VERSION ""

NS_ :

BS_:

BU_: TM

BO_ 370 BRAKE2: 8 Vector__XXX
 SG_ AebIntervention : 48|1@0+ (1,0) [0|1] ""  TM
 SG_ RCrankEnableStatus : 61|2@0+ (1,0) [0|3] ""  TM
 SG_ RCrankEnable : 0|1@0+ (1,0) [0|1] ""  TM
 SG_ BrkLightSig2Status : 59|2@0+ (1,0) [0|3] ""  TM
 SG_ BrkLightSig2 : 57|2@0+ (1,0) [0|3] ""  TM
 SG_ ABsActive : 1|1@0+ (1,0) [0|1] ""  TM
 SG_ TCsStatus : 3|2@0+ (1,0) [0|3] ""  TM
 SG_ TCsActive : 4|1@0+ (1,0) [0|1] ""  TM
 SG_ ESpStatus : 6|2@0+ (1,0) [0|3] ""  TM
 SG_ ESpActive : 7|1@0+ (1,0) [0|1] ""  TM
 SG_ NoGearshiftReqStatus : 9|2@0+ (1,0) [0|3] ""  TM
 SG_ NoGearshiftReq : 10|1@0+ (1,0) [0|1] ""  TM
 SG_ EBdStatus : 12|2@0+ (1,0) [0|3] ""  TM
 SG_ EBdActive : 13|1@0+ (1,0) [0|1] ""  TM
 SG_ ABsStatus : 15|2@0+ (1,0) [0|3] ""  TM
 SG_ CardanTrqLim : 23|14@0+ (0.25,-2048) [-2048|2047.75] "Nm"  TM
 SG_ CardanTrqLimStatus : 25|2@0+ (1,0) [0|3] ""  TM
 SG_ VehSpdSetHDC : 39|8@0+ (1,0) [0|254] "km"  TM
 SG_ HHcStatus : 41|2@0+ (1,0) [0|3] ""  TM
 SG_ BrkLightSigStatus : 43|2@0+ (1,0) [0|3] ""  TM
 SG_ BrkLightSig : 44|1@0+ (1,0) [0|1] ""  TM
 SG_ CruiseCntShutESPStatus : 46|2@0+ (1,0) [0|3] ""  TM
 SG_ CruiseCntShutESP : 47|1@0+ (1,0) [0|1] ""  TM
 SG_ HDcAvailability : 49|1@0+ (1,0) [0|1] ""  TM
 SG_ VehSpdSetHDCStatus : 51|2@0+ (1,0) [0|3] ""  TM
 SG_ HHcActive : 52|1@0+ (1,0) [0|1] ""  TM
 SG_ HDcActive : 53|1@0+ (1,0) [0|1] ""  TM
 SG_ HDcStatus : 55|2@0+ (1,0) [0|3] ""  TM

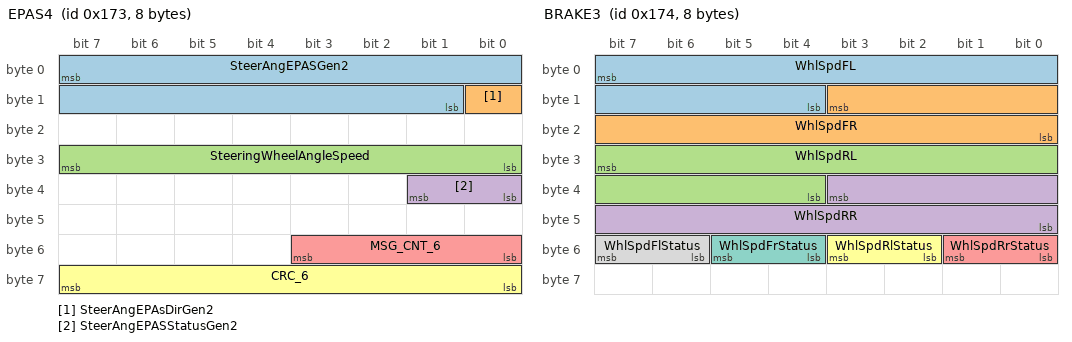
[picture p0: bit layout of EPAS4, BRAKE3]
BO_ 371 EPAS4: 8 Vector__XXX
 SG_ SteerAngEPASGen2 : 7|15@0+ (0.04375,0) [0|1433.55625] " deg"  TM
 SG_ SteerAngEPAsDirGen2 : 8|1@0+ (1,0) [0|1] ""  TM
 SG_ SteeringWheelAngleSpeed : 31|8@0+ (4,0) [0|255] "deg/s"  TM
 SG_ SteerAngEPASStatusGen2 : 33|2@0+ (1,0) [0|3] ""  TM
 SG_ MSG_CNT_6 : 51|4@0+ (1,0) [0|15] ""  TM
 SG_ CRC_6 : 63|8@0+ (1,0) [0|255] ""  TM

BO_ 372 BRAKE3: 8 Vector__XXX
 SG_ WhlSpdFL : 7|12@0+ (1,0) [0|4095] "rpm"  TM
 SG_ WhlSpdFR : 11|12@0+ (1,0) [0|4095] "rpm"  TM
 SG_ WhlSpdRL : 31|12@0+ (1,0) [0|4095] "rpm"  TM
 SG_ WhlSpdRR : 35|12@0+ (1,0) [0|4095] "rpm"  TM
 SG_ WhlSpdRrStatus : 49|2@0+ (1,0) [0|3] ""  TM
 SG_ WhlSpdRlStatus : 51|2@0+ (1,0) [0|3] ""  TM
 SG_ WhlSpdFrStatus : 53|2@0+ (1,0) [0|3] ""  TM
 SG_ WhlSpdFlStatus : 55|2@0+ (1,0) [0|3] ""  TM

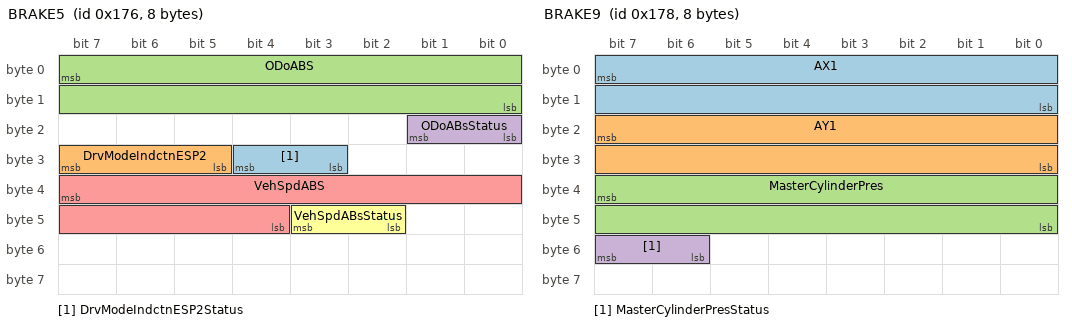
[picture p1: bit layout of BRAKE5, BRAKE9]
BO_ 374 BRAKE5: 8 Vector__XXX
 SG_ DrvModeIndctnESP2Status : 28|2@0+ (1,0) [0|3] ""  TM
 SG_ DrvModeIndctnESP2 : 31|3@0+ (1,0) [0|7] ""  TM
 SG_ ODoABS : 7|16@0+ (1,0) [0|65534] "m"  TM
 SG_ ODoABsStatus : 17|2@0+ (1,0) [0|3] ""  TM
 SG_ VehSpdABS : 39|12@0+ (0.03125,0) [0|127.96875] "m/s"  TM
 SG_ VehSpdABsStatus : 43|2@0+ (1,0) [0|3] ""  TM

BO_ 376 BRAKE9: 8 Vector__XXX
 SG_ AX1 : 7|16@0+ (0.0001,-3.2768) [-3.2768|3.2767] "g"  TM
 SG_ AY1 : 23|16@0+ (0.0001,-3.2768) [-3.2768|3.2767] "g"  TM
 SG_ MasterCylinderPres : 39|16@0+ (0.05,-40) [-40|400] "bar"  TM
 SG_ MasterCylinderPresStatus : 55|2@0+ (1,0) [0|3] ""  TM

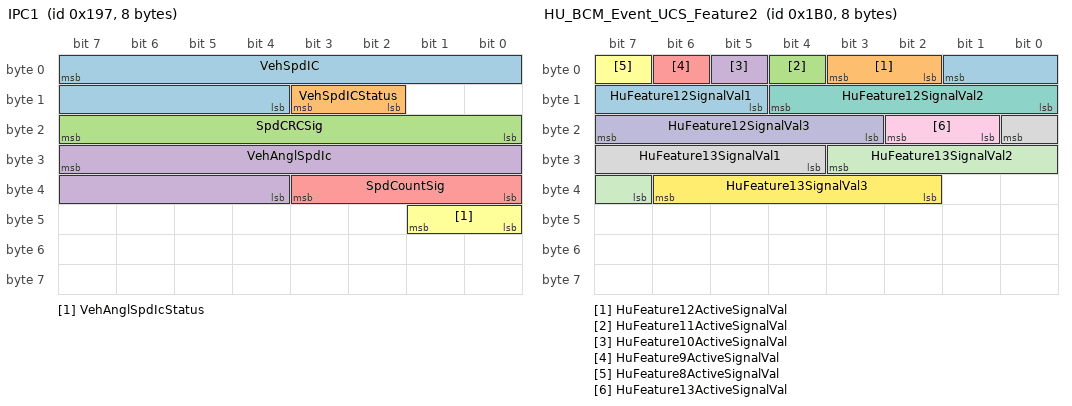
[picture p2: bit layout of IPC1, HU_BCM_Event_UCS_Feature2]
BO_ 407 IPC1: 8 Vector__XXX
 SG_ VehSpdIC : 7|12@0+ (0.03125,0) [0|127.96875] "m/s"  TM
 SG_ VehSpdICStatus : 11|2@0+ (1,0) [0|3] ""  TM
 SG_ SpdCRCSig : 23|8@0+ (1,0) [0|255] ""  TM
 SG_ VehAnglSpdIc : 31|12@0+ (1,0) [0|4095] "rpm"  TM
 SG_ SpdCountSig : 35|4@0+ (1,0) [0|15] ""  TM
 SG_ VehAnglSpdIcStatus : 41|2@0+ (1,0) [0|3] ""  TM

BO_ 432 HU_BCM_Event_UCS_Feature2: 8 Vector__XXX
 SG_ HuFeature12SignalVal1 : 1|5@0+ (10,0) [0|310] ""  TM
 SG_ HuFeature12ActiveSignalVal : 3|2@0+ (1,0) [0|3] ""  TM
 SG_ HuFeature11ActiveSignalVal : 4|1@0+ (1,0) [0|1] ""  TM
 SG_ HuFeature10ActiveSignalVal : 5|1@0+ (1,0) [0|1] ""  TM
 SG_ HuFeature9ActiveSignalVal : 6|1@0+ (1,0) [0|1] ""  TM
 SG_ HuFeature8ActiveSignalVal : 7|1@0+ (1,0) [0|1] ""  TM
 SG_ HuFeature12SignalVal2 : 12|5@0+ (10,0) [0|310] ""  TM
 SG_ HuFeature13SignalVal1 : 16|5@0+ (10,0) [0|310] ""  TM
 SG_ HuFeature13ActiveSignalVal : 18|2@0+ (1,0) [0|3] ""  TM
 SG_ HuFeature12SignalVal3 : 23|5@0+ (10,0) [0|310] ""  TM
 SG_ HuFeature13SignalVal2 : 27|5@0+ (10,0) [0|310] ""  TM
 SG_ HuFeature13SignalVal3 : 38|5@0+ (10,0) [0|310] ""  TM

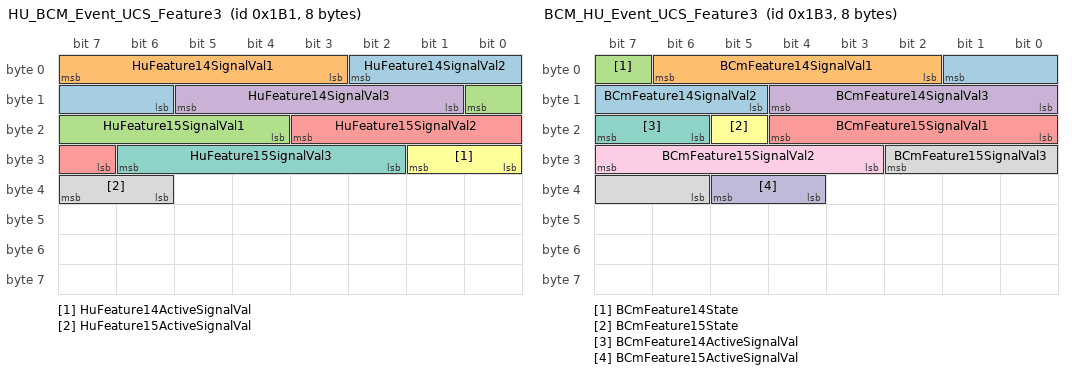
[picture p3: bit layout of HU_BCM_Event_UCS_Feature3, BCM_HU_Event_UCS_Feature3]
BO_ 433 HU_BCM_Event_UCS_Feature3: 8 Vector__XXX
 SG_ HuFeature14SignalVal2 : 2|5@0+ (10,0) [0|310] ""  TM
 SG_ HuFeature14SignalVal1 : 7|5@0+ (10,0) [0|310] ""  TM
 SG_ HuFeature15SignalVal1 : 8|5@0+ (10,0) [0|310] ""  TM
 SG_ HuFeature14SignalVal3 : 13|5@0+ (10,0) [0|310] ""  TM
 SG_ HuFeature15SignalVal2 : 19|5@0+ (10,0) [0|310] ""  TM
 SG_ HuFeature14ActiveSignalVal : 25|2@0+ (1,0) [0|3] ""  TM
 SG_ HuFeature15SignalVal3 : 30|5@0+ (10,0) [0|310] ""  TM
 SG_ HuFeature15ActiveSignalVal : 39|2@0+ (1,0) [0|3] ""  TM

BO_ 434 BCM_HU_Event_UCS_Feature2: 8 Vector__XXX
 SG_ BCmFeature11ActiveSignalVal : 0|1@0+ (1,0) [0|1] ""  TM
 SG_ BCmFeature11State : 1|1@0+ (1,0) [0|1] ""  TM
 SG_ BCmFeature10ActiveSignalVal : 2|1@0+ (1,0) [0|1] ""  TM
 SG_ BCmFeature10State : 3|1@0+ (1,0) [0|1] ""  TM
 SG_ BCmFeature9ActiveSignalVal : 4|1@0+ (1,0) [0|1] ""  TM
 SG_ BCmFeature9State : 5|1@0+ (1,0) [0|1] ""  TM
 SG_ BCmFeature8ActiveSignalVal : 6|1@0+ (1,0) [0|1] ""  TM
 SG_ BCmFeature8State : 7|1@0+ (1,0) [0|1] ""  TM
 SG_ BCmFeature12SignalVal2 : 9|5@0+ (10,0) [0|310] ""  TM
 SG_ BCmFeature12SignalVal1 : 14|5@0+ (10,0) [0|310] ""  TM
 SG_ BCmFeature12State : 15|1@0+ (1,0) [0|1] ""  TM
 SG_ BCmFeature12SignalVal3 : 20|5@0+ (10,0) [0|310] ""  TM
 SG_ BCmFeature13SignalVal1 : 28|5@0+ (10,0) [0|310] ""  TM
 SG_ BCmFeature13State : 29|1@0+ (1,0) [0|1] ""  TM
 SG_ BCmFeature12ActiveSignalVal : 31|2@0+ (1,0) [0|3] ""  TM
 SG_ BCmFeature13SignalVal3 : 34|5@0+ (10,0) [0|310] ""  TM
 SG_ BCmFeature13SignalVal2 : 39|5@0+ (10,0) [0|310] ""  TM
 SG_ BCmFeature13ActiveSignalVal : 45|2@0+ (1,0) [0|3] ""  TM

BO_ 435 BCM_HU_Event_UCS_Feature3: 8 Vector__XXX
 SG_ BCmFeature14SignalVal2 : 1|5@0+ (10,0) [0|310] ""  TM
 SG_ BCmFeature14SignalVal1 : 6|5@0+ (10,0) [0|310] ""  TM
 SG_ BCmFeature14State : 7|1@0+ (1,0) [0|1] ""  TM
 SG_ BCmFeature14SignalVal3 : 12|5@0+ (10,0) [0|310] ""  TM
 SG_ BCmFeature15SignalVal1 : 20|5@0+ (10,0) [0|310] ""  TM
 SG_ BCmFeature15State : 21|1@0+ (1,0) [0|1] ""  TM
 SG_ BCmFeature14ActiveSignalVal : 23|2@0+ (1,0) [0|3] ""  TM
 SG_ BCmFeature15SignalVal3 : 26|5@0+ (10,0) [0|310] ""  TM
 SG_ BCmFeature15SignalVal2 : 31|5@0+ (10,0) [0|310] ""  TM
 SG_ BCmFeature15ActiveSignalVal : 37|2@0+ (1,0) [0|3] ""  TM

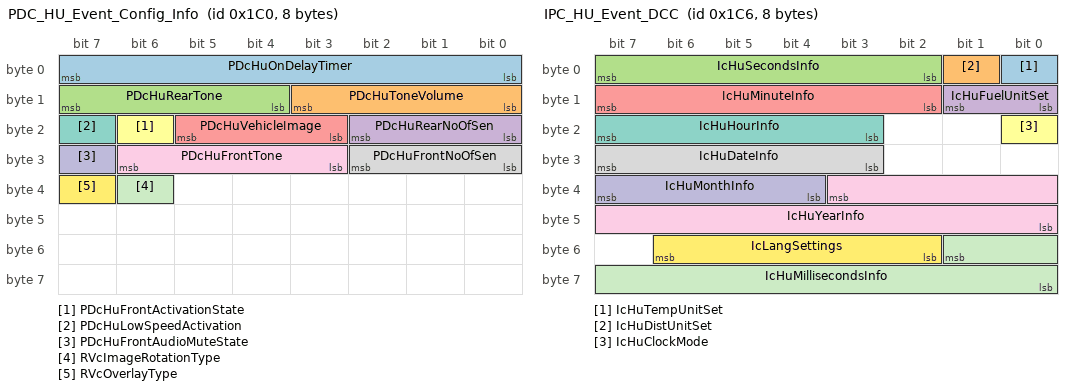
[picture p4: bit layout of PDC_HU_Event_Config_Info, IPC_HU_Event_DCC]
BO_ 448 PDC_HU_Event_Config_Info: 8 Vector__XXX
 SG_ PDcHuOnDelayTimer : 7|8@0+ (1,0) [0|255] "sec"  TM
 SG_ PDcHuToneVolume : 11|4@0+ (1,0) [0|15] ""  TM
 SG_ PDcHuRearTone : 15|4@0+ (1,0) [0|15] ""  TM
 SG_ PDcHuRearNoOfSen : 18|3@0+ (1,0) [0|7] ""  TM
 SG_ PDcHuVehicleImage : 21|3@0+ (1,0) [0|7] ""  TM
 SG_ PDcHuFrontActivationState : 22|1@0+ (1,0) [0|1] ""  TM
 SG_ PDcHuLowSpeedActivation : 23|1@0+ (1,0) [0|1] ""  TM
 SG_ PDcHuFrontNoOfSen : 26|3@0+ (1,0) [0|7] ""  TM
 SG_ PDcHuFrontTone : 30|4@0+ (1,0) [0|15] ""  TM
 SG_ PDcHuFrontAudioMuteState : 31|1@0+ (1,0) [0|1] ""  TM
 SG_ RVcImageRotationType : 38|1@0+ (1,0) [0|1] ""  TM
 SG_ RVcOverlayType : 39|1@0+ (1,0) [0|1] ""  TM

BO_ 451 IPC_VCIM_Event_OdoFullRange_RC: 8 Vector__XXX
 SG_ OdoICFullSig : 7|32@0+ (1,0) [0|999999000] "m"  TM

BO_ 454 IPC_HU_Event_DCC: 8 Vector__XXX
 SG_ IcHuTempUnitSet : 0|1@0+ (1,0) [0|1] ""  TM
 SG_ IcHuDistUnitSet : 1|1@0+ (1,0) [0|1] ""  TM
 SG_ IcHuSecondsInfo : 7|6@0+ (1,0) [0|59] "sec."  TM
 SG_ IcHuFuelUnitSet : 9|2@0+ (1,0) [0|3] ""  TM
 SG_ IcHuMinuteInfo : 15|6@0+ (1,0) [0|59] "min"  TM
 SG_ IcHuClockMode : 16|1@0+ (1,0) [0|1] ""  TM
 SG_ IcHuHourInfo : 23|5@0+ (1,0) [0|23] "hr"  TM
 SG_ IcHuDateInfo : 31|5@0+ (1,0) [0|31] ""  TM
 SG_ IcHuYearInfo : 35|12@0+ (1,0) [0|4095] ""  TM
 SG_ IcHuMonthInfo : 39|4@0+ (1,0) [0|15] ""  TM
 SG_ IcHuMillisecondsInfo : 49|10@0+ (1,0) [0|999] "ms"  TM
 SG_ IcLangSettings : 54|5@0+ (1,0) [0|31] ""  TM

BO_ 457 VICM_IPC_Event_OdoFullRange_RC: 8 Vector__XXX
 SG_ OdoVCIMFullSig : 7|32@0+ (1,0) [0|999999000] "m"  TM
 SG_ OdoICSigAckFrm : 34|1@0+ (1,0) [0|1] ""  TM

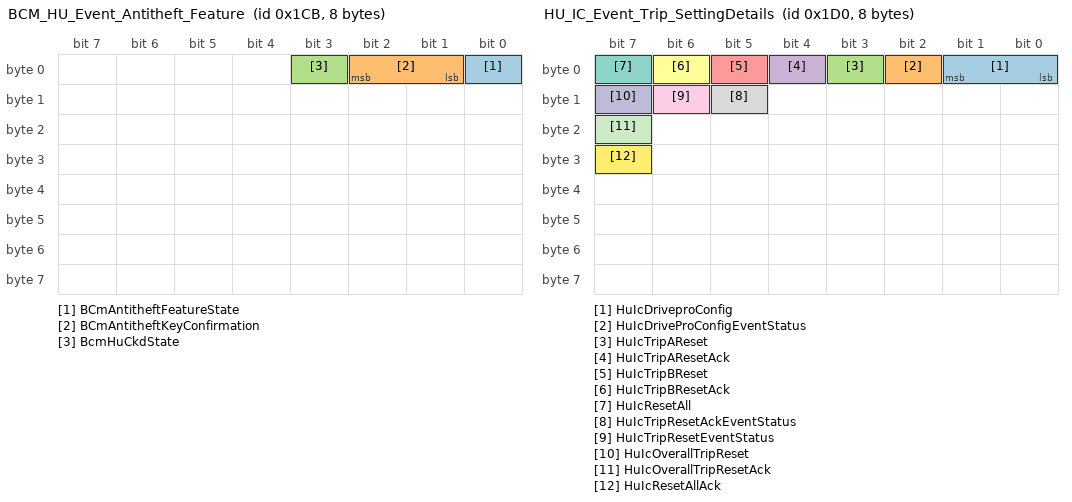
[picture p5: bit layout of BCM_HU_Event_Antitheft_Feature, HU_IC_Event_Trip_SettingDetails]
BO_ 459 BCM_HU_Event_Antitheft_Feature: 8 Vector__XXX
 SG_ BCmAntitheftFeatureState : 0|1@0+ (1,0) [0|1] ""  TM
 SG_ BCmAntitheftKeyConfirmation : 2|2@0+ (1,0) [0|3] ""  TM
 SG_ BcmHuCkdState : 3|1@0+ (1,0) [0|1] ""  TM

BO_ 460 HU_BCM_Event_Antitheft_Feature: 8 Vector__XXX
 SG_ HuAntitheftFeatureState : 0|1@0+ (1,0) [0|1] ""  TM
 SG_ HuBcmQueryInfo : 2|2@0+ (1,0) [0|3] ""  TM

BO_ 462 BCM_HU_Event_Antitheft_Seed: 8 Vector__XXX
 SG_ BCmAntitheftSeed : 7|32@0+ (1,0) [0|4294967295] ""  TM

BO_ 463 HU_BCM_Event_Antitheftkey: 8 Vector__XXX
 SG_ BCmAntitheftKey : 7|32@0+ (1,0) [0|4294967295] ""  TM

BO_ 464 HU_IC_Event_Trip_SettingDetails: 8 Vector__XXX
 SG_ HuIcDriveproConfig : 1|2@0+ (1,0) [0|3] ""  TM
 SG_ HuIcDriveProConfigEventStatus : 2|1@0+ (1,0) [0|1] ""  TM
 SG_ HuIcTripAReset : 3|1@0+ (1,0) [0|1] ""  TM
 SG_ HuIcTripAResetAck : 4|1@0+ (1,0) [0|1] ""  TM
 SG_ HuIcTripBReset : 5|1@0+ (1,0) [0|1] ""  TM
 SG_ HuIcTripBResetAck : 6|1@0+ (1,0) [0|1] ""  TM
 SG_ HuIcResetAll : 7|1@0+ (1,0) [0|1] ""  TM
 SG_ HuIcTripResetAckEventStatus : 13|1@0+ (1,0) [0|1] ""  TM
 SG_ HuIcTripResetEventStatus : 14|1@0+ (1,0) [0|1] ""  TM
 SG_ HuIcOverallTripReset : 15|1@0+ (1,0) [0|1] ""  TM
 SG_ HuIcOverallTripResetAck : 23|1@0+ (1,0) [0|1] ""  TM
 SG_ HuIcResetAllAck : 31|1@0+ (1,0) [0|1] ""  TM

BO_ 466 HU_PDC_Event: 8 Vector__XXX
 SG_ PDcOnDelayTimerReq : 7|8@0+ (1,0) [0|255] "sec"  TM
 SG_ HuPDcVehicleImageAck : 10|3@0+ (1,0) [0|7] ""  TM
 SG_ PDcLowSpeedActivationReq : 11|1@0+ (1,0) [0|1] ""  TM
 SG_ PDcRearToneReq : 15|4@0+ (1,0) [0|15] ""  TM
 SG_ HuPDcFrontAudioMuteStateAck : 16|1@0+ (1,0) [0|1] ""  TM
 SG_ HuPDcRearNoOfSensAck : 19|3@0+ (1,0) [0|7] ""  TM
 SG_ PDcToneVolumeReq : 23|4@0+ (1,0) [1|15] ""  TM
 SG_ HuPDcOnDelayTimerAck : 31|8@0+ (1,0) [0|255] "sec"  TM
 SG_ PDcFrontAudioMuteReq : 32|1@0+ (1,0) [0|1] ""  TM
 SG_ HuPDcReqType : 35|3@0+ (1,0) [0|7] ""  TM
 SG_ HuPDcRearToneAck : 39|4@0+ (1,0) [0|15] ""  TM
 SG_ HuPDcFrontToneAck : 43|4@0+ (1,0) [0|15] ""  TM
 SG_ HuPDcToneVolumeAck : 47|4@0+ (1,0) [0|15] ""  TM
 SG_ HuPDcFrontNoOfSensAck : 50|3@0+ (1,0) [0|7] ""  TM
 SG_ PDcFrontToneReq : 54|4@0+ (1,0) [0|15] ""  TM
 SG_ HuPDCFrontActivationStateAck : 55|1@0+ (1,0) [0|1] ""  TM
 SG_ PDcFrontActivationStateReq : 56|1@0+ (1,0) [0|1] ""  TM
 SG_ HuPDCLowSpeedActivationAck : 57|1@0+ (1,0) [0|1] ""  TM
 SG_ RVcOverlayTypeAck : 58|1@0+ (1,0) [0|1] ""  TM
 SG_ RVcImageRotationTypeAck : 59|1@0+ (1,0) [0|1] ""  TM

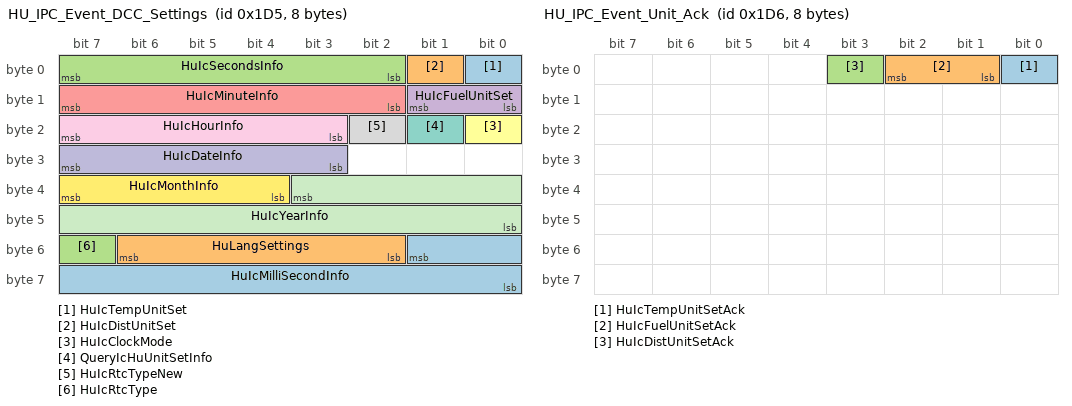
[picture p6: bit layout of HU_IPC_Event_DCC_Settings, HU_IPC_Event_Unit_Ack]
BO_ 469 HU_IPC_Event_DCC_Settings: 8 Vector__XXX
 SG_ HuIcTempUnitSet : 0|1@0+ (1,0) [0|1] ""  TM
 SG_ HuIcDistUnitSet : 1|1@0+ (1,0) [0|1] ""  TM
 SG_ HuIcSecondsInfo : 7|6@0+ (1,0) [0|59] "sec."  TM
 SG_ HuIcFuelUnitSet : 9|2@0+ (1,0) [0|3] ""  TM
 SG_ HuIcMinuteInfo : 15|6@0+ (1,0) [0|59] "min"  TM
 SG_ HuIcClockMode : 16|1@0+ (1,0) [0|1] ""  TM
 SG_ QueryIcHuUnitSetInfo : 17|1@0+ (1,0) [0|1] ""  TM
 SG_ HuIcRtcTypeNew : 18|1@0+ (1,0) [0|1] ""  TM
 SG_ HuIcHourInfo : 23|5@0+ (1,0) [0|23] "hr"  TM
 SG_ HuIcDateInfo : 31|5@0+ (1,0) [0|31] ""  TM
 SG_ HuIcYearInfo : 35|12@0+ (1,0) [0|4095] ""  TM
 SG_ HuIcMonthInfo : 39|4@0+ (1,0) [0|15] ""  TM
 SG_ HuIcMilliSecondInfo : 49|10@0+ (1,0) [0|999] "ms"  TM
 SG_ HuLangSettings : 54|5@0+ (1,0) [0|31] ""  TM
 SG_ HuIcRtcType : 55|1@0+ (1,0) [0|1] ""  TM

BO_ 470 HU_IPC_Event_Unit_Ack: 8 Vector__XXX
 SG_ HuIcTempUnitSetAck : 0|1@0+ (1,0) [0|1] ""  TM
 SG_ HuIcFuelUnitSetAck : 2|2@0+ (1,0) [0|3] ""  TM
 SG_ HuIcDistUnitSetAck : 3|1@0+ (1,0) [0|1] ""  TM

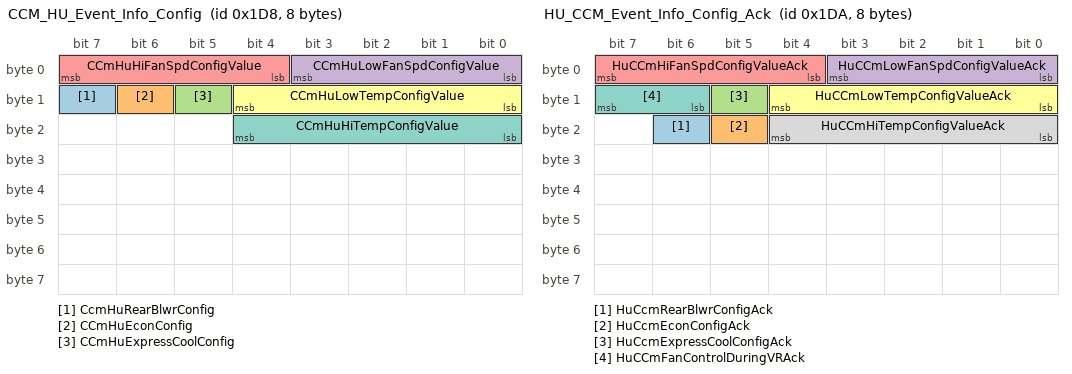
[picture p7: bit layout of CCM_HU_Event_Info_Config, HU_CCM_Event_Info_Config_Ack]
BO_ 472 CCM_HU_Event_Info_Config: 8 Vector__XXX
 SG_ CcmHuRearBlwrConfig : 15|1@0+ (1,0) [0|1] ""  TM
 SG_ CCmHuEconConfig : 14|1@0+ (1,0) [0|1] ""  TM
 SG_ CCmHuExpressCoolConfig : 13|1@0+ (1,0) [0|1] ""  TM
 SG_ CCmHuLowFanSpdConfigValue : 3|4@0+ (1,0) [0|15] ""  TM
 SG_ CCmHuHiFanSpdConfigValue : 7|4@0+ (1,0) [0|15] ""  TM
 SG_ CCmHuLowTempConfigValue : 12|5@0+ (0.5,0) [0|31] "Deg "  TM
 SG_ CCmHuHiTempConfigValue : 20|5@0+ (0.5,0) [0|31] "Deg "  TM

BO_ 474 HU_CCM_Event_Info_Config_Ack: 8 Vector__XXX
 SG_ HuCcmRearBlwrConfigAck : 22|1@0+ (1,0) [0|1] ""  TM
 SG_ HuCcmEconConfigAck : 21|1@0+ (1,0) [0|1] ""  TM
 SG_ HuCcmExpressCoolConfigAck : 13|1@0+ (1,0) [0|1] ""  TM
 SG_ HuCCmLowFanSpdConfigValueAck : 3|4@0+ (1,0) [0|15] ""  TM
 SG_ HuCCmHiFanSpdConfigValueAck : 7|4@0+ (1,0) [0|15] ""  TM
 SG_ HuCCmLowTempConfigValueAck : 12|5@0+ (0.5,0) [0|31] "Deg "  TM
 SG_ HuCCmFanControlDuringVRAck : 15|2@0+ (1,0) [0|3] ""  TM
 SG_ HuCCmHiTempConfigValueAck : 20|5@0+ (0.5,0) [0|31] "Deg "  TM

CM_ SG_ 370 AebIntervention "It indicates the AEB intervention by the ADAS system";
CM_ SG_ 370 RCrankEnableStatus "Status information of Remote Crank Signal";
CM_ SG_ 370 RCrankEnable "Remote crank  signal to  EMS.";
CM_ SG_ 370 BrkLightSig2Status "status information of BrkLightSig";
CM_ SG_ 370 BrkLightSig2 "Brake Light status signal is given by ABS / Esp to BCM for redundaent purpose";
CM_ SG_ 370 ABsActive "Indication that ABS / ESP system currently performs ABS intervention";
CM_ SG_ 370 TCsStatus "status information of TCs";
CM_ SG_ 370 TCsActive "Indication that ESP system currently performs TCS intervention";
CM_ SG_ 370 ESpStatus "status information of Esp
";
CM_ SG_ 370 ESpActive "Indication that ESP system currently performs an ESP intervention
";
CM_ SG_ 370 NoGearshiftReqStatus "status information of NoGearshiftReq
";
CM_ SG_ 370 NoGearshiftReq "Indication that ESP system inhibits automatic gear shift
";
CM_ SG_ 370 EBdStatus "status information of EBD
";
CM_ SG_ 370 EBdActive "Indication that ABS / ESP system currently performs EBD intervention
";
CM_ SG_ 370 ABsStatus "status information of ABs";
CM_ SG_ 370 CardanTrqLim "'Target cardan torque limit";
CM_ SG_ 370 CardanTrqLimStatus "Target cardan torque limit, status information";
CM_ SG_ 370 VehSpdSetHDC "HDC target speed set by the driver This signal is transmitted by ESP.  It is 'Package Protected' signal.

";
CM_ SG_ 370 HHcStatus "status information of HHc. It is 'Package Protected' signal.
";
CM_ SG_ 370 BrkLightSigStatus "status information of BrkLightSig";
CM_ SG_ 370 BrkLightSig "Brake Light status signal is given by ABS / Esp to BCM for redundaent purpose";
CM_ SG_ 370 CruiseCntShutESPStatus "ESP requested to EMS ECU for shut sown the cruise control function
";
CM_ SG_ 370 CruiseCntShutESP "ESP requested to EMS ECU for shut sown the cruise control function
";
CM_ SG_ 370 HDcAvailability "Indication that HDC system is available or not";
CM_ SG_ 370 VehSpdSetHDCStatus "status of HDC set speed. It is 'Package Protected' signal.";
CM_ SG_ 370 HHcActive "Indication that ESP system currently performs HHC intervention. It is 'Package Protected' signal.
";
CM_ SG_ 370 HDcActive "Indication that ESP system currently performs HDC intervention. It is 'Package Protected' signal.
";
CM_ SG_ 370 HDcStatus "status information of HDc. It is 'Package Protected' signal.
";
CM_ BO_ 371 "Frame to be enabled through DID for ADAS. ";
CM_ SG_ 371 SteerAngEPASGen2 "Steering Angle information can be used only for comfort function. It has ASIL B.";
CM_ SG_ 371 SteerAngEPAsDirGen2 "Steering wheel angle direction";
CM_ SG_ 371 SteeringWheelAngleSpeed "Steering Wheel Rotation Speed.";
CM_ SG_ 371 SteerAngEPASStatusGen2 "SAS angle status which is showing the plausibility of this signal";
CM_ SG_ 371 MSG_CNT_6 "MRC for entire message which consists of SteerAngEPAS, SteerAngEPAsDir, SteerAngEPASStatus";
CM_ SG_ 371 CRC_6 "CRC for entire message which consists of SteerAngEPAS, SteerAngEPAsDir, SteerAngEPASStatus";
CM_ SG_ 372 WhlSpdFL "Angular wheel speed signal transmitted by ABS and ESP ECU and will be given to EPAS & other
";
CM_ SG_ 372 WhlSpdFR "Angular wheel speed signal transmitted by ABS and ESP ECU and will be given to EPAS & other
";
CM_ SG_ 372 WhlSpdRL "Angular wheel speed signal transmitted by ABS and ESP ECU and will be given to EPAS & other
";
CM_ SG_ 372 WhlSpdRR "Angular wheel speed signal transmitted by ABS and ESP ECU and will be given to EPAS & other
";
CM_ SG_ 372 WhlSpdRrStatus "status information of WhlSpdRR
";
CM_ SG_ 372 WhlSpdRlStatus "status information of WhlSpdRL
";
CM_ SG_ 372 WhlSpdFrStatus "status information of WhlSpdFR 
";
CM_ SG_ 372 WhlSpdFlStatus "status information of WhlSpdFL";
CM_ SG_ 374 DrvModeIndctnESP2Status "Status of the Drive mode indication ESP signal. It is 'Package Protected' signal.";
CM_ SG_ 374 DrvModeIndctnESP2 "Information is sent from ESP to EMS,BCM,IPC and HU indicating that it has switched to the corresponding mode.";
CM_ SG_ 374 ODoABS "Mileage counter for odometer evaluated by ABS and ESP ECU and will be given to IC
";
CM_ SG_ 374 ODoABsStatus "status information of ODoABs";
CM_ SG_ 374 VehSpdABS "vehicle speed signal calculated by ABS and ESP ECU and will be given to IC

";
CM_ SG_ 374 VehSpdABsStatus "status information of VehSpdABs";
CM_ SG_ 376 AX1 "Longitudinal accelaration information";
CM_ SG_ 376 AY1 "Lateral accelaration information";
CM_ SG_ 376 MasterCylinderPres "Master cylinder pressure";
CM_ SG_ 376 MasterCylinderPresStatus "Master cylinder pressure signal status";
CM_ SG_ 407 VehSpdIC "Signal represents Vehicle Speed evaluated by Instrument Cluster";
CM_ SG_ 407 VehSpdICStatus "Signal represents Status of Vehicle Speed Signal";
CM_ SG_ 407 SpdCRCSig "Signal represents CRC of the message.";
CM_ SG_ 407 VehAnglSpdIc "vehilce speed evaluated by EMS and transmitted in angular format
TCU uses this signal to check shift point & plausibility against other siganls";
CM_ SG_ 407 SpdCountSig "Signal represents Message counter to indicate message has not freezed.";
CM_ SG_ 407 VehAnglSpdIcStatus "Signal represents Status of Vehicle angular Speed Signal";
CM_ SG_ 448 PDcHuOnDelayTimer "On evey ignition ON, delay timer info is send as an input to HU .
";
CM_ SG_ 448 PDcHuToneVolume "On evey ignition ON, tone volume info for rear PDC  is send as an input to HU";
CM_ SG_ 448 PDcHuRearTone "This signal is used as an input to the HU for any change in the rear tone setting done by the user.";
CM_ SG_ 448 PDcHuRearNoOfSen "On every IGN ON, PDC shall publish its rear number of sensor status to HU.";
CM_ SG_ 448 PDcHuVehicleImage "On every IGN ON, PDC shall publish vehicle images to HU.";
CM_ SG_ 448 PDcHuFrontActivationState "This signal is used an input from BCM to HU to know Front PDC function is Active/Deactive state .";
CM_ SG_ 448 PDcHuLowSpeedActivation "This signal is used as an input from BCM to HU to know front PDC function for Low speed activation is active/deactive";
CM_ SG_ 448 PDcHuFrontNoOfSen "On every IGN ON, BCM shall publish its Front number of sensor status to HU.";
CM_ SG_ 448 PDcHuFrontTone "This signal is used as an input to the HU for any change in the Front tone setting done by the user.";
CM_ SG_ 448 PDcHuFrontAudioMuteState "On every IGN ON, BCM shall publish its rear number of sensor status to HU.";
CM_ SG_ 448 RVcImageRotationType "This signal is used as an input from BCM to HU to know the image rotation type";
CM_ SG_ 448 RVcOverlayType "This signal is used as an input from BCM to HU to know the type of RVC overlay";
CM_ SG_ 451 OdoICFullSig "Signal represents Odometer information in full range.This information is used by VICM for Odometer learning.";
CM_ SG_ 454 IcHuTempUnitSet "Temp unit send by IC to HU.";
CM_ SG_ 454 IcHuDistUnitSet "Distance Unit send by IC to HU.";
CM_ SG_ 454 IcHuSecondsInfo "Status of Seconds Information";
CM_ SG_ 454 IcHuFuelUnitSet "Fuel Unit send by IC to HU.";
CM_ SG_ 454 IcHuMinuteInfo "Minute Information on HU from IC";
CM_ SG_ 454 IcHuClockMode "Clock Mode Information on HU from IC.";
CM_ SG_ 454 IcHuHourInfo "Hour Information on HU from IC";
CM_ SG_ 454 IcHuDateInfo "Date Information on HU from IC.";
CM_ SG_ 454 IcHuYearInfo "Year Information on HU from IC";
CM_ SG_ 454 IcHuMonthInfo "Month Information on HU from IC.";
CM_ SG_ 454 IcHuMillisecondsInfo "MilliSeconds Information on HU from IC.";
CM_ SG_ 454 IcLangSettings "IC shall publish language settings information to HU.(Not to be implemented in D and E Variant ) ";
CM_ SG_ 457 OdoVCIMFullSig "Signal represents Odometer information in full range.This information is used by IC for automatic odometer updation";
CM_ SG_ 457 OdoICSigAckFrm "Signal Represents whether Odometer Storage was successfull or failure";
CM_ SG_ 459 BCmAntitheftFeatureState "This signal is output from BCM  to identify HU Anti-theft feature activation/ deactivation state.";
CM_ SG_ 459 BCmAntitheftKeyConfirmation "BCM send this signal to HU for key confirmation state.";
CM_ SG_ 459 BcmHuCkdState "BCM send the type of vehicle (i.e. CKD or Non-CKD) to HU.";
CM_ SG_ 460 HuAntitheftFeatureState "This signal is input to BCM  to identify HU Anti-theft feature activation / deactivation state.";
CM_ SG_ 460 HuBcmQueryInfo "On IGN ON, if HU doesnot get BcmAntitheftFeatureState from BCM, then HU sends the query to BCM to restart the pairing process.Also during pairing process, if HU doesn¿t receive SEED from BCM, then HU sends the query to BCM to restart the pairing process.";
CM_ BO_ 462 "This signal is output from BCM  to identify HU Anti-theft feature activation/ deactivation state.";
CM_ SG_ 462 BCmAntitheftSeed "BCM send this signal to Infotainment ECU for seed information state.";
CM_ SG_ 463 BCmAntitheftKey "BCM receives this signal from HU to know the key information state.";
CM_ SG_ 464 HuIcDriveproConfig "HU shall send Drive Pro Config to IC";
CM_ SG_ 464 HuIcDriveProConfigEventStatus "HU shall send Trip Config Event Status to IC";
CM_ SG_ 464 HuIcTripAReset "HU shall send Trip A Reset to IC";
CM_ SG_ 464 HuIcTripAResetAck "HU shall send Trip A Reset Ack to IC";
CM_ SG_ 464 HuIcTripBReset "HU shall send Trip B Reset to IC";
CM_ SG_ 464 HuIcTripBResetAck "HU shall send Trip B Reset Ack to IC";
CM_ SG_ 464 HuIcResetAll "HU shall send Reset All to IC";
CM_ SG_ 464 HuIcTripResetAckEventStatus "HU shall send Trip Reset Ack Event Status to IC";
CM_ SG_ 464 HuIcTripResetEventStatus "HU shall send Trip Reset Event Status to IC";
CM_ SG_ 464 HuIcOverallTripReset "HU shall send Overall trip Reset to IC";
CM_ SG_ 464 HuIcOverallTripResetAck "HU shall send overall Trip Reset Ack to IC";
CM_ SG_ 464 HuIcResetAllAck "HU shall send All Trip Reset Ack to IC";
CM_ SG_ 466 PDcOnDelayTimerReq "This input signal to PDC is to update PDC Delay Timer settings.
";
CM_ SG_ 466 HuPDcVehicleImageAck "On every IGN ON, HU shall acknowledge to  PDC's config info.";
CM_ SG_ 466 PDcLowSpeedActivationReq "This input signal to PDC is to update the low speed activation request";
CM_ SG_ 466 PDcRearToneReq "This input signal to PDC is to update PDC Tone selection settings.";
CM_ SG_ 466 HuPDcFrontAudioMuteStateAck "On every IGN ON, HU shall acknowledge to  front PDC's config info.";
CM_ SG_ 466 HuPDcRearNoOfSensAck "On every IGN ON, HU shall acknowledge to  PDC's config info.";
CM_ SG_ 466 PDcToneVolumeReq "This input signal to PDC is to update PDC Tone Volume settings.";
CM_ SG_ 466 HuPDcOnDelayTimerAck "On every IGN ON, HU shall acknowledge to  PDC's config info. .
";
CM_ SG_ 466 PDcFrontAudioMuteReq "This input signal to PDC is to update the front  mute status.";
CM_ SG_ 466 HuPDcReqType "this input signal is to PDC is to know the request type from HU";
CM_ SG_ 466 HuPDcRearToneAck "On every IGN ON, HU shall acknowledge to  PDC's config info.";
CM_ SG_ 466 HuPDcFrontToneAck "On every IGN ON, HU shall acknowledge to  front PDC's config info.";
CM_ SG_ 466 HuPDcToneVolumeAck "On every IGN ON, HU shall acknowledge to  PDC's config info.";
CM_ SG_ 466 HuPDcFrontNoOfSensAck "On every IGN ON, HU shall acknowledge to front PDC's config info.";
CM_ SG_ 466 PDcFrontToneReq "This input signal to BCM PDC fucntion is to update PDC Tone selection status.";
CM_ SG_ 466 HuPDCFrontActivationStateAck "This signal is used an input from HU shall to acknowledge front PDC activation state acknowledgement";
CM_ SG_ 466 PDcFrontActivationStateReq "This signal is used an input from HU shall to acknowledge front PDC activation state acknowledgement";
CM_ SG_ 466 HuPDCLowSpeedActivationAck "This signal is used an input from HU shall to acknowledge low speed activation acknowledgement";
CM_ SG_ 466 RVcOverlayTypeAck "This signal is used as an input from HU to acknowledge the RVC overlay";
CM_ SG_ 466 RVcImageRotationTypeAck "This signal is used as an input from HU to acknowledge image roation type";
CM_ SG_ 469 HuIcTempUnitSet "Temp unit send by HU to IC.";
CM_ SG_ 469 HuIcDistUnitSet "Distance Unit send by HU to IC.";
CM_ SG_ 469 HuIcSecondsInfo "Seconds Information on IC from HU.";
CM_ SG_ 469 HuIcFuelUnitSet "Fuel Unit send by HU to IC.";
CM_ SG_ 469 HuIcMinuteInfo "Minute Information on IC from HU";
CM_ SG_ 469 HuIcClockMode "Clock Mode Information on IC from HU.";
CM_ SG_ 469 QueryIcHuUnitSetInfo "Query by HU to IC.";
CM_ SG_ 469 HuIcRtcTypeNew "Clock Mode Information on IC from HU";
CM_ SG_ 469 HuIcHourInfo "Hour Information on IC from HU.";
CM_ SG_ 469 HuIcDateInfo "Date Information on IC from HU.";
CM_ SG_ 469 HuIcYearInfo "Year Information on IC from HU";
CM_ SG_ 469 HuIcMonthInfo "Month Information on HU from IC.";
CM_ SG_ 469 HuIcMilliSecondInfo "milliseconds Information on IC from HU.";
CM_ SG_ 469 HuLangSettings "HU shall publish language settings information to IPC.";
CM_ SG_ 469 HuIcRtcType "Clock Mode Information on IC from HU";
CM_ SG_ 470 HuIcTempUnitSetAck "Temp unit send by HU to IC.";
CM_ SG_ 470 HuIcFuelUnitSetAck "Fuel acknowledgement send by HU to IC.";
CM_ SG_ 470 HuIcDistUnitSetAck "Distance acknowledgement send by HU to IC";
CM_ SG_ 472 CcmHuRearBlwrConfig "Indicates the availability of Rear Blower feature.";
CM_ SG_ 472 CCmHuEconConfig "Indicates the availability of ECON feature for the ECU under consideration";
CM_ SG_ 472 CCmHuExpressCoolConfig "Indicates the availability of Express cooling feature for the ECU under consideration";
CM_ SG_ 472 CCmHuLowFanSpdConfigValue "Indicates the lower configuration fan speed value for the ECU under consideration";
CM_ SG_ 472 CCmHuHiFanSpdConfigValue "Indicates the higher configuration fan speed value for the ECU under consideration";
CM_ SG_ 472 CCmHuLowTempConfigValue "Indicates the lower configuration temperature value for the ECU under consideration(physical range shall be considered as LO,16 to 30,HI)";
CM_ SG_ 472 CCmHuHiTempConfigValue "Indicates the higher configuration temperature value for the ECU under consideration(physical range shall be considered as LO,16 to 30,HI)";
CM_ SG_ 474 HuCcmRearBlwrConfigAck "HU Acknowledges the Rear Blower feature availability configuartion value for the ECU under consideration.";
CM_ SG_ 474 HuCcmEconConfigAck "HU Acknowledges the ECON feature availability configuartion value for the ECU under consideration";
CM_ SG_ 474 HuCcmExpressCoolConfigAck "HU Acknowledges the express cooling feature availability configuartion value for the ECU under consideration";
CM_ SG_ 474 HuCCmLowFanSpdConfigValueAck "Acknowledge  the lower configuration fan speed value for the ECU under consideration";
CM_ SG_ 474 HuCCmHiFanSpdConfigValueAck "Acknowledge the higher configuration fan speed value for the ECU under consideration";
CM_ SG_ 474 HuCCmLowTempConfigValueAck "Acknowledge  the lower configuration temperature value for the ECU under consideration";
CM_ SG_ 474 HuCCmFanControlDuringVRAck "Acknowledge from HU to CCM for FAN speed control";
CM_ SG_ 474 HuCCmHiTempConfigValueAck "Acknowledge  the higher configuration temperature value for the ECU under consideration";
BA_DEF_ SG_  "Remarks" STRING ;
BA_DEF_ SG_  "NWM_WakeupAllowed" ENUM  "No","Yes";
BA_DEF_ SG_  "GenSigTimeoutTime_HU_Mid_X451" INT 0 65535;
BA_DEF_ SG_  "GenSigTimeoutTime_HU_High_X451" INT 0 65535;
BA_DEF_ SG_  "GenSigTimeoutTime_HU_B" INT 0 65535;
BA_DEF_ SG_  "GenSigTimeoutTime_HU_A" INT 0 65535;
BA_DEF_ SG_  "GenSigTimeoutTime_BCM_Mid" INT 0 65535;
BA_DEF_ SG_  "GenSigTimeoutMsg_HU_Mid_X451" INT 0 65535;
BA_DEF_ SG_  "GenSigTimeoutMsg_HU_High_X451" INT 0 65535;
BA_DEF_ SG_  "GenSigTimeoutMsg_HU_B" INT 0 65535;
BA_DEF_ SG_  "GenSigTimeoutMsg_HU_A" INT 0 65535;
BA_DEF_ SG_  "GenSigStartValue" INT 0 0;
BA_DEF_ SG_  "GenSigSendType" ENUM  "Cyclic","OnWrite","OnWriteWithRepetition","OnChange","OnChangeWithRepetition","IfActive","IfActiveWithRepetition","NoSigSendType","NotUsed","NotUsed","NotUsed","NotUsed","NotUsed";
BA_DEF_ SG_  "GenSigInactiveValue" INT 0 0;
BA_DEF_ SG_  "GenSigEnvVarType" ENUM  "int","float","undef";
BA_DEF_ SG_  "GenSigCycleTimeActive" INT 0 0;
BA_DEF_ SG_  "GenSigCycleTime" INT 0 0;
BA_DEF_ SG_  "GenSigTimeoutMsg_HU_High_X445" INT 0 65535;
BA_DEF_ SG_  "GenSigTimeoutMsg_HU_Mid_X445" INT 0 65535;
BA_DEF_ SG_  "GenSigTimeoutTime_HU_High_X445" INT 0 65535;
BA_DEF_ SG_  "GenSigTimeoutTime_HU_Mid_X445" INT 0 65535;
BA_DEF_ SG_  "GenSigTimeoutMsg_IVI" INT 0 65535;
BA_DEF_ SG_  "GenSigTimeoutTime_IVI" INT 0 65535;
BA_DEF_ BO_  "NmMessage" ENUM  "no","yes";
BA_DEF_ BO_  "NmAsrMessage" ENUM  "<n.a.>","No","Yes";
BA_DEF_ BO_  "MessageTimeout" INT 0 65535;
BA_DEF_ BO_  "Me" INT 0 0;
BA_DEF_ BO_  "GenMsgStartDelayTime" INT 0 0;
BA_DEF_ BO_  "GenMsgSendType" ENUM  "Cyclic","NotUsed","NotUsed","NotUsed","NotUsed","NotUsed","NotUsed","IfActive","NoMsgSendType","NotUsed";
BA_DEF_ BO_  "GenMsgNrOfRepetition" INT 0 0;
BA_DEF_ BO_  "GenMsgILSupport" ENUM  "No","Yes";
BA_DEF_ BO_  "GenMsgDelayTime" INT 0 0;
BA_DEF_ BO_  "GenMsgCycleTimeFast" INT 0 0;
BA_DEF_ BO_  "GenMsgCycleTime" INT 0 0;
BA_DEF_ BO_  "DiagUudtResponse" ENUM  "false","true";
BA_DEF_ BO_  "DiagUsdtResponse" ENUM  "false","true";
BA_DEF_ BO_  "DiagState" ENUM  "No","Yes";
BA_DEF_ BO_  "DiagResponse" ENUM  "No","Yes";
BA_DEF_ BO_  "DiagRequest" ENUM  "No","Yes";
BA_DEF_ BO_  "MsgType" ENUM  "Application","NM","NMH";
BA_DEF_ SG_  "SystemSignalLongSymbol" STRING ;
BA_DEF_DEF_  "Remarks" "null";
BA_DEF_DEF_  "NWM_WakeupAllowed" "No";
BA_DEF_DEF_  "GenSigTimeoutTime_HU_Mid_X451" 500;
BA_DEF_DEF_  "GenSigTimeoutTime_HU_High_X451" 500;
BA_DEF_DEF_  "GenSigTimeoutTime_HU_B" 500;
BA_DEF_DEF_  "GenSigTimeoutTime_HU_A" 500;
BA_DEF_DEF_  "GenSigTimeoutTime_BCM_Mid" 0;
BA_DEF_DEF_  "GenSigTimeoutMsg_HU_Mid_X451" 500;
BA_DEF_DEF_  "GenSigTimeoutMsg_HU_High_X451" 500;
BA_DEF_DEF_  "GenSigTimeoutMsg_HU_B" 500;
BA_DEF_DEF_  "GenSigTimeoutMsg_HU_A" 500;
BA_DEF_DEF_  "GenSigStartValue" 0;
BA_DEF_DEF_  "GenSigSendType" "Cyclic";
BA_DEF_DEF_  "GenSigInactiveValue" 0;
BA_DEF_DEF_  "GenSigEnvVarType" "undef";
BA_DEF_DEF_  "GenSigCycleTimeActive" 0;
BA_DEF_DEF_  "GenSigCycleTime" 0;
BA_DEF_DEF_  "GenSigTimeoutMsg_HU_High_X445" 500;
BA_DEF_DEF_  "GenSigTimeoutMsg_HU_Mid_X445" 500;
BA_DEF_DEF_  "GenSigTimeoutTime_HU_High_X445" 500;
BA_DEF_DEF_  "GenSigTimeoutTime_HU_Mid_X445" 500;
BA_DEF_DEF_  "GenSigTimeoutMsg_IVI" 500;
BA_DEF_DEF_  "GenSigTimeoutTime_IVI" 500;
BA_DEF_DEF_  "NmMessage" "no";
BA_DEF_DEF_  "NmAsrMessage" "<n.a.>";
BA_DEF_DEF_  "MessageTimeout" 500;
BA_DEF_DEF_  "Me" 0;
BA_DEF_DEF_  "GenMsgStartDelayTime" 0;
BA_DEF_DEF_  "GenMsgSendType" "Cyclic";
BA_DEF_DEF_  "GenMsgNrOfRepetition" 0;
BA_DEF_DEF_  "GenMsgILSupport" "Yes";
BA_DEF_DEF_  "GenMsgDelayTime" 0;
BA_DEF_DEF_  "GenMsgCycleTimeFast" 0;
BA_DEF_DEF_  "GenMsgCycleTime" 0;
BA_DEF_DEF_  "DiagUudtResponse" "false";
BA_DEF_DEF_  "DiagUsdtResponse" "false";
BA_DEF_DEF_  "DiagState" "No";
BA_DEF_DEF_  "DiagResponse" "No";
BA_DEF_DEF_  "DiagRequest" "No";
BA_DEF_DEF_  "MsgType" "Application";
BA_DEF_DEF_  "SystemSignalLongSymbol" "";
BA_ "GenMsgCycleTime" BO_ 370 20;
BA_ "GenMsgCycleTime" BO_ 371 20;
BA_ "GenMsgCycleTime" BO_ 372 20;
BA_ "GenMsgCycleTime" BO_ 374 20;
BA_ "GenMsgCycleTime" BO_ 376 20;
BA_ "GenMsgCycleTime" BO_ 407 20;
BA_ "MessageTimeout" BO_ 432 0;
BA_ "GenMsgSendType" BO_ 432 8;
BA_ "MessageTimeout" BO_ 433 0;
BA_ "GenMsgSendType" BO_ 433 8;
BA_ "MessageTimeout" BO_ 434 0;
BA_ "GenMsgSendType" BO_ 434 8;
BA_ "MessageTimeout" BO_ 435 0;
BA_ "GenMsgSendType" BO_ 435 8;
BA_ "MessageTimeout" BO_ 448 0;
BA_ "GenMsgSendType" BO_ 448 8;
BA_ "MessageTimeout" BO_ 451 0;
BA_ "GenMsgSendType" BO_ 451 8;
BA_ "GenMsgNrOfRepetition" BO_ 451 3;
BA_ "GenMsgDelayTime" BO_ 451 60;
BA_ "MessageTimeout" BO_ 454 0;
BA_ "GenMsgSendType" BO_ 454 8;
BA_ "MessageTimeout" BO_ 457 0;
BA_ "GenMsgSendType" BO_ 457 8;
BA_ "GenMsgNrOfRepetition" BO_ 457 1;
BA_ "MessageTimeout" BO_ 459 0;
BA_ "GenMsgSendType" BO_ 459 8;
BA_ "MessageTimeout" BO_ 460 0;
BA_ "GenMsgSendType" BO_ 460 8;
BA_ "MessageTimeout" BO_ 462 0;
BA_ "GenMsgSendType" BO_ 462 8;
BA_ "MessageTimeout" BO_ 463 0;
BA_ "GenMsgSendType" BO_ 463 8;
BA_ "MessageTimeout" BO_ 464 0;
BA_ "GenMsgSendType" BO_ 464 8;
BA_ "MessageTimeout" BO_ 466 0;
BA_ "GenMsgSendType" BO_ 466 8;
BA_ "MessageTimeout" BO_ 469 0;
BA_ "GenMsgSendType" BO_ 469 8;
BA_ "MessageTimeout" BO_ 470 0;
BA_ "GenMsgSendType" BO_ 470 8;
BA_ "MessageTimeout" BO_ 472 0;
BA_ "GenMsgSendType" BO_ 472 8;
BA_ "MessageTimeout" BO_ 474 0;
BA_ "GenMsgSendType" BO_ 474 8;
BA_ "GenSigSendType" SG_ 370 AebIntervention 7;
BA_ "GenSigCycleTimeActive" SG_ 370 AebIntervention 20;
BA_ "GenSigCycleTime" SG_ 370 AebIntervention 20;
BA_ "GenSigTimeoutTime_HU_B" SG_ 370 RCrankEnableStatus 0;
BA_ "GenSigTimeoutTime_HU_A" SG_ 370 RCrankEnableStatus 0;
BA_ "GenSigTimeoutMsg_HU_B" SG_ 370 RCrankEnableStatus 0;
BA_ "GenSigTimeoutMsg_HU_A" SG_ 370 RCrankEnableStatus 0;
BA_ "GenSigSendType" SG_ 370 RCrankEnableStatus 7;
BA_ "GenSigCycleTimeActive" SG_ 370 RCrankEnableStatus 20;
BA_ "GenSigCycleTime" SG_ 370 RCrankEnableStatus 20;
BA_ "GenSigTimeoutTime_HU_B" SG_ 370 RCrankEnable 0;
BA_ "GenSigTimeoutTime_HU_A" SG_ 370 RCrankEnable 0;
BA_ "GenSigTimeoutMsg_HU_B" SG_ 370 RCrankEnable 0;
BA_ "GenSigTimeoutMsg_HU_A" SG_ 370 RCrankEnable 0;
BA_ "GenSigSendType" SG_ 370 RCrankEnable 7;
BA_ "GenSigCycleTimeActive" SG_ 370 RCrankEnable 20;
BA_ "GenSigCycleTime" SG_ 370 RCrankEnable 20;
BA_ "GenSigTimeoutTime_HU_B" SG_ 370 BrkLightSig2Status 0;
BA_ "GenSigTimeoutTime_HU_A" SG_ 370 BrkLightSig2Status 0;
BA_ "GenSigTimeoutMsg_HU_B" SG_ 370 BrkLightSig2Status 0;
BA_ "GenSigTimeoutMsg_HU_A" SG_ 370 BrkLightSig2Status 0;
BA_ "GenSigSendType" SG_ 370 BrkLightSig2Status 7;
BA_ "GenSigCycleTimeActive" SG_ 370 BrkLightSig2Status 20;
BA_ "GenSigCycleTime" SG_ 370 BrkLightSig2Status 20;
BA_ "GenSigTimeoutTime_HU_B" SG_ 370 BrkLightSig2 0;
BA_ "GenSigTimeoutTime_HU_A" SG_ 370 BrkLightSig2 0;
BA_ "GenSigTimeoutMsg_HU_B" SG_ 370 BrkLightSig2 0;
BA_ "GenSigTimeoutMsg_HU_A" SG_ 370 BrkLightSig2 0;
BA_ "GenSigSendType" SG_ 370 BrkLightSig2 7;
BA_ "GenSigCycleTimeActive" SG_ 370 BrkLightSig2 20;
BA_ "GenSigCycleTime" SG_ 370 BrkLightSig2 20;
BA_ "GenSigSendType" SG_ 370 ABsActive 7;
BA_ "GenSigCycleTimeActive" SG_ 370 ABsActive 20;
BA_ "GenSigCycleTime" SG_ 370 ABsActive 20;
BA_ "GenSigSendType" SG_ 370 TCsStatus 7;
BA_ "GenSigCycleTimeActive" SG_ 370 TCsStatus 20;
BA_ "GenSigCycleTime" SG_ 370 TCsStatus 20;
BA_ "GenSigSendType" SG_ 370 TCsActive 7;
BA_ "GenSigCycleTimeActive" SG_ 370 TCsActive 20;
BA_ "GenSigCycleTime" SG_ 370 TCsActive 20;
BA_ "GenSigSendType" SG_ 370 ESpStatus 7;
BA_ "GenSigCycleTimeActive" SG_ 370 ESpStatus 20;
BA_ "GenSigCycleTime" SG_ 370 ESpStatus 20;
BA_ "GenSigSendType" SG_ 370 ESpActive 7;
BA_ "GenSigCycleTimeActive" SG_ 370 ESpActive 20;
BA_ "GenSigCycleTime" SG_ 370 ESpActive 20;
BA_ "GenSigTimeoutTime_HU_B" SG_ 370 NoGearshiftReqStatus 0;
BA_ "GenSigTimeoutTime_HU_A" SG_ 370 NoGearshiftReqStatus 0;
BA_ "GenSigTimeoutMsg_HU_B" SG_ 370 NoGearshiftReqStatus 0;
BA_ "GenSigTimeoutMsg_HU_A" SG_ 370 NoGearshiftReqStatus 0;
BA_ "GenSigSendType" SG_ 370 NoGearshiftReqStatus 7;
BA_ "GenSigCycleTimeActive" SG_ 370 NoGearshiftReqStatus 20;
BA_ "GenSigCycleTime" SG_ 370 NoGearshiftReqStatus 20;
BA_ "GenSigTimeoutTime_HU_B" SG_ 370 NoGearshiftReq 0;
BA_ "GenSigTimeoutTime_HU_A" SG_ 370 NoGearshiftReq 0;
BA_ "GenSigTimeoutMsg_HU_B" SG_ 370 NoGearshiftReq 0;
BA_ "GenSigTimeoutMsg_HU_A" SG_ 370 NoGearshiftReq 0;
BA_ "GenSigSendType" SG_ 370 NoGearshiftReq 7;
BA_ "GenSigCycleTimeActive" SG_ 370 NoGearshiftReq 20;
BA_ "GenSigCycleTime" SG_ 370 NoGearshiftReq 20;
BA_ "GenSigSendType" SG_ 370 EBdStatus 7;
BA_ "GenSigCycleTimeActive" SG_ 370 EBdStatus 20;
BA_ "GenSigCycleTime" SG_ 370 EBdStatus 20;
BA_ "GenSigSendType" SG_ 370 EBdActive 7;
BA_ "GenSigCycleTimeActive" SG_ 370 EBdActive 20;
BA_ "GenSigCycleTime" SG_ 370 EBdActive 20;
BA_ "GenSigSendType" SG_ 370 ABsStatus 7;
BA_ "GenSigCycleTimeActive" SG_ 370 ABsStatus 20;
BA_ "GenSigCycleTime" SG_ 370 ABsStatus 20;
BA_ "GenSigTimeoutTime_HU_B" SG_ 370 CardanTrqLim 0;
BA_ "GenSigTimeoutTime_HU_A" SG_ 370 CardanTrqLim 0;
BA_ "GenSigTimeoutMsg_HU_B" SG_ 370 CardanTrqLim 0;
BA_ "GenSigTimeoutMsg_HU_A" SG_ 370 CardanTrqLim 0;
BA_ "GenSigStartValue" SG_ 370 CardanTrqLim 16383;
BA_ "GenSigSendType" SG_ 370 CardanTrqLim 7;
BA_ "GenSigInactiveValue" SG_ 370 CardanTrqLim 8192;
BA_ "GenSigCycleTimeActive" SG_ 370 CardanTrqLim 20;
BA_ "GenSigCycleTime" SG_ 370 CardanTrqLim 20;
BA_ "GenSigTimeoutTime_HU_B" SG_ 370 CardanTrqLimStatus 0;
BA_ "GenSigTimeoutTime_HU_A" SG_ 370 CardanTrqLimStatus 0;
BA_ "GenSigTimeoutMsg_HU_B" SG_ 370 CardanTrqLimStatus 0;
BA_ "GenSigTimeoutMsg_HU_A" SG_ 370 CardanTrqLimStatus 0;
BA_ "GenSigSendType" SG_ 370 CardanTrqLimStatus 7;
BA_ "GenSigCycleTimeActive" SG_ 370 CardanTrqLimStatus 20;
BA_ "GenSigCycleTime" SG_ 370 CardanTrqLimStatus 20;
BA_ "GenSigSendType" SG_ 370 VehSpdSetHDC 7;
BA_ "GenSigCycleTimeActive" SG_ 370 VehSpdSetHDC 20;
BA_ "GenSigCycleTime" SG_ 370 VehSpdSetHDC 20;
BA_ "GenSigSendType" SG_ 370 HHcStatus 7;
BA_ "GenSigCycleTimeActive" SG_ 370 HHcStatus 20;
BA_ "GenSigCycleTime" SG_ 370 HHcStatus 20;
BA_ "GenSigTimeoutTime_HU_B" SG_ 370 BrkLightSigStatus 0;
BA_ "GenSigTimeoutTime_HU_A" SG_ 370 BrkLightSigStatus 0;
BA_ "GenSigTimeoutMsg_HU_B" SG_ 370 BrkLightSigStatus 0;
BA_ "GenSigTimeoutMsg_HU_A" SG_ 370 BrkLightSigStatus 0;
BA_ "GenSigSendType" SG_ 370 BrkLightSigStatus 7;
BA_ "GenSigCycleTimeActive" SG_ 370 BrkLightSigStatus 20;
BA_ "GenSigCycleTime" SG_ 370 BrkLightSigStatus 20;
BA_ "GenSigTimeoutTime_HU_B" SG_ 370 BrkLightSig 0;
BA_ "GenSigTimeoutTime_HU_A" SG_ 370 BrkLightSig 0;
BA_ "GenSigTimeoutMsg_HU_B" SG_ 370 BrkLightSig 0;
BA_ "GenSigTimeoutMsg_HU_A" SG_ 370 BrkLightSig 0;
BA_ "GenSigSendType" SG_ 370 BrkLightSig 7;
BA_ "GenSigCycleTimeActive" SG_ 370 BrkLightSig 20;
BA_ "GenSigCycleTime" SG_ 370 BrkLightSig 20;
BA_ "GenSigTimeoutTime_HU_B" SG_ 370 CruiseCntShutESPStatus 0;
BA_ "GenSigTimeoutTime_HU_A" SG_ 370 CruiseCntShutESPStatus 0;
BA_ "GenSigTimeoutMsg_HU_B" SG_ 370 CruiseCntShutESPStatus 0;
BA_ "GenSigTimeoutMsg_HU_A" SG_ 370 CruiseCntShutESPStatus 0;
BA_ "GenSigSendType" SG_ 370 CruiseCntShutESPStatus 7;
BA_ "GenSigCycleTimeActive" SG_ 370 CruiseCntShutESPStatus 20;
BA_ "GenSigCycleTime" SG_ 370 CruiseCntShutESPStatus 20;
BA_ "GenSigTimeoutTime_HU_B" SG_ 370 CruiseCntShutESP 0;
BA_ "GenSigTimeoutTime_HU_A" SG_ 370 CruiseCntShutESP 0;
BA_ "GenSigTimeoutMsg_HU_B" SG_ 370 CruiseCntShutESP 0;
BA_ "GenSigTimeoutMsg_HU_A" SG_ 370 CruiseCntShutESP 0;
BA_ "GenSigSendType" SG_ 370 CruiseCntShutESP 7;
BA_ "GenSigCycleTimeActive" SG_ 370 CruiseCntShutESP 20;
BA_ "GenSigCycleTime" SG_ 370 CruiseCntShutESP 20;
BA_ "GenSigSendType" SG_ 370 HDcAvailability 7;
BA_ "GenSigCycleTimeActive" SG_ 370 HDcAvailability 20;
BA_ "GenSigCycleTime" SG_ 370 HDcAvailability 20;
BA_ "GenSigSendType" SG_ 370 VehSpdSetHDCStatus 7;
BA_ "GenSigCycleTimeActive" SG_ 370 VehSpdSetHDCStatus 20;
BA_ "GenSigCycleTime" SG_ 370 VehSpdSetHDCStatus 20;
BA_ "GenSigSendType" SG_ 370 HHcActive 7;
BA_ "GenSigCycleTimeActive" SG_ 370 HHcActive 20;
BA_ "GenSigCycleTime" SG_ 370 HHcActive 20;
BA_ "GenSigSendType" SG_ 370 HDcActive 7;
BA_ "GenSigCycleTimeActive" SG_ 370 HDcActive 20;
BA_ "GenSigCycleTime" SG_ 370 HDcActive 20;
BA_ "GenSigSendType" SG_ 370 HDcStatus 7;
BA_ "GenSigCycleTimeActive" SG_ 370 HDcStatus 20;
BA_ "GenSigCycleTime" SG_ 370 HDcStatus 20;
BA_ "GenSigTimeoutTime_HU_B" SG_ 371 SteerAngEPASGen2 0;
BA_ "GenSigTimeoutTime_HU_A" SG_ 371 SteerAngEPASGen2 0;
BA_ "GenSigTimeoutMsg_HU_B" SG_ 371 SteerAngEPASGen2 0;
BA_ "GenSigTimeoutMsg_HU_A" SG_ 371 SteerAngEPASGen2 0;
BA_ "GenSigSendType" SG_ 371 SteerAngEPASGen2 7;
BA_ "GenSigCycleTimeActive" SG_ 371 SteerAngEPASGen2 20;
BA_ "GenSigCycleTime" SG_ 371 SteerAngEPASGen2 20;
BA_ "GenSigTimeoutTime_HU_B" SG_ 371 SteerAngEPAsDirGen2 0;
BA_ "GenSigTimeoutTime_HU_A" SG_ 371 SteerAngEPAsDirGen2 0;
BA_ "GenSigTimeoutMsg_HU_B" SG_ 371 SteerAngEPAsDirGen2 0;
BA_ "GenSigTimeoutMsg_HU_A" SG_ 371 SteerAngEPAsDirGen2 0;
BA_ "GenSigSendType" SG_ 371 SteerAngEPAsDirGen2 7;
BA_ "GenSigCycleTimeActive" SG_ 371 SteerAngEPAsDirGen2 20;
BA_ "GenSigCycleTime" SG_ 371 SteerAngEPAsDirGen2 20;
BA_ "GenSigTimeoutTime_HU_B" SG_ 371 SteeringWheelAngleSpeed 0;
BA_ "GenSigTimeoutTime_HU_A" SG_ 371 SteeringWheelAngleSpeed 0;
BA_ "GenSigTimeoutMsg_HU_B" SG_ 371 SteeringWheelAngleSpeed 0;
BA_ "GenSigTimeoutMsg_HU_A" SG_ 371 SteeringWheelAngleSpeed 0;
BA_ "GenSigSendType" SG_ 371 SteeringWheelAngleSpeed 7;
BA_ "GenSigCycleTimeActive" SG_ 371 SteeringWheelAngleSpeed 20;
BA_ "GenSigCycleTime" SG_ 371 SteeringWheelAngleSpeed 20;
BA_ "GenSigTimeoutTime_HU_B" SG_ 371 SteerAngEPASStatusGen2 0;
BA_ "GenSigTimeoutTime_HU_A" SG_ 371 SteerAngEPASStatusGen2 0;
BA_ "GenSigTimeoutMsg_HU_B" SG_ 371 SteerAngEPASStatusGen2 0;
BA_ "GenSigTimeoutMsg_HU_A" SG_ 371 SteerAngEPASStatusGen2 0;
BA_ "GenSigStartValue" SG_ 371 SteerAngEPASStatusGen2 2;
BA_ "GenSigSendType" SG_ 371 SteerAngEPASStatusGen2 7;
BA_ "GenSigCycleTimeActive" SG_ 371 SteerAngEPASStatusGen2 20;
BA_ "GenSigCycleTime" SG_ 371 SteerAngEPASStatusGen2 20;
BA_ "GenSigTimeoutTime_HU_B" SG_ 371 MSG_CNT_6 0;
BA_ "GenSigTimeoutTime_HU_A" SG_ 371 MSG_CNT_6 0;
BA_ "GenSigTimeoutMsg_HU_B" SG_ 371 MSG_CNT_6 0;
BA_ "GenSigTimeoutMsg_HU_A" SG_ 371 MSG_CNT_6 0;
BA_ "GenSigSendType" SG_ 371 MSG_CNT_6 7;
BA_ "GenSigCycleTimeActive" SG_ 371 MSG_CNT_6 20;
BA_ "GenSigCycleTime" SG_ 371 MSG_CNT_6 20;
BA_ "GenSigTimeoutTime_HU_B" SG_ 371 CRC_6 0;
BA_ "GenSigTimeoutTime_HU_A" SG_ 371 CRC_6 0;
BA_ "GenSigTimeoutMsg_HU_B" SG_ 371 CRC_6 0;
BA_ "GenSigTimeoutMsg_HU_A" SG_ 371 CRC_6 0;
BA_ "GenSigSendType" SG_ 371 CRC_6 7;
BA_ "GenSigCycleTimeActive" SG_ 371 CRC_6 20;
BA_ "GenSigCycleTime" SG_ 371 CRC_6 20;
BA_ "GenSigTimeoutTime_HU_B" SG_ 372 WhlSpdFL 0;
BA_ "GenSigTimeoutTime_HU_A" SG_ 372 WhlSpdFL 0;
BA_ "GenSigTimeoutMsg_HU_B" SG_ 372 WhlSpdFL 0;
BA_ "GenSigTimeoutMsg_HU_A" SG_ 372 WhlSpdFL 0;
BA_ "GenSigSendType" SG_ 372 WhlSpdFL 7;
BA_ "GenSigCycleTimeActive" SG_ 372 WhlSpdFL 20;
BA_ "GenSigCycleTime" SG_ 372 WhlSpdFL 20;
BA_ "GenSigTimeoutTime_HU_B" SG_ 372 WhlSpdFR 0;
BA_ "GenSigTimeoutTime_HU_A" SG_ 372 WhlSpdFR 0;
BA_ "GenSigTimeoutMsg_HU_B" SG_ 372 WhlSpdFR 0;
BA_ "GenSigTimeoutMsg_HU_A" SG_ 372 WhlSpdFR 0;
BA_ "GenSigSendType" SG_ 372 WhlSpdFR 7;
BA_ "GenSigCycleTimeActive" SG_ 372 WhlSpdFR 20;
BA_ "GenSigCycleTime" SG_ 372 WhlSpdFR 20;
BA_ "GenSigTimeoutTime_HU_B" SG_ 372 WhlSpdRL 0;
BA_ "GenSigTimeoutTime_HU_A" SG_ 372 WhlSpdRL 0;
BA_ "GenSigTimeoutMsg_HU_B" SG_ 372 WhlSpdRL 0;
BA_ "GenSigTimeoutMsg_HU_A" SG_ 372 WhlSpdRL 0;
BA_ "GenSigSendType" SG_ 372 WhlSpdRL 7;
BA_ "GenSigCycleTimeActive" SG_ 372 WhlSpdRL 20;
BA_ "GenSigCycleTime" SG_ 372 WhlSpdRL 20;
BA_ "GenSigTimeoutTime_HU_B" SG_ 372 WhlSpdRR 0;
BA_ "GenSigTimeoutTime_HU_A" SG_ 372 WhlSpdRR 0;
BA_ "GenSigTimeoutMsg_HU_B" SG_ 372 WhlSpdRR 0;
BA_ "GenSigTimeoutMsg_HU_A" SG_ 372 WhlSpdRR 0;
BA_ "GenSigSendType" SG_ 372 WhlSpdRR 7;
BA_ "GenSigCycleTimeActive" SG_ 372 WhlSpdRR 20;
BA_ "GenSigCycleTime" SG_ 372 WhlSpdRR 20;
BA_ "GenSigTimeoutTime_HU_B" SG_ 372 WhlSpdRrStatus 0;
BA_ "GenSigTimeoutTime_HU_A" SG_ 372 WhlSpdRrStatus 0;
BA_ "GenSigTimeoutMsg_HU_B" SG_ 372 WhlSpdRrStatus 0;
BA_ "GenSigTimeoutMsg_HU_A" SG_ 372 WhlSpdRrStatus 0;
BA_ "GenSigSendType" SG_ 372 WhlSpdRrStatus 7;
BA_ "GenSigCycleTimeActive" SG_ 372 WhlSpdRrStatus 20;
BA_ "GenSigCycleTime" SG_ 372 WhlSpdRrStatus 20;
BA_ "GenSigTimeoutTime_HU_B" SG_ 372 WhlSpdRlStatus 0;
BA_ "GenSigTimeoutTime_HU_A" SG_ 372 WhlSpdRlStatus 0;
BA_ "GenSigTimeoutMsg_HU_B" SG_ 372 WhlSpdRlStatus 0;
BA_ "GenSigTimeoutMsg_HU_A" SG_ 372 WhlSpdRlStatus 0;
BA_ "GenSigSendType" SG_ 372 WhlSpdRlStatus 7;
BA_ "GenSigCycleTimeActive" SG_ 372 WhlSpdRlStatus 20;
BA_ "GenSigCycleTime" SG_ 372 WhlSpdRlStatus 20;
BA_ "GenSigTimeoutTime_HU_B" SG_ 372 WhlSpdFrStatus 0;
BA_ "GenSigTimeoutTime_HU_A" SG_ 372 WhlSpdFrStatus 0;
BA_ "GenSigTimeoutMsg_HU_B" SG_ 372 WhlSpdFrStatus 0;
BA_ "GenSigTimeoutMsg_HU_A" SG_ 372 WhlSpdFrStatus 0;
BA_ "GenSigSendType" SG_ 372 WhlSpdFrStatus 7;
BA_ "GenSigCycleTimeActive" SG_ 372 WhlSpdFrStatus 20;
BA_ "GenSigCycleTime" SG_ 372 WhlSpdFrStatus 20;
BA_ "GenSigTimeoutTime_HU_B" SG_ 372 WhlSpdFlStatus 0;
BA_ "GenSigTimeoutTime_HU_A" SG_ 372 WhlSpdFlStatus 0;
BA_ "GenSigTimeoutMsg_HU_B" SG_ 372 WhlSpdFlStatus 0;
BA_ "GenSigTimeoutMsg_HU_A" SG_ 372 WhlSpdFlStatus 0;
BA_ "GenSigSendType" SG_ 372 WhlSpdFlStatus 7;
BA_ "GenSigCycleTimeActive" SG_ 372 WhlSpdFlStatus 20;
BA_ "GenSigCycleTime" SG_ 372 WhlSpdFlStatus 20;
BA_ "GenSigSendType" SG_ 374 DrvModeIndctnESP2Status 7;
BA_ "GenSigCycleTimeActive" SG_ 374 DrvModeIndctnESP2Status 100;
BA_ "GenSigCycleTime" SG_ 374 DrvModeIndctnESP2Status 100;
BA_ "GenSigSendType" SG_ 374 DrvModeIndctnESP2 7;
BA_ "GenSigCycleTimeActive" SG_ 374 DrvModeIndctnESP2 100;
BA_ "GenSigCycleTime" SG_ 374 DrvModeIndctnESP2 100;
BA_ "GenSigSendType" SG_ 374 ODoABS 7;
BA_ "GenSigCycleTimeActive" SG_ 374 ODoABS 20;
BA_ "GenSigCycleTime" SG_ 374 ODoABS 20;
BA_ "GenSigSendType" SG_ 374 ODoABsStatus 7;
BA_ "GenSigCycleTimeActive" SG_ 374 ODoABsStatus 20;
BA_ "GenSigCycleTime" SG_ 374 ODoABsStatus 20;
BA_ "GenSigSendType" SG_ 374 VehSpdABS 7;
BA_ "GenSigCycleTimeActive" SG_ 374 VehSpdABS 20;
BA_ "GenSigCycleTime" SG_ 374 VehSpdABS 20;
BA_ "GenSigSendType" SG_ 374 VehSpdABsStatus 7;
BA_ "GenSigCycleTimeActive" SG_ 374 VehSpdABsStatus 20;
BA_ "GenSigCycleTime" SG_ 374 VehSpdABsStatus 20;
BA_ "GenSigStartValue" SG_ 376 AX1 32768;
BA_ "GenSigSendType" SG_ 376 AX1 7;
BA_ "GenSigCycleTimeActive" SG_ 376 AX1 20;
BA_ "GenSigCycleTime" SG_ 376 AX1 20;
BA_ "GenSigStartValue" SG_ 376 AY1 32768;
BA_ "GenSigSendType" SG_ 376 AY1 7;
BA_ "GenSigCycleTimeActive" SG_ 376 AY1 20;
BA_ "GenSigCycleTime" SG_ 376 AY1 20;
BA_ "GenSigTimeoutTime_HU_Mid_X451" SG_ 376 MasterCylinderPres 0;
BA_ "GenSigTimeoutTime_HU_High_X451" SG_ 376 MasterCylinderPres 0;
BA_ "GenSigTimeoutTime_HU_B" SG_ 376 MasterCylinderPres 0;
BA_ "GenSigTimeoutTime_HU_A" SG_ 376 MasterCylinderPres 0;
BA_ "GenSigTimeoutMsg_HU_Mid_X451" SG_ 376 MasterCylinderPres 0;
BA_ "GenSigTimeoutMsg_HU_High_X451" SG_ 376 MasterCylinderPres 0;
BA_ "GenSigTimeoutMsg_HU_B" SG_ 376 MasterCylinderPres 0;
BA_ "GenSigTimeoutMsg_HU_A" SG_ 376 MasterCylinderPres 0;
BA_ "GenSigStartValue" SG_ 376 MasterCylinderPres 800;
BA_ "GenSigSendType" SG_ 376 MasterCylinderPres 7;
BA_ "GenSigCycleTimeActive" SG_ 376 MasterCylinderPres 20;
BA_ "GenSigCycleTime" SG_ 376 MasterCylinderPres 20;
BA_ "GenSigTimeoutTime_HU_Mid_X451" SG_ 376 MasterCylinderPresStatus 0;
BA_ "GenSigTimeoutTime_HU_High_X451" SG_ 376 MasterCylinderPresStatus 0;
BA_ "GenSigTimeoutTime_HU_B" SG_ 376 MasterCylinderPresStatus 0;
BA_ "GenSigTimeoutTime_HU_A" SG_ 376 MasterCylinderPresStatus 0;
BA_ "GenSigTimeoutMsg_HU_Mid_X451" SG_ 376 MasterCylinderPresStatus 0;
BA_ "GenSigTimeoutMsg_HU_High_X451" SG_ 376 MasterCylinderPresStatus 0;
BA_ "GenSigTimeoutMsg_HU_B" SG_ 376 MasterCylinderPresStatus 0;
BA_ "GenSigTimeoutMsg_HU_A" SG_ 376 MasterCylinderPresStatus 0;
BA_ "GenSigSendType" SG_ 376 MasterCylinderPresStatus 7;
BA_ "GenSigCycleTimeActive" SG_ 376 MasterCylinderPresStatus 20;
BA_ "GenSigCycleTime" SG_ 376 MasterCylinderPresStatus 20;
BA_ "GenSigSendType" SG_ 407 VehSpdIC 7;
BA_ "GenSigCycleTimeActive" SG_ 407 VehSpdIC 20;
BA_ "GenSigCycleTime" SG_ 407 VehSpdIC 20;
BA_ "GenSigSendType" SG_ 407 VehSpdICStatus 7;
BA_ "GenSigCycleTimeActive" SG_ 407 VehSpdICStatus 20;
BA_ "GenSigCycleTime" SG_ 407 VehSpdICStatus 20;
BA_ "GenSigSendType" SG_ 407 SpdCRCSig 7;
BA_ "GenSigCycleTimeActive" SG_ 407 SpdCRCSig 20;
BA_ "GenSigCycleTime" SG_ 407 SpdCRCSig 20;
BA_ "GenSigSendType" SG_ 407 VehAnglSpdIc 7;
BA_ "GenSigCycleTimeActive" SG_ 407 VehAnglSpdIc 20;
BA_ "GenSigCycleTime" SG_ 407 VehAnglSpdIc 20;
BA_ "GenSigSendType" SG_ 407 SpdCountSig 7;
BA_ "GenSigCycleTimeActive" SG_ 407 SpdCountSig 20;
BA_ "GenSigCycleTime" SG_ 407 SpdCountSig 20;
BA_ "GenSigSendType" SG_ 407 VehAnglSpdIcStatus 7;
BA_ "GenSigCycleTimeActive" SG_ 407 VehAnglSpdIcStatus 20;
BA_ "GenSigCycleTime" SG_ 407 VehAnglSpdIcStatus 20;
BA_ "GenSigTimeoutTime_HU_B" SG_ 432 HuFeature12SignalVal1 0;
BA_ "GenSigTimeoutTime_HU_A" SG_ 432 HuFeature12SignalVal1 0;
BA_ "GenSigTimeoutMsg_HU_B" SG_ 432 HuFeature12SignalVal1 0;
BA_ "GenSigTimeoutMsg_HU_A" SG_ 432 HuFeature12SignalVal1 0;
BA_ "GenSigSendType" SG_ 432 HuFeature12SignalVal1 1;
BA_ "GenSigTimeoutTime_HU_B" SG_ 432 HuFeature12ActiveSignalVal 0;
BA_ "GenSigTimeoutTime_HU_A" SG_ 432 HuFeature12ActiveSignalVal 0;
BA_ "GenSigTimeoutMsg_HU_B" SG_ 432 HuFeature12ActiveSignalVal 0;
BA_ "GenSigTimeoutMsg_HU_A" SG_ 432 HuFeature12ActiveSignalVal 0;
BA_ "GenSigSendType" SG_ 432 HuFeature12ActiveSignalVal 1;
BA_ "GenSigTimeoutTime_HU_B" SG_ 432 HuFeature11ActiveSignalVal 0;
BA_ "GenSigTimeoutTime_HU_A" SG_ 432 HuFeature11ActiveSignalVal 0;
BA_ "GenSigTimeoutMsg_HU_B" SG_ 432 HuFeature11ActiveSignalVal 0;
BA_ "GenSigTimeoutMsg_HU_A" SG_ 432 HuFeature11ActiveSignalVal 0;
BA_ "GenSigSendType" SG_ 432 HuFeature11ActiveSignalVal 1;
BA_ "GenSigTimeoutTime_HU_B" SG_ 432 HuFeature10ActiveSignalVal 0;
BA_ "GenSigTimeoutTime_HU_A" SG_ 432 HuFeature10ActiveSignalVal 0;
BA_ "GenSigTimeoutMsg_HU_B" SG_ 432 HuFeature10ActiveSignalVal 0;
BA_ "GenSigTimeoutMsg_HU_A" SG_ 432 HuFeature10ActiveSignalVal 0;
BA_ "GenSigSendType" SG_ 432 HuFeature10ActiveSignalVal 1;
BA_ "GenSigTimeoutTime_HU_B" SG_ 432 HuFeature9ActiveSignalVal 0;
BA_ "GenSigTimeoutTime_HU_A" SG_ 432 HuFeature9ActiveSignalVal 0;
BA_ "GenSigTimeoutMsg_HU_B" SG_ 432 HuFeature9ActiveSignalVal 0;
BA_ "GenSigTimeoutMsg_HU_A" SG_ 432 HuFeature9ActiveSignalVal 0;
BA_ "GenSigSendType" SG_ 432 HuFeature9ActiveSignalVal 1;
BA_ "GenSigTimeoutTime_HU_B" SG_ 432 HuFeature8ActiveSignalVal 0;
BA_ "GenSigTimeoutTime_HU_A" SG_ 432 HuFeature8ActiveSignalVal 0;
BA_ "GenSigTimeoutMsg_HU_B" SG_ 432 HuFeature8ActiveSignalVal 0;
BA_ "GenSigTimeoutMsg_HU_A" SG_ 432 HuFeature8ActiveSignalVal 0;
BA_ "GenSigSendType" SG_ 432 HuFeature8ActiveSignalVal 1;
BA_ "GenSigTimeoutTime_HU_B" SG_ 432 HuFeature12SignalVal2 0;
BA_ "GenSigTimeoutTime_HU_A" SG_ 432 HuFeature12SignalVal2 0;
BA_ "GenSigTimeoutMsg_HU_B" SG_ 432 HuFeature12SignalVal2 0;
BA_ "GenSigTimeoutMsg_HU_A" SG_ 432 HuFeature12SignalVal2 0;
BA_ "GenSigSendType" SG_ 432 HuFeature12SignalVal2 1;
BA_ "GenSigTimeoutTime_HU_B" SG_ 432 HuFeature13SignalVal1 0;
BA_ "GenSigTimeoutTime_HU_A" SG_ 432 HuFeature13SignalVal1 0;
BA_ "GenSigTimeoutMsg_HU_B" SG_ 432 HuFeature13SignalVal1 0;
BA_ "GenSigTimeoutMsg_HU_A" SG_ 432 HuFeature13SignalVal1 0;
BA_ "GenSigSendType" SG_ 432 HuFeature13SignalVal1 1;
BA_ "GenSigTimeoutTime_HU_B" SG_ 432 HuFeature13ActiveSignalVal 0;
BA_ "GenSigTimeoutTime_HU_A" SG_ 432 HuFeature13ActiveSignalVal 0;
BA_ "GenSigTimeoutMsg_HU_B" SG_ 432 HuFeature13ActiveSignalVal 0;
BA_ "GenSigTimeoutMsg_HU_A" SG_ 432 HuFeature13ActiveSignalVal 0;
BA_ "GenSigSendType" SG_ 432 HuFeature13ActiveSignalVal 1;
BA_ "GenSigTimeoutTime_HU_B" SG_ 432 HuFeature12SignalVal3 0;
BA_ "GenSigTimeoutTime_HU_A" SG_ 432 HuFeature12SignalVal3 0;
BA_ "GenSigTimeoutMsg_HU_B" SG_ 432 HuFeature12SignalVal3 0;
BA_ "GenSigTimeoutMsg_HU_A" SG_ 432 HuFeature12SignalVal3 0;
BA_ "GenSigSendType" SG_ 432 HuFeature12SignalVal3 1;
BA_ "GenSigTimeoutTime_HU_B" SG_ 432 HuFeature13SignalVal2 0;
BA_ "GenSigTimeoutTime_HU_A" SG_ 432 HuFeature13SignalVal2 0;
BA_ "GenSigTimeoutMsg_HU_B" SG_ 432 HuFeature13SignalVal2 0;
BA_ "GenSigTimeoutMsg_HU_A" SG_ 432 HuFeature13SignalVal2 0;
BA_ "GenSigSendType" SG_ 432 HuFeature13SignalVal2 1;
BA_ "GenSigTimeoutTime_HU_B" SG_ 432 HuFeature13SignalVal3 0;
BA_ "GenSigTimeoutTime_HU_A" SG_ 432 HuFeature13SignalVal3 0;
BA_ "GenSigTimeoutMsg_HU_B" SG_ 432 HuFeature13SignalVal3 0;
BA_ "GenSigTimeoutMsg_HU_A" SG_ 432 HuFeature13SignalVal3 0;
BA_ "GenSigSendType" SG_ 432 HuFeature13SignalVal3 1;
BA_ "GenSigTimeoutTime_HU_B" SG_ 433 HuFeature14SignalVal2 0;
BA_ "GenSigTimeoutTime_HU_A" SG_ 433 HuFeature14SignalVal2 0;
BA_ "GenSigTimeoutMsg_HU_B" SG_ 433 HuFeature14SignalVal2 0;
BA_ "GenSigTimeoutMsg_HU_A" SG_ 433 HuFeature14SignalVal2 0;
BA_ "GenSigSendType" SG_ 433 HuFeature14SignalVal2 1;
BA_ "GenSigTimeoutTime_HU_B" SG_ 433 HuFeature14SignalVal1 0;
BA_ "GenSigTimeoutTime_HU_A" SG_ 433 HuFeature14SignalVal1 0;
BA_ "GenSigTimeoutMsg_HU_B" SG_ 433 HuFeature14SignalVal1 0;
BA_ "GenSigTimeoutMsg_HU_A" SG_ 433 HuFeature14SignalVal1 0;
BA_ "GenSigSendType" SG_ 433 HuFeature14SignalVal1 1;
BA_ "GenSigTimeoutTime_HU_B" SG_ 433 HuFeature15SignalVal1 0;
BA_ "GenSigTimeoutTime_HU_A" SG_ 433 HuFeature15SignalVal1 0;
BA_ "GenSigTimeoutMsg_HU_B" SG_ 433 HuFeature15SignalVal1 0;
BA_ "GenSigTimeoutMsg_HU_A" SG_ 433 HuFeature15SignalVal1 0;
BA_ "GenSigSendType" SG_ 433 HuFeature15SignalVal1 1;
BA_ "GenSigTimeoutTime_HU_B" SG_ 433 HuFeature14SignalVal3 0;
BA_ "GenSigTimeoutTime_HU_A" SG_ 433 HuFeature14SignalVal3 0;
BA_ "GenSigTimeoutMsg_HU_B" SG_ 433 HuFeature14SignalVal3 0;
BA_ "GenSigTimeoutMsg_HU_A" SG_ 433 HuFeature14SignalVal3 0;
BA_ "GenSigSendType" SG_ 433 HuFeature14SignalVal3 1;
BA_ "GenSigTimeoutTime_HU_B" SG_ 433 HuFeature15SignalVal2 0;
BA_ "GenSigTimeoutTime_HU_A" SG_ 433 HuFeature15SignalVal2 0;
BA_ "GenSigTimeoutMsg_HU_B" SG_ 433 HuFeature15SignalVal2 0;
BA_ "GenSigTimeoutMsg_HU_A" SG_ 433 HuFeature15SignalVal2 0;
BA_ "GenSigSendType" SG_ 433 HuFeature15SignalVal2 1;
BA_ "GenSigTimeoutTime_HU_B" SG_ 433 HuFeature14ActiveSignalVal 0;
BA_ "GenSigTimeoutTime_HU_A" SG_ 433 HuFeature14ActiveSignalVal 0;
BA_ "GenSigTimeoutMsg_HU_B" SG_ 433 HuFeature14ActiveSignalVal 0;
BA_ "GenSigTimeoutMsg_HU_A" SG_ 433 HuFeature14ActiveSignalVal 0;
BA_ "GenSigSendType" SG_ 433 HuFeature14ActiveSignalVal 1;
BA_ "GenSigTimeoutTime_HU_B" SG_ 433 HuFeature15SignalVal3 0;
BA_ "GenSigTimeoutTime_HU_A" SG_ 433 HuFeature15SignalVal3 0;
BA_ "GenSigTimeoutMsg_HU_B" SG_ 433 HuFeature15SignalVal3 0;
BA_ "GenSigTimeoutMsg_HU_A" SG_ 433 HuFeature15SignalVal3 0;
BA_ "GenSigSendType" SG_ 433 HuFeature15SignalVal3 1;
BA_ "GenSigTimeoutTime_HU_B" SG_ 433 HuFeature15ActiveSignalVal 0;
BA_ "GenSigTimeoutTime_HU_A" SG_ 433 HuFeature15ActiveSignalVal 0;
BA_ "GenSigTimeoutMsg_HU_B" SG_ 433 HuFeature15ActiveSignalVal 0;
BA_ "GenSigTimeoutMsg_HU_A" SG_ 433 HuFeature15ActiveSignalVal 0;
BA_ "GenSigSendType" SG_ 433 HuFeature15ActiveSignalVal 1;
BA_ "GenSigTimeoutTime_HU_B" SG_ 434 BCmFeature11ActiveSignalVal 0;
BA_ "GenSigTimeoutTime_HU_A" SG_ 434 BCmFeature11ActiveSignalVal 0;
BA_ "GenSigTimeoutMsg_HU_B" SG_ 434 BCmFeature11ActiveSignalVal 0;
BA_ "GenSigTimeoutMsg_HU_A" SG_ 434 BCmFeature11ActiveSignalVal 0;
BA_ "GenSigSendType" SG_ 434 BCmFeature11ActiveSignalVal 1;
BA_ "GenSigTimeoutTime_HU_B" SG_ 434 BCmFeature11State 0;
BA_ "GenSigTimeoutTime_HU_A" SG_ 434 BCmFeature11State 0;
BA_ "GenSigTimeoutMsg_HU_B" SG_ 434 BCmFeature11State 0;
BA_ "GenSigTimeoutMsg_HU_A" SG_ 434 BCmFeature11State 0;
BA_ "GenSigSendType" SG_ 434 BCmFeature11State 1;
BA_ "GenSigTimeoutTime_HU_B" SG_ 434 BCmFeature10ActiveSignalVal 0;
BA_ "GenSigTimeoutTime_HU_A" SG_ 434 BCmFeature10ActiveSignalVal 0;
BA_ "GenSigTimeoutMsg_HU_B" SG_ 434 BCmFeature10ActiveSignalVal 0;
BA_ "GenSigTimeoutMsg_HU_A" SG_ 434 BCmFeature10ActiveSignalVal 0;
BA_ "GenSigSendType" SG_ 434 BCmFeature10ActiveSignalVal 1;
BA_ "GenSigTimeoutTime_HU_B" SG_ 434 BCmFeature10State 0;
BA_ "GenSigTimeoutTime_HU_A" SG_ 434 BCmFeature10State 0;
BA_ "GenSigTimeoutMsg_HU_B" SG_ 434 BCmFeature10State 0;
BA_ "GenSigTimeoutMsg_HU_A" SG_ 434 BCmFeature10State 0;
BA_ "GenSigSendType" SG_ 434 BCmFeature10State 1;
BA_ "GenSigTimeoutTime_HU_B" SG_ 434 BCmFeature9ActiveSignalVal 0;
BA_ "GenSigTimeoutTime_HU_A" SG_ 434 BCmFeature9ActiveSignalVal 0;
BA_ "GenSigTimeoutMsg_HU_B" SG_ 434 BCmFeature9ActiveSignalVal 0;
BA_ "GenSigTimeoutMsg_HU_A" SG_ 434 BCmFeature9ActiveSignalVal 0;
BA_ "GenSigSendType" SG_ 434 BCmFeature9ActiveSignalVal 1;
BA_ "GenSigTimeoutTime_HU_B" SG_ 434 BCmFeature9State 0;
BA_ "GenSigTimeoutTime_HU_A" SG_ 434 BCmFeature9State 0;
BA_ "GenSigTimeoutMsg_HU_B" SG_ 434 BCmFeature9State 0;
BA_ "GenSigTimeoutMsg_HU_A" SG_ 434 BCmFeature9State 0;
BA_ "GenSigSendType" SG_ 434 BCmFeature9State 1;
BA_ "GenSigTimeoutTime_HU_B" SG_ 434 BCmFeature8ActiveSignalVal 0;
BA_ "GenSigTimeoutTime_HU_A" SG_ 434 BCmFeature8ActiveSignalVal 0;
BA_ "GenSigTimeoutMsg_HU_B" SG_ 434 BCmFeature8ActiveSignalVal 0;
BA_ "GenSigTimeoutMsg_HU_A" SG_ 434 BCmFeature8ActiveSignalVal 0;
BA_ "GenSigSendType" SG_ 434 BCmFeature8ActiveSignalVal 1;
BA_ "GenSigTimeoutTime_HU_B" SG_ 434 BCmFeature8State 0;
BA_ "GenSigTimeoutTime_HU_A" SG_ 434 BCmFeature8State 0;
BA_ "GenSigTimeoutMsg_HU_B" SG_ 434 BCmFeature8State 0;
BA_ "GenSigTimeoutMsg_HU_A" SG_ 434 BCmFeature8State 0;
BA_ "GenSigSendType" SG_ 434 BCmFeature8State 1;
BA_ "GenSigTimeoutTime_HU_B" SG_ 434 BCmFeature12SignalVal2 0;
BA_ "GenSigTimeoutTime_HU_A" SG_ 434 BCmFeature12SignalVal2 0;
BA_ "GenSigTimeoutMsg_HU_B" SG_ 434 BCmFeature12SignalVal2 0;
BA_ "GenSigTimeoutMsg_HU_A" SG_ 434 BCmFeature12SignalVal2 0;
BA_ "GenSigSendType" SG_ 434 BCmFeature12SignalVal2 1;
BA_ "GenSigTimeoutTime_HU_B" SG_ 434 BCmFeature12SignalVal1 0;
BA_ "GenSigTimeoutTime_HU_A" SG_ 434 BCmFeature12SignalVal1 0;
BA_ "GenSigTimeoutMsg_HU_B" SG_ 434 BCmFeature12SignalVal1 0;
BA_ "GenSigTimeoutMsg_HU_A" SG_ 434 BCmFeature12SignalVal1 0;
BA_ "GenSigSendType" SG_ 434 BCmFeature12SignalVal1 1;
BA_ "GenSigTimeoutTime_HU_B" SG_ 434 BCmFeature12State 0;
BA_ "GenSigTimeoutTime_HU_A" SG_ 434 BCmFeature12State 0;
BA_ "GenSigTimeoutMsg_HU_B" SG_ 434 BCmFeature12State 0;
BA_ "GenSigTimeoutMsg_HU_A" SG_ 434 BCmFeature12State 0;
BA_ "GenSigSendType" SG_ 434 BCmFeature12State 1;
BA_ "GenSigTimeoutTime_HU_B" SG_ 434 BCmFeature12SignalVal3 0;
BA_ "GenSigTimeoutTime_HU_A" SG_ 434 BCmFeature12SignalVal3 0;
BA_ "GenSigTimeoutMsg_HU_B" SG_ 434 BCmFeature12SignalVal3 0;
BA_ "GenSigTimeoutMsg_HU_A" SG_ 434 BCmFeature12SignalVal3 0;
BA_ "GenSigSendType" SG_ 434 BCmFeature12SignalVal3 1;
BA_ "GenSigTimeoutTime_HU_B" SG_ 434 BCmFeature13SignalVal1 0;
BA_ "GenSigTimeoutTime_HU_A" SG_ 434 BCmFeature13SignalVal1 0;
BA_ "GenSigTimeoutMsg_HU_B" SG_ 434 BCmFeature13SignalVal1 0;
BA_ "GenSigTimeoutMsg_HU_A" SG_ 434 BCmFeature13SignalVal1 0;
BA_ "GenSigSendType" SG_ 434 BCmFeature13SignalVal1 1;
BA_ "GenSigTimeoutTime_HU_B" SG_ 434 BCmFeature13State 0;
BA_ "GenSigTimeoutTime_HU_A" SG_ 434 BCmFeature13State 0;
BA_ "GenSigTimeoutMsg_HU_B" SG_ 434 BCmFeature13State 0;
BA_ "GenSigTimeoutMsg_HU_A" SG_ 434 BCmFeature13State 0;
BA_ "GenSigSendType" SG_ 434 BCmFeature13State 1;
BA_ "GenSigTimeoutTime_HU_B" SG_ 434 BCmFeature12ActiveSignalVal 0;
BA_ "GenSigTimeoutTime_HU_A" SG_ 434 BCmFeature12ActiveSignalVal 0;
BA_ "GenSigTimeoutMsg_HU_B" SG_ 434 BCmFeature12ActiveSignalVal 0;
BA_ "GenSigTimeoutMsg_HU_A" SG_ 434 BCmFeature12ActiveSignalVal 0;
BA_ "GenSigSendType" SG_ 434 BCmFeature12ActiveSignalVal 1;
BA_ "GenSigTimeoutTime_HU_B" SG_ 434 BCmFeature13SignalVal3 0;
BA_ "GenSigTimeoutTime_HU_A" SG_ 434 BCmFeature13SignalVal3 0;
BA_ "GenSigTimeoutMsg_HU_B" SG_ 434 BCmFeature13SignalVal3 0;
BA_ "GenSigTimeoutMsg_HU_A" SG_ 434 BCmFeature13SignalVal3 0;
BA_ "GenSigSendType" SG_ 434 BCmFeature13SignalVal3 1;
BA_ "GenSigTimeoutTime_HU_B" SG_ 434 BCmFeature13SignalVal2 0;
BA_ "GenSigTimeoutTime_HU_A" SG_ 434 BCmFeature13SignalVal2 0;
BA_ "GenSigTimeoutMsg_HU_B" SG_ 434 BCmFeature13SignalVal2 0;
BA_ "GenSigTimeoutMsg_HU_A" SG_ 434 BCmFeature13SignalVal2 0;
BA_ "GenSigSendType" SG_ 434 BCmFeature13SignalVal2 1;
BA_ "GenSigTimeoutTime_HU_B" SG_ 434 BCmFeature13ActiveSignalVal 0;
BA_ "GenSigTimeoutTime_HU_A" SG_ 434 BCmFeature13ActiveSignalVal 0;
BA_ "GenSigTimeoutMsg_HU_B" SG_ 434 BCmFeature13ActiveSignalVal 0;
BA_ "GenSigTimeoutMsg_HU_A" SG_ 434 BCmFeature13ActiveSignalVal 0;
BA_ "GenSigSendType" SG_ 434 BCmFeature13ActiveSignalVal 1;
BA_ "GenSigTimeoutTime_HU_B" SG_ 435 BCmFeature14SignalVal2 0;
BA_ "GenSigTimeoutTime_HU_A" SG_ 435 BCmFeature14SignalVal2 0;
BA_ "GenSigTimeoutMsg_HU_B" SG_ 435 BCmFeature14SignalVal2 0;
BA_ "GenSigTimeoutMsg_HU_A" SG_ 435 BCmFeature14SignalVal2 0;
BA_ "GenSigSendType" SG_ 435 BCmFeature14SignalVal2 1;
BA_ "GenSigTimeoutTime_HU_B" SG_ 435 BCmFeature14SignalVal1 0;
BA_ "GenSigTimeoutTime_HU_A" SG_ 435 BCmFeature14SignalVal1 0;
BA_ "GenSigTimeoutMsg_HU_B" SG_ 435 BCmFeature14SignalVal1 0;
BA_ "GenSigTimeoutMsg_HU_A" SG_ 435 BCmFeature14SignalVal1 0;
BA_ "GenSigSendType" SG_ 435 BCmFeature14SignalVal1 1;
BA_ "GenSigTimeoutTime_HU_B" SG_ 435 BCmFeature14State 0;
BA_ "GenSigTimeoutTime_HU_A" SG_ 435 BCmFeature14State 0;
BA_ "GenSigTimeoutMsg_HU_B" SG_ 435 BCmFeature14State 0;
BA_ "GenSigTimeoutMsg_HU_A" SG_ 435 BCmFeature14State 0;
BA_ "GenSigSendType" SG_ 435 BCmFeature14State 1;
BA_ "GenSigTimeoutTime_HU_B" SG_ 435 BCmFeature14SignalVal3 0;
BA_ "GenSigTimeoutTime_HU_A" SG_ 435 BCmFeature14SignalVal3 0;
BA_ "GenSigTimeoutMsg_HU_B" SG_ 435 BCmFeature14SignalVal3 0;
BA_ "GenSigTimeoutMsg_HU_A" SG_ 435 BCmFeature14SignalVal3 0;
BA_ "GenSigSendType" SG_ 435 BCmFeature14SignalVal3 1;
BA_ "GenSigTimeoutTime_HU_B" SG_ 435 BCmFeature15SignalVal1 0;
BA_ "GenSigTimeoutTime_HU_A" SG_ 435 BCmFeature15SignalVal1 0;
BA_ "GenSigTimeoutMsg_HU_B" SG_ 435 BCmFeature15SignalVal1 0;
BA_ "GenSigTimeoutMsg_HU_A" SG_ 435 BCmFeature15SignalVal1 0;
BA_ "GenSigSendType" SG_ 435 BCmFeature15SignalVal1 1;
BA_ "GenSigTimeoutTime_HU_B" SG_ 435 BCmFeature15State 0;
BA_ "GenSigTimeoutTime_HU_A" SG_ 435 BCmFeature15State 0;
BA_ "GenSigTimeoutMsg_HU_B" SG_ 435 BCmFeature15State 0;
BA_ "GenSigTimeoutMsg_HU_A" SG_ 435 BCmFeature15State 0;
BA_ "GenSigSendType" SG_ 435 BCmFeature15State 1;
BA_ "GenSigTimeoutTime_HU_B" SG_ 435 BCmFeature14ActiveSignalVal 0;
BA_ "GenSigTimeoutTime_HU_A" SG_ 435 BCmFeature14ActiveSignalVal 0;
BA_ "GenSigTimeoutMsg_HU_B" SG_ 435 BCmFeature14ActiveSignalVal 0;
BA_ "GenSigTimeoutMsg_HU_A" SG_ 435 BCmFeature14ActiveSignalVal 0;
BA_ "GenSigSendType" SG_ 435 BCmFeature14ActiveSignalVal 1;
BA_ "GenSigTimeoutTime_HU_B" SG_ 435 BCmFeature15SignalVal3 0;
BA_ "GenSigTimeoutTime_HU_A" SG_ 435 BCmFeature15SignalVal3 0;
BA_ "GenSigTimeoutMsg_HU_B" SG_ 435 BCmFeature15SignalVal3 0;
BA_ "GenSigTimeoutMsg_HU_A" SG_ 435 BCmFeature15SignalVal3 0;
BA_ "GenSigSendType" SG_ 435 BCmFeature15SignalVal3 1;
BA_ "GenSigTimeoutTime_HU_B" SG_ 435 BCmFeature15SignalVal2 0;
BA_ "GenSigTimeoutTime_HU_A" SG_ 435 BCmFeature15SignalVal2 0;
BA_ "GenSigTimeoutMsg_HU_B" SG_ 435 BCmFeature15SignalVal2 0;
BA_ "GenSigTimeoutMsg_HU_A" SG_ 435 BCmFeature15SignalVal2 0;
BA_ "GenSigSendType" SG_ 435 BCmFeature15SignalVal2 1;
BA_ "GenSigTimeoutTime_HU_B" SG_ 435 BCmFeature15ActiveSignalVal 0;
BA_ "GenSigTimeoutTime_HU_A" SG_ 435 BCmFeature15ActiveSignalVal 0;
BA_ "GenSigTimeoutMsg_HU_B" SG_ 435 BCmFeature15ActiveSignalVal 0;
BA_ "GenSigTimeoutMsg_HU_A" SG_ 435 BCmFeature15ActiveSignalVal 0;
BA_ "GenSigSendType" SG_ 435 BCmFeature15ActiveSignalVal 1;
BA_ "GenSigTimeoutTime_HU_Mid_X451" SG_ 448 PDcHuOnDelayTimer 0;
BA_ "GenSigTimeoutTime_HU_High_X451" SG_ 448 PDcHuOnDelayTimer 0;
BA_ "GenSigTimeoutTime_HU_B" SG_ 448 PDcHuOnDelayTimer 0;
BA_ "GenSigTimeoutTime_HU_A" SG_ 448 PDcHuOnDelayTimer 0;
BA_ "GenSigTimeoutMsg_HU_Mid_X451" SG_ 448 PDcHuOnDelayTimer 0;
BA_ "GenSigTimeoutMsg_HU_High_X451" SG_ 448 PDcHuOnDelayTimer 0;
BA_ "GenSigTimeoutMsg_HU_B" SG_ 448 PDcHuOnDelayTimer 0;
BA_ "GenSigTimeoutMsg_HU_A" SG_ 448 PDcHuOnDelayTimer 0;
BA_ "GenSigStartValue" SG_ 448 PDcHuOnDelayTimer 1;
BA_ "GenSigSendType" SG_ 448 PDcHuOnDelayTimer 1;
BA_ "GenSigTimeoutMsg_HU_High_X445" SG_ 448 PDcHuOnDelayTimer 0;
BA_ "GenSigTimeoutMsg_HU_Mid_X445" SG_ 448 PDcHuOnDelayTimer 0;
BA_ "GenSigTimeoutTime_HU_High_X445" SG_ 448 PDcHuOnDelayTimer 0;
BA_ "GenSigTimeoutTime_HU_Mid_X445" SG_ 448 PDcHuOnDelayTimer 0;
BA_ "GenSigTimeoutMsg_IVI" SG_ 448 PDcHuOnDelayTimer 0;
BA_ "GenSigTimeoutTime_IVI" SG_ 448 PDcHuOnDelayTimer 0;
BA_ "GenSigTimeoutTime_HU_Mid_X451" SG_ 448 PDcHuToneVolume 0;
BA_ "GenSigTimeoutTime_HU_High_X451" SG_ 448 PDcHuToneVolume 0;
BA_ "GenSigTimeoutTime_HU_B" SG_ 448 PDcHuToneVolume 0;
BA_ "GenSigTimeoutTime_HU_A" SG_ 448 PDcHuToneVolume 0;
BA_ "GenSigTimeoutMsg_HU_Mid_X451" SG_ 448 PDcHuToneVolume 0;
BA_ "GenSigTimeoutMsg_HU_High_X451" SG_ 448 PDcHuToneVolume 0;
BA_ "GenSigTimeoutMsg_HU_B" SG_ 448 PDcHuToneVolume 0;
BA_ "GenSigTimeoutMsg_HU_A" SG_ 448 PDcHuToneVolume 0;
BA_ "GenSigSendType" SG_ 448 PDcHuToneVolume 1;
BA_ "GenSigTimeoutMsg_HU_High_X445" SG_ 448 PDcHuToneVolume 0;
BA_ "GenSigTimeoutMsg_HU_Mid_X445" SG_ 448 PDcHuToneVolume 0;
BA_ "GenSigTimeoutTime_HU_High_X445" SG_ 448 PDcHuToneVolume 0;
BA_ "GenSigTimeoutTime_HU_Mid_X445" SG_ 448 PDcHuToneVolume 0;
BA_ "GenSigTimeoutMsg_IVI" SG_ 448 PDcHuToneVolume 0;
BA_ "GenSigTimeoutTime_IVI" SG_ 448 PDcHuToneVolume 0;
BA_ "GenSigTimeoutTime_HU_Mid_X451" SG_ 448 PDcHuRearTone 0;
BA_ "GenSigTimeoutTime_HU_High_X451" SG_ 448 PDcHuRearTone 0;
BA_ "GenSigTimeoutTime_HU_B" SG_ 448 PDcHuRearTone 0;
BA_ "GenSigTimeoutTime_HU_A" SG_ 448 PDcHuRearTone 0;
BA_ "GenSigTimeoutMsg_HU_Mid_X451" SG_ 448 PDcHuRearTone 0;
BA_ "GenSigTimeoutMsg_HU_High_X451" SG_ 448 PDcHuRearTone 0;
BA_ "GenSigTimeoutMsg_HU_B" SG_ 448 PDcHuRearTone 0;
BA_ "GenSigTimeoutMsg_HU_A" SG_ 448 PDcHuRearTone 0;
BA_ "GenSigSendType" SG_ 448 PDcHuRearTone 1;
BA_ "GenSigTimeoutMsg_HU_High_X445" SG_ 448 PDcHuRearTone 0;
BA_ "GenSigTimeoutMsg_HU_Mid_X445" SG_ 448 PDcHuRearTone 0;
BA_ "GenSigTimeoutTime_HU_High_X445" SG_ 448 PDcHuRearTone 0;
BA_ "GenSigTimeoutTime_HU_Mid_X445" SG_ 448 PDcHuRearTone 0;
BA_ "GenSigTimeoutMsg_IVI" SG_ 448 PDcHuRearTone 0;
BA_ "GenSigTimeoutTime_IVI" SG_ 448 PDcHuRearTone 0;
BA_ "GenSigTimeoutTime_HU_Mid_X451" SG_ 448 PDcHuRearNoOfSen 0;
BA_ "GenSigTimeoutTime_HU_High_X451" SG_ 448 PDcHuRearNoOfSen 0;
BA_ "GenSigTimeoutTime_HU_B" SG_ 448 PDcHuRearNoOfSen 0;
BA_ "GenSigTimeoutTime_HU_A" SG_ 448 PDcHuRearNoOfSen 0;
BA_ "GenSigTimeoutMsg_HU_Mid_X451" SG_ 448 PDcHuRearNoOfSen 0;
BA_ "GenSigTimeoutMsg_HU_High_X451" SG_ 448 PDcHuRearNoOfSen 0;
BA_ "GenSigTimeoutMsg_HU_B" SG_ 448 PDcHuRearNoOfSen 0;
BA_ "GenSigTimeoutMsg_HU_A" SG_ 448 PDcHuRearNoOfSen 0;
BA_ "GenSigSendType" SG_ 448 PDcHuRearNoOfSen 1;
BA_ "GenSigTimeoutMsg_HU_High_X445" SG_ 448 PDcHuRearNoOfSen 0;
BA_ "GenSigTimeoutMsg_HU_Mid_X445" SG_ 448 PDcHuRearNoOfSen 0;
BA_ "GenSigTimeoutTime_HU_High_X445" SG_ 448 PDcHuRearNoOfSen 0;
BA_ "GenSigTimeoutTime_HU_Mid_X445" SG_ 448 PDcHuRearNoOfSen 0;
BA_ "GenSigTimeoutMsg_IVI" SG_ 448 PDcHuRearNoOfSen 0;
BA_ "GenSigTimeoutTime_IVI" SG_ 448 PDcHuRearNoOfSen 0;
BA_ "GenSigTimeoutTime_HU_Mid_X451" SG_ 448 PDcHuVehicleImage 0;
BA_ "GenSigTimeoutTime_HU_High_X451" SG_ 448 PDcHuVehicleImage 0;
BA_ "GenSigTimeoutTime_HU_B" SG_ 448 PDcHuVehicleImage 0;
BA_ "GenSigTimeoutTime_HU_A" SG_ 448 PDcHuVehicleImage 0;
BA_ "GenSigTimeoutMsg_HU_Mid_X451" SG_ 448 PDcHuVehicleImage 0;
BA_ "GenSigTimeoutMsg_HU_High_X451" SG_ 448 PDcHuVehicleImage 0;
BA_ "GenSigTimeoutMsg_HU_B" SG_ 448 PDcHuVehicleImage 0;
BA_ "GenSigTimeoutMsg_HU_A" SG_ 448 PDcHuVehicleImage 0;
BA_ "GenSigSendType" SG_ 448 PDcHuVehicleImage 1;
BA_ "GenSigTimeoutMsg_HU_High_X445" SG_ 448 PDcHuVehicleImage 0;
BA_ "GenSigTimeoutMsg_HU_Mid_X445" SG_ 448 PDcHuVehicleImage 0;
BA_ "GenSigTimeoutTime_HU_High_X445" SG_ 448 PDcHuVehicleImage 0;
BA_ "GenSigTimeoutTime_HU_Mid_X445" SG_ 448 PDcHuVehicleImage 0;
BA_ "GenSigTimeoutMsg_IVI" SG_ 448 PDcHuVehicleImage 0;
BA_ "GenSigTimeoutTime_IVI" SG_ 448 PDcHuVehicleImage 0;
BA_ "GenSigTimeoutTime_HU_Mid_X451" SG_ 448 PDcHuFrontActivationState 0;
BA_ "GenSigTimeoutTime_HU_High_X451" SG_ 448 PDcHuFrontActivationState 0;
BA_ "GenSigTimeoutTime_HU_B" SG_ 448 PDcHuFrontActivationState 0;
BA_ "GenSigTimeoutTime_HU_A" SG_ 448 PDcHuFrontActivationState 0;
BA_ "GenSigTimeoutMsg_HU_Mid_X451" SG_ 448 PDcHuFrontActivationState 0;
BA_ "GenSigTimeoutMsg_HU_High_X451" SG_ 448 PDcHuFrontActivationState 0;
BA_ "GenSigTimeoutMsg_HU_B" SG_ 448 PDcHuFrontActivationState 0;
BA_ "GenSigTimeoutMsg_HU_A" SG_ 448 PDcHuFrontActivationState 0;
BA_ "GenSigSendType" SG_ 448 PDcHuFrontActivationState 1;
BA_ "GenSigTimeoutMsg_HU_High_X445" SG_ 448 PDcHuFrontActivationState 0;
BA_ "GenSigTimeoutMsg_HU_Mid_X445" SG_ 448 PDcHuFrontActivationState 0;
BA_ "GenSigTimeoutTime_HU_High_X445" SG_ 448 PDcHuFrontActivationState 0;
BA_ "GenSigTimeoutTime_HU_Mid_X445" SG_ 448 PDcHuFrontActivationState 0;
BA_ "GenSigTimeoutMsg_IVI" SG_ 448 PDcHuFrontActivationState 0;
BA_ "GenSigTimeoutTime_IVI" SG_ 448 PDcHuFrontActivationState 0;
BA_ "GenSigTimeoutTime_HU_Mid_X451" SG_ 448 PDcHuLowSpeedActivation 0;
BA_ "GenSigTimeoutTime_HU_High_X451" SG_ 448 PDcHuLowSpeedActivation 0;
BA_ "GenSigTimeoutTime_HU_B" SG_ 448 PDcHuLowSpeedActivation 0;
BA_ "GenSigTimeoutTime_HU_A" SG_ 448 PDcHuLowSpeedActivation 0;
BA_ "GenSigTimeoutMsg_HU_Mid_X451" SG_ 448 PDcHuLowSpeedActivation 0;
BA_ "GenSigTimeoutMsg_HU_High_X451" SG_ 448 PDcHuLowSpeedActivation 0;
BA_ "GenSigTimeoutMsg_HU_B" SG_ 448 PDcHuLowSpeedActivation 0;
BA_ "GenSigTimeoutMsg_HU_A" SG_ 448 PDcHuLowSpeedActivation 0;
BA_ "GenSigSendType" SG_ 448 PDcHuLowSpeedActivation 1;
BA_ "GenSigTimeoutMsg_HU_High_X445" SG_ 448 PDcHuLowSpeedActivation 0;
BA_ "GenSigTimeoutMsg_HU_Mid_X445" SG_ 448 PDcHuLowSpeedActivation 0;
BA_ "GenSigTimeoutTime_HU_High_X445" SG_ 448 PDcHuLowSpeedActivation 0;
BA_ "GenSigTimeoutTime_HU_Mid_X445" SG_ 448 PDcHuLowSpeedActivation 0;
BA_ "GenSigTimeoutMsg_IVI" SG_ 448 PDcHuLowSpeedActivation 0;
BA_ "GenSigTimeoutTime_IVI" SG_ 448 PDcHuLowSpeedActivation 0;
BA_ "GenSigTimeoutTime_HU_Mid_X451" SG_ 448 PDcHuFrontNoOfSen 0;
BA_ "GenSigTimeoutTime_HU_High_X451" SG_ 448 PDcHuFrontNoOfSen 0;
BA_ "GenSigTimeoutTime_HU_B" SG_ 448 PDcHuFrontNoOfSen 0;
BA_ "GenSigTimeoutTime_HU_A" SG_ 448 PDcHuFrontNoOfSen 0;
BA_ "GenSigTimeoutMsg_HU_Mid_X451" SG_ 448 PDcHuFrontNoOfSen 0;
BA_ "GenSigTimeoutMsg_HU_High_X451" SG_ 448 PDcHuFrontNoOfSen 0;
BA_ "GenSigTimeoutMsg_HU_B" SG_ 448 PDcHuFrontNoOfSen 0;
BA_ "GenSigTimeoutMsg_HU_A" SG_ 448 PDcHuFrontNoOfSen 0;
BA_ "GenSigSendType" SG_ 448 PDcHuFrontNoOfSen 1;
BA_ "GenSigTimeoutMsg_HU_High_X445" SG_ 448 PDcHuFrontNoOfSen 0;
BA_ "GenSigTimeoutMsg_HU_Mid_X445" SG_ 448 PDcHuFrontNoOfSen 0;
BA_ "GenSigTimeoutTime_HU_High_X445" SG_ 448 PDcHuFrontNoOfSen 0;
BA_ "GenSigTimeoutTime_HU_Mid_X445" SG_ 448 PDcHuFrontNoOfSen 0;
BA_ "GenSigTimeoutMsg_IVI" SG_ 448 PDcHuFrontNoOfSen 0;
BA_ "GenSigTimeoutTime_IVI" SG_ 448 PDcHuFrontNoOfSen 0;
BA_ "GenSigTimeoutTime_HU_Mid_X451" SG_ 448 PDcHuFrontTone 0;
BA_ "GenSigTimeoutTime_HU_High_X451" SG_ 448 PDcHuFrontTone 0;
BA_ "GenSigTimeoutTime_HU_B" SG_ 448 PDcHuFrontTone 0;
BA_ "GenSigTimeoutTime_HU_A" SG_ 448 PDcHuFrontTone 0;
BA_ "GenSigTimeoutMsg_HU_Mid_X451" SG_ 448 PDcHuFrontTone 0;
BA_ "GenSigTimeoutMsg_HU_High_X451" SG_ 448 PDcHuFrontTone 0;
BA_ "GenSigTimeoutMsg_HU_B" SG_ 448 PDcHuFrontTone 0;
BA_ "GenSigTimeoutMsg_HU_A" SG_ 448 PDcHuFrontTone 0;
BA_ "GenSigSendType" SG_ 448 PDcHuFrontTone 1;
BA_ "GenSigTimeoutMsg_HU_High_X445" SG_ 448 PDcHuFrontTone 0;
BA_ "GenSigTimeoutMsg_HU_Mid_X445" SG_ 448 PDcHuFrontTone 0;
BA_ "GenSigTimeoutTime_HU_High_X445" SG_ 448 PDcHuFrontTone 0;
BA_ "GenSigTimeoutTime_HU_Mid_X445" SG_ 448 PDcHuFrontTone 0;
BA_ "GenSigTimeoutMsg_IVI" SG_ 448 PDcHuFrontTone 0;
BA_ "GenSigTimeoutTime_IVI" SG_ 448 PDcHuFrontTone 0;
BA_ "GenSigTimeoutTime_HU_Mid_X451" SG_ 448 PDcHuFrontAudioMuteState 0;
BA_ "GenSigTimeoutTime_HU_High_X451" SG_ 448 PDcHuFrontAudioMuteState 0;
BA_ "GenSigTimeoutTime_HU_B" SG_ 448 PDcHuFrontAudioMuteState 0;
BA_ "GenSigTimeoutTime_HU_A" SG_ 448 PDcHuFrontAudioMuteState 0;
BA_ "GenSigTimeoutMsg_HU_Mid_X451" SG_ 448 PDcHuFrontAudioMuteState 0;
BA_ "GenSigTimeoutMsg_HU_High_X451" SG_ 448 PDcHuFrontAudioMuteState 0;
BA_ "GenSigTimeoutMsg_HU_B" SG_ 448 PDcHuFrontAudioMuteState 0;
BA_ "GenSigTimeoutMsg_HU_A" SG_ 448 PDcHuFrontAudioMuteState 0;
BA_ "GenSigSendType" SG_ 448 PDcHuFrontAudioMuteState 1;
BA_ "GenSigTimeoutMsg_HU_High_X445" SG_ 448 PDcHuFrontAudioMuteState 0;
BA_ "GenSigTimeoutMsg_HU_Mid_X445" SG_ 448 PDcHuFrontAudioMuteState 0;
BA_ "GenSigTimeoutTime_HU_High_X445" SG_ 448 PDcHuFrontAudioMuteState 0;
BA_ "GenSigTimeoutTime_HU_Mid_X445" SG_ 448 PDcHuFrontAudioMuteState 0;
BA_ "GenSigTimeoutMsg_IVI" SG_ 448 PDcHuFrontAudioMuteState 0;
BA_ "GenSigTimeoutTime_IVI" SG_ 448 PDcHuFrontAudioMuteState 0;
BA_ "GenSigTimeoutTime_HU_Mid_X451" SG_ 448 RVcImageRotationType 0;
BA_ "GenSigTimeoutTime_HU_High_X451" SG_ 448 RVcImageRotationType 0;
BA_ "GenSigTimeoutTime_HU_B" SG_ 448 RVcImageRotationType 0;
BA_ "GenSigTimeoutTime_HU_A" SG_ 448 RVcImageRotationType 0;
BA_ "GenSigTimeoutMsg_HU_Mid_X451" SG_ 448 RVcImageRotationType 0;
BA_ "GenSigTimeoutMsg_HU_High_X451" SG_ 448 RVcImageRotationType 0;
BA_ "GenSigTimeoutMsg_HU_B" SG_ 448 RVcImageRotationType 0;
BA_ "GenSigTimeoutMsg_HU_A" SG_ 448 RVcImageRotationType 0;
BA_ "GenSigSendType" SG_ 448 RVcImageRotationType 1;
BA_ "GenSigTimeoutMsg_HU_High_X445" SG_ 448 RVcImageRotationType 0;
BA_ "GenSigTimeoutMsg_HU_Mid_X445" SG_ 448 RVcImageRotationType 0;
BA_ "GenSigTimeoutTime_HU_High_X445" SG_ 448 RVcImageRotationType 0;
BA_ "GenSigTimeoutTime_HU_Mid_X445" SG_ 448 RVcImageRotationType 0;
BA_ "GenSigTimeoutMsg_IVI" SG_ 448 RVcImageRotationType 0;
BA_ "GenSigTimeoutTime_IVI" SG_ 448 RVcImageRotationType 0;
BA_ "GenSigTimeoutTime_HU_Mid_X451" SG_ 448 RVcOverlayType 0;
BA_ "GenSigTimeoutTime_HU_High_X451" SG_ 448 RVcOverlayType 0;
BA_ "GenSigTimeoutTime_HU_B" SG_ 448 RVcOverlayType 0;
BA_ "GenSigTimeoutTime_HU_A" SG_ 448 RVcOverlayType 0;
BA_ "GenSigTimeoutMsg_HU_Mid_X451" SG_ 448 RVcOverlayType 0;
BA_ "GenSigTimeoutMsg_HU_High_X451" SG_ 448 RVcOverlayType 0;
BA_ "GenSigTimeoutMsg_HU_B" SG_ 448 RVcOverlayType 0;
BA_ "GenSigTimeoutMsg_HU_A" SG_ 448 RVcOverlayType 0;
BA_ "GenSigSendType" SG_ 448 RVcOverlayType 1;
BA_ "GenSigTimeoutMsg_HU_High_X445" SG_ 448 RVcOverlayType 0;
BA_ "GenSigTimeoutMsg_HU_Mid_X445" SG_ 448 RVcOverlayType 0;
BA_ "GenSigTimeoutTime_HU_High_X445" SG_ 448 RVcOverlayType 0;
BA_ "GenSigTimeoutTime_HU_Mid_X445" SG_ 448 RVcOverlayType 0;
BA_ "GenSigTimeoutMsg_IVI" SG_ 448 RVcOverlayType 0;
BA_ "GenSigTimeoutTime_IVI" SG_ 448 RVcOverlayType 0;
BA_ "GenSigTimeoutTime_HU_Mid_X451" SG_ 451 OdoICFullSig 0;
BA_ "GenSigTimeoutTime_HU_High_X451" SG_ 451 OdoICFullSig 0;
BA_ "GenSigTimeoutTime_HU_B" SG_ 451 OdoICFullSig 0;
BA_ "GenSigTimeoutTime_HU_A" SG_ 451 OdoICFullSig 0;
BA_ "GenSigTimeoutMsg_HU_Mid_X451" SG_ 451 OdoICFullSig 0;
BA_ "GenSigTimeoutMsg_HU_High_X451" SG_ 451 OdoICFullSig 0;
BA_ "GenSigTimeoutMsg_HU_B" SG_ 451 OdoICFullSig 0;
BA_ "GenSigTimeoutMsg_HU_A" SG_ 451 OdoICFullSig 0;
BA_ "GenSigSendType" SG_ 451 OdoICFullSig 1;
BA_ "GenSigTimeoutMsg_HU_High_X445" SG_ 451 OdoICFullSig 0;
BA_ "GenSigTimeoutMsg_HU_Mid_X445" SG_ 451 OdoICFullSig 0;
BA_ "GenSigTimeoutTime_HU_High_X445" SG_ 451 OdoICFullSig 0;
BA_ "GenSigTimeoutTime_HU_Mid_X445" SG_ 451 OdoICFullSig 0;
BA_ "GenSigTimeoutMsg_IVI" SG_ 451 OdoICFullSig 0;
BA_ "GenSigTimeoutTime_IVI" SG_ 451 OdoICFullSig 0;
BA_ "GenSigTimeoutTime_HU_Mid_X451" SG_ 454 IcHuTempUnitSet 0;
BA_ "GenSigTimeoutTime_HU_High_X451" SG_ 454 IcHuTempUnitSet 0;
BA_ "GenSigTimeoutTime_HU_B" SG_ 454 IcHuTempUnitSet 0;
BA_ "GenSigTimeoutTime_HU_A" SG_ 454 IcHuTempUnitSet 0;
BA_ "GenSigTimeoutMsg_HU_Mid_X451" SG_ 454 IcHuTempUnitSet 0;
BA_ "GenSigTimeoutMsg_HU_High_X451" SG_ 454 IcHuTempUnitSet 0;
BA_ "GenSigTimeoutMsg_HU_B" SG_ 454 IcHuTempUnitSet 0;
BA_ "GenSigTimeoutMsg_HU_A" SG_ 454 IcHuTempUnitSet 0;
BA_ "GenSigSendType" SG_ 454 IcHuTempUnitSet 1;
BA_ "GenSigTimeoutMsg_HU_High_X445" SG_ 454 IcHuTempUnitSet 0;
BA_ "GenSigTimeoutMsg_HU_Mid_X445" SG_ 454 IcHuTempUnitSet 0;
BA_ "GenSigTimeoutTime_HU_High_X445" SG_ 454 IcHuTempUnitSet 0;
BA_ "GenSigTimeoutTime_HU_Mid_X445" SG_ 454 IcHuTempUnitSet 0;
BA_ "GenSigTimeoutMsg_IVI" SG_ 454 IcHuTempUnitSet 0;
BA_ "GenSigTimeoutTime_IVI" SG_ 454 IcHuTempUnitSet 0;
BA_ "GenSigTimeoutTime_HU_Mid_X451" SG_ 454 IcHuDistUnitSet 0;
BA_ "GenSigTimeoutTime_HU_High_X451" SG_ 454 IcHuDistUnitSet 0;
BA_ "GenSigTimeoutTime_HU_B" SG_ 454 IcHuDistUnitSet 0;
BA_ "GenSigTimeoutTime_HU_A" SG_ 454 IcHuDistUnitSet 0;
BA_ "GenSigTimeoutMsg_HU_Mid_X451" SG_ 454 IcHuDistUnitSet 0;
BA_ "GenSigTimeoutMsg_HU_High_X451" SG_ 454 IcHuDistUnitSet 0;
BA_ "GenSigTimeoutMsg_HU_B" SG_ 454 IcHuDistUnitSet 0;
BA_ "GenSigTimeoutMsg_HU_A" SG_ 454 IcHuDistUnitSet 0;
BA_ "GenSigSendType" SG_ 454 IcHuDistUnitSet 1;
BA_ "GenSigTimeoutMsg_HU_High_X445" SG_ 454 IcHuDistUnitSet 0;
BA_ "GenSigTimeoutMsg_HU_Mid_X445" SG_ 454 IcHuDistUnitSet 0;
BA_ "GenSigTimeoutTime_HU_High_X445" SG_ 454 IcHuDistUnitSet 0;
BA_ "GenSigTimeoutTime_HU_Mid_X445" SG_ 454 IcHuDistUnitSet 0;
BA_ "GenSigTimeoutMsg_IVI" SG_ 454 IcHuDistUnitSet 0;
BA_ "GenSigTimeoutTime_IVI" SG_ 454 IcHuDistUnitSet 0;
BA_ "GenSigTimeoutTime_HU_Mid_X451" SG_ 454 IcHuSecondsInfo 0;
BA_ "GenSigTimeoutTime_HU_High_X451" SG_ 454 IcHuSecondsInfo 0;
BA_ "GenSigTimeoutTime_HU_B" SG_ 454 IcHuSecondsInfo 0;
BA_ "GenSigTimeoutTime_HU_A" SG_ 454 IcHuSecondsInfo 0;
BA_ "GenSigTimeoutMsg_HU_Mid_X451" SG_ 454 IcHuSecondsInfo 0;
BA_ "GenSigTimeoutMsg_HU_High_X451" SG_ 454 IcHuSecondsInfo 0;
BA_ "GenSigTimeoutMsg_HU_B" SG_ 454 IcHuSecondsInfo 0;
BA_ "GenSigTimeoutMsg_HU_A" SG_ 454 IcHuSecondsInfo 0;
BA_ "GenSigSendType" SG_ 454 IcHuSecondsInfo 1;
BA_ "GenSigTimeoutMsg_HU_High_X445" SG_ 454 IcHuSecondsInfo 0;
BA_ "GenSigTimeoutMsg_HU_Mid_X445" SG_ 454 IcHuSecondsInfo 0;
BA_ "GenSigTimeoutTime_HU_High_X445" SG_ 454 IcHuSecondsInfo 0;
BA_ "GenSigTimeoutTime_HU_Mid_X445" SG_ 454 IcHuSecondsInfo 0;
BA_ "GenSigTimeoutMsg_IVI" SG_ 454 IcHuSecondsInfo 0;
BA_ "GenSigTimeoutTime_IVI" SG_ 454 IcHuSecondsInfo 0;
BA_ "GenSigTimeoutTime_HU_Mid_X451" SG_ 454 IcHuFuelUnitSet 0;
BA_ "GenSigTimeoutTime_HU_High_X451" SG_ 454 IcHuFuelUnitSet 0;
BA_ "GenSigTimeoutTime_HU_B" SG_ 454 IcHuFuelUnitSet 0;
BA_ "GenSigTimeoutTime_HU_A" SG_ 454 IcHuFuelUnitSet 0;
BA_ "GenSigTimeoutMsg_HU_Mid_X451" SG_ 454 IcHuFuelUnitSet 0;
BA_ "GenSigTimeoutMsg_HU_High_X451" SG_ 454 IcHuFuelUnitSet 0;
BA_ "GenSigTimeoutMsg_HU_B" SG_ 454 IcHuFuelUnitSet 0;
BA_ "GenSigTimeoutMsg_HU_A" SG_ 454 IcHuFuelUnitSet 0;
BA_ "GenSigSendType" SG_ 454 IcHuFuelUnitSet 1;
BA_ "GenSigTimeoutMsg_HU_High_X445" SG_ 454 IcHuFuelUnitSet 0;
BA_ "GenSigTimeoutMsg_HU_Mid_X445" SG_ 454 IcHuFuelUnitSet 0;
BA_ "GenSigTimeoutTime_HU_High_X445" SG_ 454 IcHuFuelUnitSet 0;
BA_ "GenSigTimeoutTime_HU_Mid_X445" SG_ 454 IcHuFuelUnitSet 0;
BA_ "GenSigTimeoutMsg_IVI" SG_ 454 IcHuFuelUnitSet 0;
BA_ "GenSigTimeoutTime_IVI" SG_ 454 IcHuFuelUnitSet 0;
BA_ "GenSigTimeoutTime_HU_Mid_X451" SG_ 454 IcHuMinuteInfo 0;
BA_ "GenSigTimeoutTime_HU_High_X451" SG_ 454 IcHuMinuteInfo 0;
BA_ "GenSigTimeoutTime_HU_B" SG_ 454 IcHuMinuteInfo 0;
BA_ "GenSigTimeoutTime_HU_A" SG_ 454 IcHuMinuteInfo 0;
BA_ "GenSigTimeoutMsg_HU_Mid_X451" SG_ 454 IcHuMinuteInfo 0;
BA_ "GenSigTimeoutMsg_HU_High_X451" SG_ 454 IcHuMinuteInfo 0;
BA_ "GenSigTimeoutMsg_HU_B" SG_ 454 IcHuMinuteInfo 0;
BA_ "GenSigTimeoutMsg_HU_A" SG_ 454 IcHuMinuteInfo 0;
BA_ "GenSigSendType" SG_ 454 IcHuMinuteInfo 1;
BA_ "GenSigTimeoutMsg_HU_High_X445" SG_ 454 IcHuMinuteInfo 0;
BA_ "GenSigTimeoutMsg_HU_Mid_X445" SG_ 454 IcHuMinuteInfo 0;
BA_ "GenSigTimeoutTime_HU_High_X445" SG_ 454 IcHuMinuteInfo 0;
BA_ "GenSigTimeoutTime_HU_Mid_X445" SG_ 454 IcHuMinuteInfo 0;
BA_ "GenSigTimeoutMsg_IVI" SG_ 454 IcHuMinuteInfo 0;
BA_ "GenSigTimeoutTime_IVI" SG_ 454 IcHuMinuteInfo 0;
BA_ "GenSigTimeoutTime_HU_Mid_X451" SG_ 454 IcHuClockMode 0;
BA_ "GenSigTimeoutTime_HU_High_X451" SG_ 454 IcHuClockMode 0;
BA_ "GenSigTimeoutTime_HU_B" SG_ 454 IcHuClockMode 0;
BA_ "GenSigTimeoutTime_HU_A" SG_ 454 IcHuClockMode 0;
BA_ "GenSigTimeoutMsg_HU_Mid_X451" SG_ 454 IcHuClockMode 0;
BA_ "GenSigTimeoutMsg_HU_High_X451" SG_ 454 IcHuClockMode 0;
BA_ "GenSigTimeoutMsg_HU_B" SG_ 454 IcHuClockMode 0;
BA_ "GenSigTimeoutMsg_HU_A" SG_ 454 IcHuClockMode 0;
BA_ "GenSigSendType" SG_ 454 IcHuClockMode 1;
BA_ "GenSigTimeoutMsg_HU_High_X445" SG_ 454 IcHuClockMode 0;
BA_ "GenSigTimeoutMsg_HU_Mid_X445" SG_ 454 IcHuClockMode 0;
BA_ "GenSigTimeoutTime_HU_High_X445" SG_ 454 IcHuClockMode 0;
BA_ "GenSigTimeoutTime_HU_Mid_X445" SG_ 454 IcHuClockMode 0;
BA_ "GenSigTimeoutMsg_IVI" SG_ 454 IcHuClockMode 0;
BA_ "GenSigTimeoutTime_IVI" SG_ 454 IcHuClockMode 0;
BA_ "GenSigTimeoutTime_HU_Mid_X451" SG_ 454 IcHuHourInfo 0;
BA_ "GenSigTimeoutTime_HU_High_X451" SG_ 454 IcHuHourInfo 0;
BA_ "GenSigTimeoutTime_HU_B" SG_ 454 IcHuHourInfo 0;
BA_ "GenSigTimeoutTime_HU_A" SG_ 454 IcHuHourInfo 0;
BA_ "GenSigTimeoutMsg_HU_Mid_X451" SG_ 454 IcHuHourInfo 0;
BA_ "GenSigTimeoutMsg_HU_High_X451" SG_ 454 IcHuHourInfo 0;
BA_ "GenSigTimeoutMsg_HU_B" SG_ 454 IcHuHourInfo 0;
BA_ "GenSigTimeoutMsg_HU_A" SG_ 454 IcHuHourInfo 0;
BA_ "GenSigSendType" SG_ 454 IcHuHourInfo 1;
BA_ "GenSigTimeoutMsg_HU_High_X445" SG_ 454 IcHuHourInfo 0;
BA_ "GenSigTimeoutMsg_HU_Mid_X445" SG_ 454 IcHuHourInfo 0;
BA_ "GenSigTimeoutTime_HU_High_X445" SG_ 454 IcHuHourInfo 0;
BA_ "GenSigTimeoutTime_HU_Mid_X445" SG_ 454 IcHuHourInfo 0;
BA_ "GenSigTimeoutMsg_IVI" SG_ 454 IcHuHourInfo 0;
BA_ "GenSigTimeoutTime_IVI" SG_ 454 IcHuHourInfo 0;
BA_ "GenSigTimeoutTime_HU_Mid_X451" SG_ 454 IcHuDateInfo 0;
BA_ "GenSigTimeoutTime_HU_High_X451" SG_ 454 IcHuDateInfo 0;
BA_ "GenSigTimeoutTime_HU_B" SG_ 454 IcHuDateInfo 0;
BA_ "GenSigTimeoutTime_HU_A" SG_ 454 IcHuDateInfo 0;
BA_ "GenSigTimeoutMsg_HU_Mid_X451" SG_ 454 IcHuDateInfo 0;
BA_ "GenSigTimeoutMsg_HU_High_X451" SG_ 454 IcHuDateInfo 0;
BA_ "GenSigTimeoutMsg_HU_B" SG_ 454 IcHuDateInfo 0;
BA_ "GenSigTimeoutMsg_HU_A" SG_ 454 IcHuDateInfo 0;
BA_ "GenSigSendType" SG_ 454 IcHuDateInfo 1;
BA_ "GenSigTimeoutMsg_HU_High_X445" SG_ 454 IcHuDateInfo 0;
BA_ "GenSigTimeoutMsg_HU_Mid_X445" SG_ 454 IcHuDateInfo 0;
BA_ "GenSigTimeoutTime_HU_High_X445" SG_ 454 IcHuDateInfo 0;
BA_ "GenSigTimeoutTime_HU_Mid_X445" SG_ 454 IcHuDateInfo 0;
BA_ "GenSigTimeoutMsg_IVI" SG_ 454 IcHuDateInfo 0;
BA_ "GenSigTimeoutTime_IVI" SG_ 454 IcHuDateInfo 0;
BA_ "GenSigTimeoutTime_HU_Mid_X451" SG_ 454 IcHuYearInfo 0;
BA_ "GenSigTimeoutTime_HU_High_X451" SG_ 454 IcHuYearInfo 0;
BA_ "GenSigTimeoutTime_HU_B" SG_ 454 IcHuYearInfo 0;
BA_ "GenSigTimeoutTime_HU_A" SG_ 454 IcHuYearInfo 0;
BA_ "GenSigTimeoutMsg_HU_Mid_X451" SG_ 454 IcHuYearInfo 0;
BA_ "GenSigTimeoutMsg_HU_High_X451" SG_ 454 IcHuYearInfo 0;
BA_ "GenSigTimeoutMsg_HU_B" SG_ 454 IcHuYearInfo 0;
BA_ "GenSigTimeoutMsg_HU_A" SG_ 454 IcHuYearInfo 0;
BA_ "GenSigSendType" SG_ 454 IcHuYearInfo 1;
BA_ "GenSigTimeoutMsg_HU_High_X445" SG_ 454 IcHuYearInfo 0;
BA_ "GenSigTimeoutMsg_HU_Mid_X445" SG_ 454 IcHuYearInfo 0;
BA_ "GenSigTimeoutTime_HU_High_X445" SG_ 454 IcHuYearInfo 0;
BA_ "GenSigTimeoutTime_HU_Mid_X445" SG_ 454 IcHuYearInfo 0;
BA_ "GenSigTimeoutMsg_IVI" SG_ 454 IcHuYearInfo 0;
BA_ "GenSigTimeoutTime_IVI" SG_ 454 IcHuYearInfo 0;
BA_ "GenSigTimeoutTime_HU_Mid_X451" SG_ 454 IcHuMonthInfo 0;
BA_ "GenSigTimeoutTime_HU_High_X451" SG_ 454 IcHuMonthInfo 0;
BA_ "GenSigTimeoutTime_HU_B" SG_ 454 IcHuMonthInfo 0;
BA_ "GenSigTimeoutTime_HU_A" SG_ 454 IcHuMonthInfo 0;
BA_ "GenSigTimeoutMsg_HU_Mid_X451" SG_ 454 IcHuMonthInfo 0;
BA_ "GenSigTimeoutMsg_HU_High_X451" SG_ 454 IcHuMonthInfo 0;
BA_ "GenSigTimeoutMsg_HU_B" SG_ 454 IcHuMonthInfo 0;
BA_ "GenSigTimeoutMsg_HU_A" SG_ 454 IcHuMonthInfo 0;
BA_ "GenSigSendType" SG_ 454 IcHuMonthInfo 1;
BA_ "GenSigTimeoutMsg_HU_High_X445" SG_ 454 IcHuMonthInfo 0;
BA_ "GenSigTimeoutMsg_HU_Mid_X445" SG_ 454 IcHuMonthInfo 0;
BA_ "GenSigTimeoutTime_HU_High_X445" SG_ 454 IcHuMonthInfo 0;
BA_ "GenSigTimeoutTime_HU_Mid_X445" SG_ 454 IcHuMonthInfo 0;
BA_ "GenSigTimeoutMsg_IVI" SG_ 454 IcHuMonthInfo 0;
BA_ "GenSigTimeoutTime_IVI" SG_ 454 IcHuMonthInfo 0;
BA_ "GenSigTimeoutTime_HU_Mid_X451" SG_ 454 IcHuMillisecondsInfo 0;
BA_ "GenSigTimeoutTime_HU_High_X451" SG_ 454 IcHuMillisecondsInfo 0;
BA_ "GenSigTimeoutTime_HU_B" SG_ 454 IcHuMillisecondsInfo 0;
BA_ "GenSigTimeoutTime_HU_A" SG_ 454 IcHuMillisecondsInfo 0;
BA_ "GenSigTimeoutMsg_HU_Mid_X451" SG_ 454 IcHuMillisecondsInfo 0;
BA_ "GenSigTimeoutMsg_HU_High_X451" SG_ 454 IcHuMillisecondsInfo 0;
BA_ "GenSigTimeoutMsg_HU_B" SG_ 454 IcHuMillisecondsInfo 0;
BA_ "GenSigTimeoutMsg_HU_A" SG_ 454 IcHuMillisecondsInfo 0;
BA_ "GenSigSendType" SG_ 454 IcHuMillisecondsInfo 1;
BA_ "GenSigTimeoutMsg_HU_High_X445" SG_ 454 IcHuMillisecondsInfo 0;
BA_ "GenSigTimeoutMsg_HU_Mid_X445" SG_ 454 IcHuMillisecondsInfo 0;
BA_ "GenSigTimeoutTime_HU_High_X445" SG_ 454 IcHuMillisecondsInfo 0;
BA_ "GenSigTimeoutTime_HU_Mid_X445" SG_ 454 IcHuMillisecondsInfo 0;
BA_ "GenSigTimeoutMsg_IVI" SG_ 454 IcHuMillisecondsInfo 0;
BA_ "GenSigTimeoutTime_IVI" SG_ 454 IcHuMillisecondsInfo 0;
BA_ "GenSigTimeoutTime_HU_Mid_X451" SG_ 454 IcLangSettings 0;
BA_ "GenSigTimeoutTime_HU_High_X451" SG_ 454 IcLangSettings 0;
BA_ "GenSigTimeoutTime_HU_B" SG_ 454 IcLangSettings 0;
BA_ "GenSigTimeoutTime_HU_A" SG_ 454 IcLangSettings 0;
BA_ "GenSigTimeoutMsg_HU_Mid_X451" SG_ 454 IcLangSettings 0;
BA_ "GenSigTimeoutMsg_HU_High_X451" SG_ 454 IcLangSettings 0;
BA_ "GenSigTimeoutMsg_HU_B" SG_ 454 IcLangSettings 0;
BA_ "GenSigTimeoutMsg_HU_A" SG_ 454 IcLangSettings 0;
BA_ "GenSigSendType" SG_ 454 IcLangSettings 1;
BA_ "GenSigTimeoutMsg_HU_High_X445" SG_ 454 IcLangSettings 0;
BA_ "GenSigTimeoutMsg_HU_Mid_X445" SG_ 454 IcLangSettings 0;
BA_ "GenSigTimeoutTime_HU_High_X445" SG_ 454 IcLangSettings 0;
BA_ "GenSigTimeoutTime_HU_Mid_X445" SG_ 454 IcLangSettings 0;
BA_ "GenSigTimeoutMsg_IVI" SG_ 454 IcLangSettings 0;
BA_ "GenSigTimeoutTime_IVI" SG_ 454 IcLangSettings 0;
BA_ "GenSigTimeoutTime_HU_Mid_X451" SG_ 457 OdoVCIMFullSig 0;
BA_ "GenSigTimeoutTime_HU_High_X451" SG_ 457 OdoVCIMFullSig 0;
BA_ "GenSigTimeoutTime_HU_B" SG_ 457 OdoVCIMFullSig 0;
BA_ "GenSigTimeoutTime_HU_A" SG_ 457 OdoVCIMFullSig 0;
BA_ "GenSigTimeoutMsg_HU_Mid_X451" SG_ 457 OdoVCIMFullSig 0;
BA_ "GenSigTimeoutMsg_HU_High_X451" SG_ 457 OdoVCIMFullSig 0;
BA_ "GenSigTimeoutMsg_HU_B" SG_ 457 OdoVCIMFullSig 0;
BA_ "GenSigTimeoutMsg_HU_A" SG_ 457 OdoVCIMFullSig 0;
BA_ "GenSigSendType" SG_ 457 OdoVCIMFullSig 2;
BA_ "GenSigTimeoutMsg_HU_High_X445" SG_ 457 OdoVCIMFullSig 0;
BA_ "GenSigTimeoutMsg_HU_Mid_X445" SG_ 457 OdoVCIMFullSig 0;
BA_ "GenSigTimeoutTime_HU_High_X445" SG_ 457 OdoVCIMFullSig 0;
BA_ "GenSigTimeoutTime_HU_Mid_X445" SG_ 457 OdoVCIMFullSig 0;
BA_ "GenSigTimeoutMsg_IVI" SG_ 457 OdoVCIMFullSig 0;
BA_ "GenSigTimeoutTime_IVI" SG_ 457 OdoVCIMFullSig 0;
BA_ "GenSigTimeoutTime_HU_Mid_X451" SG_ 457 OdoICSigAckFrm 0;
BA_ "GenSigTimeoutTime_HU_High_X451" SG_ 457 OdoICSigAckFrm 0;
BA_ "GenSigTimeoutTime_HU_B" SG_ 457 OdoICSigAckFrm 0;
BA_ "GenSigTimeoutTime_HU_A" SG_ 457 OdoICSigAckFrm 0;
BA_ "GenSigTimeoutMsg_HU_Mid_X451" SG_ 457 OdoICSigAckFrm 0;
BA_ "GenSigTimeoutMsg_HU_High_X451" SG_ 457 OdoICSigAckFrm 0;
BA_ "GenSigTimeoutMsg_HU_B" SG_ 457 OdoICSigAckFrm 0;
BA_ "GenSigTimeoutMsg_HU_A" SG_ 457 OdoICSigAckFrm 0;
BA_ "GenSigSendType" SG_ 457 OdoICSigAckFrm 2;
BA_ "GenSigTimeoutMsg_HU_High_X445" SG_ 457 OdoICSigAckFrm 0;
BA_ "GenSigTimeoutMsg_HU_Mid_X445" SG_ 457 OdoICSigAckFrm 0;
BA_ "GenSigTimeoutTime_HU_High_X445" SG_ 457 OdoICSigAckFrm 0;
BA_ "GenSigTimeoutTime_HU_Mid_X445" SG_ 457 OdoICSigAckFrm 0;
BA_ "GenSigTimeoutMsg_IVI" SG_ 457 OdoICSigAckFrm 0;
BA_ "GenSigTimeoutTime_IVI" SG_ 457 OdoICSigAckFrm 0;
BA_ "GenSigTimeoutTime_HU_Mid_X451" SG_ 459 BCmAntitheftFeatureState 0;
BA_ "GenSigTimeoutTime_HU_High_X451" SG_ 459 BCmAntitheftFeatureState 0;
BA_ "GenSigTimeoutTime_HU_B" SG_ 459 BCmAntitheftFeatureState 0;
BA_ "GenSigTimeoutTime_HU_A" SG_ 459 BCmAntitheftFeatureState 0;
BA_ "GenSigTimeoutMsg_HU_Mid_X451" SG_ 459 BCmAntitheftFeatureState 0;
BA_ "GenSigTimeoutMsg_HU_High_X451" SG_ 459 BCmAntitheftFeatureState 0;
BA_ "GenSigTimeoutMsg_HU_B" SG_ 459 BCmAntitheftFeatureState 0;
BA_ "GenSigTimeoutMsg_HU_A" SG_ 459 BCmAntitheftFeatureState 0;
BA_ "GenSigStartValue" SG_ 459 BCmAntitheftFeatureState 1;
BA_ "GenSigSendType" SG_ 459 BCmAntitheftFeatureState 1;
BA_ "GenSigTimeoutMsg_HU_High_X445" SG_ 459 BCmAntitheftFeatureState 0;
BA_ "GenSigTimeoutMsg_HU_Mid_X445" SG_ 459 BCmAntitheftFeatureState 0;
BA_ "GenSigTimeoutTime_HU_High_X445" SG_ 459 BCmAntitheftFeatureState 0;
BA_ "GenSigTimeoutTime_HU_Mid_X445" SG_ 459 BCmAntitheftFeatureState 0;
BA_ "GenSigTimeoutMsg_IVI" SG_ 459 BCmAntitheftFeatureState 0;
BA_ "GenSigTimeoutTime_IVI" SG_ 459 BCmAntitheftFeatureState 0;
BA_ "GenSigTimeoutTime_HU_Mid_X451" SG_ 459 BCmAntitheftKeyConfirmation 0;
BA_ "GenSigTimeoutTime_HU_High_X451" SG_ 459 BCmAntitheftKeyConfirmation 0;
BA_ "GenSigTimeoutTime_HU_B" SG_ 459 BCmAntitheftKeyConfirmation 0;
BA_ "GenSigTimeoutTime_HU_A" SG_ 459 BCmAntitheftKeyConfirmation 0;
BA_ "GenSigTimeoutMsg_HU_Mid_X451" SG_ 459 BCmAntitheftKeyConfirmation 0;
BA_ "GenSigTimeoutMsg_HU_High_X451" SG_ 459 BCmAntitheftKeyConfirmation 0;
BA_ "GenSigTimeoutMsg_HU_B" SG_ 459 BCmAntitheftKeyConfirmation 0;
BA_ "GenSigTimeoutMsg_HU_A" SG_ 459 BCmAntitheftKeyConfirmation 0;
BA_ "GenSigSendType" SG_ 459 BCmAntitheftKeyConfirmation 1;
BA_ "GenSigTimeoutMsg_HU_High_X445" SG_ 459 BCmAntitheftKeyConfirmation 0;
BA_ "GenSigTimeoutMsg_HU_Mid_X445" SG_ 459 BCmAntitheftKeyConfirmation 0;
BA_ "GenSigTimeoutTime_HU_High_X445" SG_ 459 BCmAntitheftKeyConfirmation 0;
BA_ "GenSigTimeoutTime_HU_Mid_X445" SG_ 459 BCmAntitheftKeyConfirmation 0;
BA_ "GenSigTimeoutMsg_IVI" SG_ 459 BCmAntitheftKeyConfirmation 0;
BA_ "GenSigTimeoutTime_IVI" SG_ 459 BCmAntitheftKeyConfirmation 0;
BA_ "GenSigTimeoutTime_HU_Mid_X451" SG_ 459 BcmHuCkdState 0;
BA_ "GenSigTimeoutTime_HU_High_X451" SG_ 459 BcmHuCkdState 0;
BA_ "GenSigTimeoutTime_HU_B" SG_ 459 BcmHuCkdState 0;
BA_ "GenSigTimeoutTime_HU_A" SG_ 459 BcmHuCkdState 0;
BA_ "GenSigTimeoutMsg_HU_Mid_X451" SG_ 459 BcmHuCkdState 0;
BA_ "GenSigTimeoutMsg_HU_High_X451" SG_ 459 BcmHuCkdState 0;
BA_ "GenSigTimeoutMsg_HU_B" SG_ 459 BcmHuCkdState 0;
BA_ "GenSigTimeoutMsg_HU_A" SG_ 459 BcmHuCkdState 0;
BA_ "GenSigSendType" SG_ 459 BcmHuCkdState 1;
BA_ "GenSigTimeoutMsg_HU_High_X445" SG_ 459 BcmHuCkdState 0;
BA_ "GenSigTimeoutMsg_HU_Mid_X445" SG_ 459 BcmHuCkdState 0;
BA_ "GenSigTimeoutTime_HU_High_X445" SG_ 459 BcmHuCkdState 0;
BA_ "GenSigTimeoutTime_HU_Mid_X445" SG_ 459 BcmHuCkdState 0;
BA_ "GenSigTimeoutMsg_IVI" SG_ 459 BcmHuCkdState 0;
BA_ "GenSigTimeoutTime_IVI" SG_ 459 BcmHuCkdState 0;
BA_ "GenSigTimeoutTime_HU_Mid_X451" SG_ 460 HuAntitheftFeatureState 0;
BA_ "GenSigTimeoutTime_HU_High_X451" SG_ 460 HuAntitheftFeatureState 0;
BA_ "GenSigTimeoutTime_HU_B" SG_ 460 HuAntitheftFeatureState 0;
BA_ "GenSigTimeoutTime_HU_A" SG_ 460 HuAntitheftFeatureState 0;
BA_ "GenSigTimeoutMsg_HU_Mid_X451" SG_ 460 HuAntitheftFeatureState 0;
BA_ "GenSigTimeoutMsg_HU_High_X451" SG_ 460 HuAntitheftFeatureState 0;
BA_ "GenSigTimeoutMsg_HU_B" SG_ 460 HuAntitheftFeatureState 0;
BA_ "GenSigTimeoutMsg_HU_A" SG_ 460 HuAntitheftFeatureState 0;
BA_ "GenSigStartValue" SG_ 460 HuAntitheftFeatureState 1;
BA_ "GenSigSendType" SG_ 460 HuAntitheftFeatureState 1;
BA_ "GenSigTimeoutMsg_HU_High_X445" SG_ 460 HuAntitheftFeatureState 0;
BA_ "GenSigTimeoutMsg_HU_Mid_X445" SG_ 460 HuAntitheftFeatureState 0;
BA_ "GenSigTimeoutTime_HU_High_X445" SG_ 460 HuAntitheftFeatureState 0;
BA_ "GenSigTimeoutTime_HU_Mid_X445" SG_ 460 HuAntitheftFeatureState 0;
BA_ "GenSigTimeoutMsg_IVI" SG_ 460 HuAntitheftFeatureState 0;
BA_ "GenSigTimeoutTime_IVI" SG_ 460 HuAntitheftFeatureState 0;
BA_ "GenSigTimeoutTime_HU_Mid_X451" SG_ 460 HuBcmQueryInfo 0;
BA_ "GenSigTimeoutTime_HU_High_X451" SG_ 460 HuBcmQueryInfo 0;
BA_ "GenSigTimeoutTime_HU_B" SG_ 460 HuBcmQueryInfo 0;
BA_ "GenSigTimeoutTime_HU_A" SG_ 460 HuBcmQueryInfo 0;
BA_ "GenSigTimeoutMsg_HU_Mid_X451" SG_ 460 HuBcmQueryInfo 0;
BA_ "GenSigTimeoutMsg_HU_High_X451" SG_ 460 HuBcmQueryInfo 0;
BA_ "GenSigTimeoutMsg_HU_B" SG_ 460 HuBcmQueryInfo 0;
BA_ "GenSigTimeoutMsg_HU_A" SG_ 460 HuBcmQueryInfo 0;
BA_ "GenSigSendType" SG_ 460 HuBcmQueryInfo 1;
BA_ "GenSigTimeoutMsg_HU_High_X445" SG_ 460 HuBcmQueryInfo 0;
BA_ "GenSigTimeoutMsg_HU_Mid_X445" SG_ 460 HuBcmQueryInfo 0;
BA_ "GenSigTimeoutTime_HU_High_X445" SG_ 460 HuBcmQueryInfo 0;
BA_ "GenSigTimeoutTime_HU_Mid_X445" SG_ 460 HuBcmQueryInfo 0;
BA_ "GenSigTimeoutMsg_IVI" SG_ 460 HuBcmQueryInfo 0;
BA_ "GenSigTimeoutTime_IVI" SG_ 460 HuBcmQueryInfo 0;
BA_ "GenSigTimeoutTime_HU_Mid_X451" SG_ 462 BCmAntitheftSeed 0;
BA_ "GenSigTimeoutTime_HU_High_X451" SG_ 462 BCmAntitheftSeed 0;
BA_ "GenSigTimeoutTime_HU_B" SG_ 462 BCmAntitheftSeed 0;
BA_ "GenSigTimeoutTime_HU_A" SG_ 462 BCmAntitheftSeed 0;
BA_ "GenSigTimeoutMsg_HU_Mid_X451" SG_ 462 BCmAntitheftSeed 0;
BA_ "GenSigTimeoutMsg_HU_High_X451" SG_ 462 BCmAntitheftSeed 0;
BA_ "GenSigTimeoutMsg_HU_B" SG_ 462 BCmAntitheftSeed 0;
BA_ "GenSigTimeoutMsg_HU_A" SG_ 462 BCmAntitheftSeed 0;
BA_ "GenSigSendType" SG_ 462 BCmAntitheftSeed 1;
BA_ "GenSigTimeoutMsg_HU_High_X445" SG_ 462 BCmAntitheftSeed 0;
BA_ "GenSigTimeoutMsg_HU_Mid_X445" SG_ 462 BCmAntitheftSeed 0;
BA_ "GenSigTimeoutTime_HU_High_X445" SG_ 462 BCmAntitheftSeed 0;
BA_ "GenSigTimeoutTime_HU_Mid_X445" SG_ 462 BCmAntitheftSeed 0;
BA_ "GenSigTimeoutMsg_IVI" SG_ 462 BCmAntitheftSeed 0;
BA_ "GenSigTimeoutTime_IVI" SG_ 462 BCmAntitheftSeed 0;
BA_ "GenSigTimeoutTime_HU_Mid_X451" SG_ 463 BCmAntitheftKey 0;
BA_ "GenSigTimeoutTime_HU_High_X451" SG_ 463 BCmAntitheftKey 0;
BA_ "GenSigTimeoutTime_HU_B" SG_ 463 BCmAntitheftKey 0;
BA_ "GenSigTimeoutTime_HU_A" SG_ 463 BCmAntitheftKey 0;
BA_ "GenSigTimeoutMsg_HU_Mid_X451" SG_ 463 BCmAntitheftKey 0;
BA_ "GenSigTimeoutMsg_HU_High_X451" SG_ 463 BCmAntitheftKey 0;
BA_ "GenSigTimeoutMsg_HU_B" SG_ 463 BCmAntitheftKey 0;
BA_ "GenSigTimeoutMsg_HU_A" SG_ 463 BCmAntitheftKey 0;
BA_ "GenSigSendType" SG_ 463 BCmAntitheftKey 1;
BA_ "GenSigTimeoutMsg_HU_High_X445" SG_ 463 BCmAntitheftKey 0;
BA_ "GenSigTimeoutMsg_HU_Mid_X445" SG_ 463 BCmAntitheftKey 0;
BA_ "GenSigTimeoutTime_HU_High_X445" SG_ 463 BCmAntitheftKey 0;
BA_ "GenSigTimeoutTime_HU_Mid_X445" SG_ 463 BCmAntitheftKey 0;
BA_ "GenSigTimeoutMsg_IVI" SG_ 463 BCmAntitheftKey 0;
BA_ "GenSigTimeoutTime_IVI" SG_ 463 BCmAntitheftKey 0;
BA_ "GenSigTimeoutTime_HU_Mid_X451" SG_ 464 HuIcDriveproConfig 0;
BA_ "GenSigTimeoutTime_HU_High_X451" SG_ 464 HuIcDriveproConfig 0;
BA_ "GenSigTimeoutTime_HU_B" SG_ 464 HuIcDriveproConfig 0;
BA_ "GenSigTimeoutTime_HU_A" SG_ 464 HuIcDriveproConfig 0;
BA_ "GenSigTimeoutMsg_HU_Mid_X451" SG_ 464 HuIcDriveproConfig 0;
BA_ "GenSigTimeoutMsg_HU_High_X451" SG_ 464 HuIcDriveproConfig 0;
BA_ "GenSigTimeoutMsg_HU_B" SG_ 464 HuIcDriveproConfig 0;
BA_ "GenSigTimeoutMsg_HU_A" SG_ 464 HuIcDriveproConfig 0;
BA_ "GenSigSendType" SG_ 464 HuIcDriveproConfig 1;
BA_ "GenSigTimeoutMsg_HU_High_X445" SG_ 464 HuIcDriveproConfig 0;
BA_ "GenSigTimeoutMsg_HU_Mid_X445" SG_ 464 HuIcDriveproConfig 0;
BA_ "GenSigTimeoutTime_HU_High_X445" SG_ 464 HuIcDriveproConfig 0;
BA_ "GenSigTimeoutTime_HU_Mid_X445" SG_ 464 HuIcDriveproConfig 0;
BA_ "GenSigTimeoutMsg_IVI" SG_ 464 HuIcDriveproConfig 0;
BA_ "GenSigTimeoutTime_IVI" SG_ 464 HuIcDriveproConfig 0;
BA_ "GenSigTimeoutTime_HU_Mid_X451" SG_ 464 HuIcDriveProConfigEventStatus 0;
BA_ "GenSigTimeoutTime_HU_High_X451" SG_ 464 HuIcDriveProConfigEventStatus 0;
BA_ "GenSigTimeoutTime_HU_B" SG_ 464 HuIcDriveProConfigEventStatus 0;
BA_ "GenSigTimeoutTime_HU_A" SG_ 464 HuIcDriveProConfigEventStatus 0;
BA_ "GenSigTimeoutMsg_HU_Mid_X451" SG_ 464 HuIcDriveProConfigEventStatus 0;
BA_ "GenSigTimeoutMsg_HU_High_X451" SG_ 464 HuIcDriveProConfigEventStatus 0;
BA_ "GenSigTimeoutMsg_HU_B" SG_ 464 HuIcDriveProConfigEventStatus 0;
BA_ "GenSigTimeoutMsg_HU_A" SG_ 464 HuIcDriveProConfigEventStatus 0;
BA_ "GenSigSendType" SG_ 464 HuIcDriveProConfigEventStatus 1;
BA_ "GenSigTimeoutMsg_HU_High_X445" SG_ 464 HuIcDriveProConfigEventStatus 0;
BA_ "GenSigTimeoutMsg_HU_Mid_X445" SG_ 464 HuIcDriveProConfigEventStatus 0;
BA_ "GenSigTimeoutTime_HU_High_X445" SG_ 464 HuIcDriveProConfigEventStatus 0;
BA_ "GenSigTimeoutTime_HU_Mid_X445" SG_ 464 HuIcDriveProConfigEventStatus 0;
BA_ "GenSigTimeoutMsg_IVI" SG_ 464 HuIcDriveProConfigEventStatus 0;
BA_ "GenSigTimeoutTime_IVI" SG_ 464 HuIcDriveProConfigEventStatus 0;
BA_ "GenSigTimeoutTime_HU_Mid_X451" SG_ 464 HuIcTripAReset 0;
BA_ "GenSigTimeoutTime_HU_High_X451" SG_ 464 HuIcTripAReset 0;
BA_ "GenSigTimeoutTime_HU_B" SG_ 464 HuIcTripAReset 0;
BA_ "GenSigTimeoutTime_HU_A" SG_ 464 HuIcTripAReset 0;
BA_ "GenSigTimeoutMsg_HU_Mid_X451" SG_ 464 HuIcTripAReset 0;
BA_ "GenSigTimeoutMsg_HU_High_X451" SG_ 464 HuIcTripAReset 0;
BA_ "GenSigTimeoutMsg_HU_B" SG_ 464 HuIcTripAReset 0;
BA_ "GenSigTimeoutMsg_HU_A" SG_ 464 HuIcTripAReset 0;
BA_ "GenSigSendType" SG_ 464 HuIcTripAReset 1;
BA_ "GenSigTimeoutMsg_HU_High_X445" SG_ 464 HuIcTripAReset 0;
BA_ "GenSigTimeoutMsg_HU_Mid_X445" SG_ 464 HuIcTripAReset 0;
BA_ "GenSigTimeoutTime_HU_High_X445" SG_ 464 HuIcTripAReset 0;
BA_ "GenSigTimeoutTime_HU_Mid_X445" SG_ 464 HuIcTripAReset 0;
BA_ "GenSigTimeoutMsg_IVI" SG_ 464 HuIcTripAReset 0;
BA_ "GenSigTimeoutTime_IVI" SG_ 464 HuIcTripAReset 0;
BA_ "GenSigTimeoutTime_HU_Mid_X451" SG_ 464 HuIcTripAResetAck 0;
BA_ "GenSigTimeoutTime_HU_High_X451" SG_ 464 HuIcTripAResetAck 0;
BA_ "GenSigTimeoutTime_HU_B" SG_ 464 HuIcTripAResetAck 0;
BA_ "GenSigTimeoutTime_HU_A" SG_ 464 HuIcTripAResetAck 0;
BA_ "GenSigTimeoutMsg_HU_Mid_X451" SG_ 464 HuIcTripAResetAck 0;
BA_ "GenSigTimeoutMsg_HU_High_X451" SG_ 464 HuIcTripAResetAck 0;
BA_ "GenSigTimeoutMsg_HU_B" SG_ 464 HuIcTripAResetAck 0;
BA_ "GenSigTimeoutMsg_HU_A" SG_ 464 HuIcTripAResetAck 0;
BA_ "GenSigSendType" SG_ 464 HuIcTripAResetAck 1;
BA_ "GenSigTimeoutMsg_HU_High_X445" SG_ 464 HuIcTripAResetAck 0;
BA_ "GenSigTimeoutMsg_HU_Mid_X445" SG_ 464 HuIcTripAResetAck 0;
BA_ "GenSigTimeoutTime_HU_High_X445" SG_ 464 HuIcTripAResetAck 0;
BA_ "GenSigTimeoutTime_HU_Mid_X445" SG_ 464 HuIcTripAResetAck 0;
BA_ "GenSigTimeoutMsg_IVI" SG_ 464 HuIcTripAResetAck 0;
BA_ "GenSigTimeoutTime_IVI" SG_ 464 HuIcTripAResetAck 0;
BA_ "GenSigTimeoutTime_HU_Mid_X451" SG_ 464 HuIcTripBReset 0;
BA_ "GenSigTimeoutTime_HU_High_X451" SG_ 464 HuIcTripBReset 0;
BA_ "GenSigTimeoutTime_HU_B" SG_ 464 HuIcTripBReset 0;
BA_ "GenSigTimeoutTime_HU_A" SG_ 464 HuIcTripBReset 0;
BA_ "GenSigTimeoutMsg_HU_Mid_X451" SG_ 464 HuIcTripBReset 0;
BA_ "GenSigTimeoutMsg_HU_High_X451" SG_ 464 HuIcTripBReset 0;
BA_ "GenSigTimeoutMsg_HU_B" SG_ 464 HuIcTripBReset 0;
BA_ "GenSigTimeoutMsg_HU_A" SG_ 464 HuIcTripBReset 0;
BA_ "GenSigSendType" SG_ 464 HuIcTripBReset 1;
BA_ "GenSigTimeoutMsg_HU_High_X445" SG_ 464 HuIcTripBReset 0;
BA_ "GenSigTimeoutMsg_HU_Mid_X445" SG_ 464 HuIcTripBReset 0;
BA_ "GenSigTimeoutTime_HU_High_X445" SG_ 464 HuIcTripBReset 0;
BA_ "GenSigTimeoutTime_HU_Mid_X445" SG_ 464 HuIcTripBReset 0;
BA_ "GenSigTimeoutMsg_IVI" SG_ 464 HuIcTripBReset 0;
BA_ "GenSigTimeoutTime_IVI" SG_ 464 HuIcTripBReset 0;
BA_ "GenSigTimeoutTime_HU_Mid_X451" SG_ 464 HuIcTripBResetAck 0;
BA_ "GenSigTimeoutTime_HU_High_X451" SG_ 464 HuIcTripBResetAck 0;
BA_ "GenSigTimeoutTime_HU_B" SG_ 464 HuIcTripBResetAck 0;
BA_ "GenSigTimeoutTime_HU_A" SG_ 464 HuIcTripBResetAck 0;
BA_ "GenSigTimeoutMsg_HU_Mid_X451" SG_ 464 HuIcTripBResetAck 0;
BA_ "GenSigTimeoutMsg_HU_High_X451" SG_ 464 HuIcTripBResetAck 0;
BA_ "GenSigTimeoutMsg_HU_B" SG_ 464 HuIcTripBResetAck 0;
BA_ "GenSigTimeoutMsg_HU_A" SG_ 464 HuIcTripBResetAck 0;
BA_ "GenSigSendType" SG_ 464 HuIcTripBResetAck 1;
BA_ "GenSigTimeoutMsg_HU_High_X445" SG_ 464 HuIcTripBResetAck 0;
BA_ "GenSigTimeoutMsg_HU_Mid_X445" SG_ 464 HuIcTripBResetAck 0;
BA_ "GenSigTimeoutTime_HU_High_X445" SG_ 464 HuIcTripBResetAck 0;
BA_ "GenSigTimeoutTime_HU_Mid_X445" SG_ 464 HuIcTripBResetAck 0;
BA_ "GenSigTimeoutMsg_IVI" SG_ 464 HuIcTripBResetAck 0;
BA_ "GenSigTimeoutTime_IVI" SG_ 464 HuIcTripBResetAck 0;
BA_ "GenSigTimeoutTime_HU_Mid_X451" SG_ 464 HuIcResetAll 0;
BA_ "GenSigTimeoutTime_HU_High_X451" SG_ 464 HuIcResetAll 0;
BA_ "GenSigTimeoutTime_HU_B" SG_ 464 HuIcResetAll 0;
BA_ "GenSigTimeoutTime_HU_A" SG_ 464 HuIcResetAll 0;
BA_ "GenSigTimeoutMsg_HU_Mid_X451" SG_ 464 HuIcResetAll 0;
BA_ "GenSigTimeoutMsg_HU_High_X451" SG_ 464 HuIcResetAll 0;
BA_ "GenSigTimeoutMsg_HU_B" SG_ 464 HuIcResetAll 0;
BA_ "GenSigTimeoutMsg_HU_A" SG_ 464 HuIcResetAll 0;
BA_ "GenSigSendType" SG_ 464 HuIcResetAll 1;
BA_ "GenSigTimeoutMsg_HU_High_X445" SG_ 464 HuIcResetAll 0;
BA_ "GenSigTimeoutMsg_HU_Mid_X445" SG_ 464 HuIcResetAll 0;
BA_ "GenSigTimeoutTime_HU_High_X445" SG_ 464 HuIcResetAll 0;
BA_ "GenSigTimeoutTime_HU_Mid_X445" SG_ 464 HuIcResetAll 0;
BA_ "GenSigTimeoutMsg_IVI" SG_ 464 HuIcResetAll 0;
BA_ "GenSigTimeoutTime_IVI" SG_ 464 HuIcResetAll 0;
BA_ "GenSigTimeoutTime_HU_Mid_X451" SG_ 464 HuIcTripResetAckEventStatus 0;
BA_ "GenSigTimeoutTime_HU_High_X451" SG_ 464 HuIcTripResetAckEventStatus 0;
BA_ "GenSigTimeoutTime_HU_B" SG_ 464 HuIcTripResetAckEventStatus 0;
BA_ "GenSigTimeoutTime_HU_A" SG_ 464 HuIcTripResetAckEventStatus 0;
BA_ "GenSigTimeoutMsg_HU_Mid_X451" SG_ 464 HuIcTripResetAckEventStatus 0;
BA_ "GenSigTimeoutMsg_HU_High_X451" SG_ 464 HuIcTripResetAckEventStatus 0;
BA_ "GenSigTimeoutMsg_HU_B" SG_ 464 HuIcTripResetAckEventStatus 0;
BA_ "GenSigTimeoutMsg_HU_A" SG_ 464 HuIcTripResetAckEventStatus 0;
BA_ "GenSigSendType" SG_ 464 HuIcTripResetAckEventStatus 1;
BA_ "GenSigTimeoutMsg_HU_High_X445" SG_ 464 HuIcTripResetAckEventStatus 0;
BA_ "GenSigTimeoutMsg_HU_Mid_X445" SG_ 464 HuIcTripResetAckEventStatus 0;
BA_ "GenSigTimeoutTime_HU_High_X445" SG_ 464 HuIcTripResetAckEventStatus 0;
BA_ "GenSigTimeoutTime_HU_Mid_X445" SG_ 464 HuIcTripResetAckEventStatus 0;
BA_ "GenSigTimeoutMsg_IVI" SG_ 464 HuIcTripResetAckEventStatus 0;
BA_ "GenSigTimeoutTime_IVI" SG_ 464 HuIcTripResetAckEventStatus 0;
BA_ "GenSigTimeoutTime_HU_Mid_X451" SG_ 464 HuIcTripResetEventStatus 0;
BA_ "GenSigTimeoutTime_HU_High_X451" SG_ 464 HuIcTripResetEventStatus 0;
BA_ "GenSigTimeoutTime_HU_B" SG_ 464 HuIcTripResetEventStatus 0;
BA_ "GenSigTimeoutTime_HU_A" SG_ 464 HuIcTripResetEventStatus 0;
BA_ "GenSigTimeoutMsg_HU_Mid_X451" SG_ 464 HuIcTripResetEventStatus 0;
BA_ "GenSigTimeoutMsg_HU_High_X451" SG_ 464 HuIcTripResetEventStatus 0;
BA_ "GenSigTimeoutMsg_HU_B" SG_ 464 HuIcTripResetEventStatus 0;
BA_ "GenSigTimeoutMsg_HU_A" SG_ 464 HuIcTripResetEventStatus 0;
BA_ "GenSigSendType" SG_ 464 HuIcTripResetEventStatus 1;
BA_ "GenSigTimeoutMsg_HU_High_X445" SG_ 464 HuIcTripResetEventStatus 0;
BA_ "GenSigTimeoutMsg_HU_Mid_X445" SG_ 464 HuIcTripResetEventStatus 0;
BA_ "GenSigTimeoutTime_HU_High_X445" SG_ 464 HuIcTripResetEventStatus 0;
BA_ "GenSigTimeoutTime_HU_Mid_X445" SG_ 464 HuIcTripResetEventStatus 0;
BA_ "GenSigTimeoutMsg_IVI" SG_ 464 HuIcTripResetEventStatus 0;
BA_ "GenSigTimeoutTime_IVI" SG_ 464 HuIcTripResetEventStatus 0;
BA_ "GenSigTimeoutTime_HU_Mid_X451" SG_ 464 HuIcOverallTripReset 0;
BA_ "GenSigTimeoutTime_HU_High_X451" SG_ 464 HuIcOverallTripReset 0;
BA_ "GenSigTimeoutTime_HU_B" SG_ 464 HuIcOverallTripReset 0;
BA_ "GenSigTimeoutTime_HU_A" SG_ 464 HuIcOverallTripReset 0;
BA_ "GenSigTimeoutMsg_HU_Mid_X451" SG_ 464 HuIcOverallTripReset 0;
BA_ "GenSigTimeoutMsg_HU_High_X451" SG_ 464 HuIcOverallTripReset 0;
BA_ "GenSigTimeoutMsg_HU_B" SG_ 464 HuIcOverallTripReset 0;
BA_ "GenSigTimeoutMsg_HU_A" SG_ 464 HuIcOverallTripReset 0;
BA_ "GenSigSendType" SG_ 464 HuIcOverallTripReset 1;
BA_ "GenSigTimeoutMsg_HU_High_X445" SG_ 464 HuIcOverallTripReset 0;
BA_ "GenSigTimeoutMsg_HU_Mid_X445" SG_ 464 HuIcOverallTripReset 0;
BA_ "GenSigTimeoutTime_HU_High_X445" SG_ 464 HuIcOverallTripReset 0;
BA_ "GenSigTimeoutTime_HU_Mid_X445" SG_ 464 HuIcOverallTripReset 0;
BA_ "GenSigTimeoutMsg_IVI" SG_ 464 HuIcOverallTripReset 0;
BA_ "GenSigTimeoutTime_IVI" SG_ 464 HuIcOverallTripReset 0;
BA_ "GenSigTimeoutTime_HU_Mid_X451" SG_ 464 HuIcOverallTripResetAck 0;
BA_ "GenSigTimeoutTime_HU_High_X451" SG_ 464 HuIcOverallTripResetAck 0;
BA_ "GenSigTimeoutTime_HU_B" SG_ 464 HuIcOverallTripResetAck 0;
BA_ "GenSigTimeoutTime_HU_A" SG_ 464 HuIcOverallTripResetAck 0;
BA_ "GenSigTimeoutMsg_HU_Mid_X451" SG_ 464 HuIcOverallTripResetAck 0;
BA_ "GenSigTimeoutMsg_HU_High_X451" SG_ 464 HuIcOverallTripResetAck 0;
BA_ "GenSigTimeoutMsg_HU_B" SG_ 464 HuIcOverallTripResetAck 0;
BA_ "GenSigTimeoutMsg_HU_A" SG_ 464 HuIcOverallTripResetAck 0;
BA_ "GenSigSendType" SG_ 464 HuIcOverallTripResetAck 1;
BA_ "GenSigTimeoutMsg_HU_High_X445" SG_ 464 HuIcOverallTripResetAck 0;
BA_ "GenSigTimeoutMsg_HU_Mid_X445" SG_ 464 HuIcOverallTripResetAck 0;
BA_ "GenSigTimeoutTime_HU_High_X445" SG_ 464 HuIcOverallTripResetAck 0;
BA_ "GenSigTimeoutTime_HU_Mid_X445" SG_ 464 HuIcOverallTripResetAck 0;
BA_ "GenSigTimeoutMsg_IVI" SG_ 464 HuIcOverallTripResetAck 0;
BA_ "GenSigTimeoutTime_IVI" SG_ 464 HuIcOverallTripResetAck 0;
BA_ "GenSigTimeoutTime_HU_Mid_X451" SG_ 464 HuIcResetAllAck 0;
BA_ "GenSigTimeoutTime_HU_High_X451" SG_ 464 HuIcResetAllAck 0;
BA_ "GenSigTimeoutTime_HU_B" SG_ 464 HuIcResetAllAck 0;
BA_ "GenSigTimeoutTime_HU_A" SG_ 464 HuIcResetAllAck 0;
BA_ "GenSigTimeoutMsg_HU_Mid_X451" SG_ 464 HuIcResetAllAck 0;
BA_ "GenSigTimeoutMsg_HU_High_X451" SG_ 464 HuIcResetAllAck 0;
BA_ "GenSigTimeoutMsg_HU_B" SG_ 464 HuIcResetAllAck 0;
BA_ "GenSigTimeoutMsg_HU_A" SG_ 464 HuIcResetAllAck 0;
BA_ "GenSigSendType" SG_ 464 HuIcResetAllAck 1;
BA_ "GenSigTimeoutMsg_HU_High_X445" SG_ 464 HuIcResetAllAck 0;
BA_ "GenSigTimeoutMsg_HU_Mid_X445" SG_ 464 HuIcResetAllAck 0;
BA_ "GenSigTimeoutTime_HU_High_X445" SG_ 464 HuIcResetAllAck 0;
BA_ "GenSigTimeoutTime_HU_Mid_X445" SG_ 464 HuIcResetAllAck 0;
BA_ "GenSigTimeoutMsg_IVI" SG_ 464 HuIcResetAllAck 0;
BA_ "GenSigTimeoutTime_IVI" SG_ 464 HuIcResetAllAck 0;
BA_ "GenSigTimeoutTime_HU_Mid_X451" SG_ 466 PDcOnDelayTimerReq 0;
BA_ "GenSigTimeoutTime_HU_High_X451" SG_ 466 PDcOnDelayTimerReq 0;
BA_ "GenSigTimeoutTime_HU_B" SG_ 466 PDcOnDelayTimerReq 0;
BA_ "GenSigTimeoutTime_HU_A" SG_ 466 PDcOnDelayTimerReq 0;
BA_ "GenSigTimeoutMsg_HU_Mid_X451" SG_ 466 PDcOnDelayTimerReq 0;
BA_ "GenSigTimeoutMsg_HU_High_X451" SG_ 466 PDcOnDelayTimerReq 0;
BA_ "GenSigTimeoutMsg_HU_B" SG_ 466 PDcOnDelayTimerReq 0;
BA_ "GenSigTimeoutMsg_HU_A" SG_ 466 PDcOnDelayTimerReq 0;
BA_ "GenSigSendType" SG_ 466 PDcOnDelayTimerReq 1;
BA_ "GenSigTimeoutMsg_HU_High_X445" SG_ 466 PDcOnDelayTimerReq 0;
BA_ "GenSigTimeoutMsg_HU_Mid_X445" SG_ 466 PDcOnDelayTimerReq 0;
BA_ "GenSigTimeoutTime_HU_High_X445" SG_ 466 PDcOnDelayTimerReq 0;
BA_ "GenSigTimeoutTime_HU_Mid_X445" SG_ 466 PDcOnDelayTimerReq 0;
BA_ "GenSigTimeoutMsg_IVI" SG_ 466 PDcOnDelayTimerReq 0;
BA_ "GenSigTimeoutTime_IVI" SG_ 466 PDcOnDelayTimerReq 0;
BA_ "GenSigTimeoutTime_HU_Mid_X451" SG_ 466 HuPDcVehicleImageAck 0;
BA_ "GenSigTimeoutTime_HU_High_X451" SG_ 466 HuPDcVehicleImageAck 0;
BA_ "GenSigTimeoutTime_HU_B" SG_ 466 HuPDcVehicleImageAck 0;
BA_ "GenSigTimeoutTime_HU_A" SG_ 466 HuPDcVehicleImageAck 0;
BA_ "GenSigTimeoutMsg_HU_Mid_X451" SG_ 466 HuPDcVehicleImageAck 0;
BA_ "GenSigTimeoutMsg_HU_High_X451" SG_ 466 HuPDcVehicleImageAck 0;
BA_ "GenSigTimeoutMsg_HU_B" SG_ 466 HuPDcVehicleImageAck 0;
BA_ "GenSigTimeoutMsg_HU_A" SG_ 466 HuPDcVehicleImageAck 0;
BA_ "GenSigSendType" SG_ 466 HuPDcVehicleImageAck 1;
BA_ "GenSigTimeoutMsg_HU_High_X445" SG_ 466 HuPDcVehicleImageAck 0;
BA_ "GenSigTimeoutMsg_HU_Mid_X445" SG_ 466 HuPDcVehicleImageAck 0;
BA_ "GenSigTimeoutTime_HU_High_X445" SG_ 466 HuPDcVehicleImageAck 0;
BA_ "GenSigTimeoutTime_HU_Mid_X445" SG_ 466 HuPDcVehicleImageAck 0;
BA_ "GenSigTimeoutMsg_IVI" SG_ 466 HuPDcVehicleImageAck 0;
BA_ "GenSigTimeoutTime_IVI" SG_ 466 HuPDcVehicleImageAck 0;
BA_ "GenSigTimeoutTime_HU_Mid_X451" SG_ 466 PDcLowSpeedActivationReq 0;
BA_ "GenSigTimeoutTime_HU_High_X451" SG_ 466 PDcLowSpeedActivationReq 0;
BA_ "GenSigTimeoutTime_HU_B" SG_ 466 PDcLowSpeedActivationReq 0;
BA_ "GenSigTimeoutTime_HU_A" SG_ 466 PDcLowSpeedActivationReq 0;
BA_ "GenSigTimeoutMsg_HU_Mid_X451" SG_ 466 PDcLowSpeedActivationReq 0;
BA_ "GenSigTimeoutMsg_HU_High_X451" SG_ 466 PDcLowSpeedActivationReq 0;
BA_ "GenSigTimeoutMsg_HU_B" SG_ 466 PDcLowSpeedActivationReq 0;
BA_ "GenSigTimeoutMsg_HU_A" SG_ 466 PDcLowSpeedActivationReq 0;
BA_ "GenSigSendType" SG_ 466 PDcLowSpeedActivationReq 1;
BA_ "GenSigTimeoutMsg_HU_High_X445" SG_ 466 PDcLowSpeedActivationReq 0;
BA_ "GenSigTimeoutMsg_HU_Mid_X445" SG_ 466 PDcLowSpeedActivationReq 0;
BA_ "GenSigTimeoutTime_HU_High_X445" SG_ 466 PDcLowSpeedActivationReq 0;
BA_ "GenSigTimeoutTime_HU_Mid_X445" SG_ 466 PDcLowSpeedActivationReq 0;
BA_ "GenSigTimeoutMsg_IVI" SG_ 466 PDcLowSpeedActivationReq 0;
BA_ "GenSigTimeoutTime_IVI" SG_ 466 PDcLowSpeedActivationReq 0;
BA_ "GenSigTimeoutTime_HU_Mid_X451" SG_ 466 PDcRearToneReq 0;
BA_ "GenSigTimeoutTime_HU_High_X451" SG_ 466 PDcRearToneReq 0;
BA_ "GenSigTimeoutTime_HU_B" SG_ 466 PDcRearToneReq 0;
BA_ "GenSigTimeoutTime_HU_A" SG_ 466 PDcRearToneReq 0;
BA_ "GenSigTimeoutMsg_HU_Mid_X451" SG_ 466 PDcRearToneReq 0;
BA_ "GenSigTimeoutMsg_HU_High_X451" SG_ 466 PDcRearToneReq 0;
BA_ "GenSigTimeoutMsg_HU_B" SG_ 466 PDcRearToneReq 0;
BA_ "GenSigTimeoutMsg_HU_A" SG_ 466 PDcRearToneReq 0;
BA_ "GenSigSendType" SG_ 466 PDcRearToneReq 1;
BA_ "GenSigTimeoutMsg_HU_High_X445" SG_ 466 PDcRearToneReq 0;
BA_ "GenSigTimeoutMsg_HU_Mid_X445" SG_ 466 PDcRearToneReq 0;
BA_ "GenSigTimeoutTime_HU_High_X445" SG_ 466 PDcRearToneReq 0;
BA_ "GenSigTimeoutTime_HU_Mid_X445" SG_ 466 PDcRearToneReq 0;
BA_ "GenSigTimeoutMsg_IVI" SG_ 466 PDcRearToneReq 0;
BA_ "GenSigTimeoutTime_IVI" SG_ 466 PDcRearToneReq 0;
BA_ "GenSigTimeoutTime_HU_Mid_X451" SG_ 466 HuPDcFrontAudioMuteStateAck 0;
BA_ "GenSigTimeoutTime_HU_High_X451" SG_ 466 HuPDcFrontAudioMuteStateAck 0;
BA_ "GenSigTimeoutTime_HU_B" SG_ 466 HuPDcFrontAudioMuteStateAck 0;
BA_ "GenSigTimeoutTime_HU_A" SG_ 466 HuPDcFrontAudioMuteStateAck 0;
BA_ "GenSigTimeoutMsg_HU_Mid_X451" SG_ 466 HuPDcFrontAudioMuteStateAck 0;
BA_ "GenSigTimeoutMsg_HU_High_X451" SG_ 466 HuPDcFrontAudioMuteStateAck 0;
BA_ "GenSigTimeoutMsg_HU_B" SG_ 466 HuPDcFrontAudioMuteStateAck 0;
BA_ "GenSigTimeoutMsg_HU_A" SG_ 466 HuPDcFrontAudioMuteStateAck 0;
BA_ "GenSigSendType" SG_ 466 HuPDcFrontAudioMuteStateAck 1;
BA_ "GenSigTimeoutMsg_HU_High_X445" SG_ 466 HuPDcFrontAudioMuteStateAck 0;
BA_ "GenSigTimeoutMsg_HU_Mid_X445" SG_ 466 HuPDcFrontAudioMuteStateAck 0;
BA_ "GenSigTimeoutTime_HU_High_X445" SG_ 466 HuPDcFrontAudioMuteStateAck 0;
BA_ "GenSigTimeoutTime_HU_Mid_X445" SG_ 466 HuPDcFrontAudioMuteStateAck 0;
BA_ "GenSigTimeoutMsg_IVI" SG_ 466 HuPDcFrontAudioMuteStateAck 0;
BA_ "GenSigTimeoutTime_IVI" SG_ 466 HuPDcFrontAudioMuteStateAck 0;
BA_ "GenSigTimeoutTime_HU_Mid_X451" SG_ 466 HuPDcRearNoOfSensAck 0;
BA_ "GenSigTimeoutTime_HU_High_X451" SG_ 466 HuPDcRearNoOfSensAck 0;
BA_ "GenSigTimeoutTime_HU_B" SG_ 466 HuPDcRearNoOfSensAck 0;
BA_ "GenSigTimeoutTime_HU_A" SG_ 466 HuPDcRearNoOfSensAck 0;
BA_ "GenSigTimeoutMsg_HU_Mid_X451" SG_ 466 HuPDcRearNoOfSensAck 0;
BA_ "GenSigTimeoutMsg_HU_High_X451" SG_ 466 HuPDcRearNoOfSensAck 0;
BA_ "GenSigTimeoutMsg_HU_B" SG_ 466 HuPDcRearNoOfSensAck 0;
BA_ "GenSigTimeoutMsg_HU_A" SG_ 466 HuPDcRearNoOfSensAck 0;
BA_ "GenSigSendType" SG_ 466 HuPDcRearNoOfSensAck 1;
BA_ "GenSigTimeoutMsg_HU_High_X445" SG_ 466 HuPDcRearNoOfSensAck 0;
BA_ "GenSigTimeoutMsg_HU_Mid_X445" SG_ 466 HuPDcRearNoOfSensAck 0;
BA_ "GenSigTimeoutTime_HU_High_X445" SG_ 466 HuPDcRearNoOfSensAck 0;
BA_ "GenSigTimeoutTime_HU_Mid_X445" SG_ 466 HuPDcRearNoOfSensAck 0;
BA_ "GenSigTimeoutMsg_IVI" SG_ 466 HuPDcRearNoOfSensAck 0;
BA_ "GenSigTimeoutTime_IVI" SG_ 466 HuPDcRearNoOfSensAck 0;
BA_ "GenSigTimeoutTime_HU_Mid_X451" SG_ 466 PDcToneVolumeReq 0;
BA_ "GenSigTimeoutTime_HU_High_X451" SG_ 466 PDcToneVolumeReq 0;
BA_ "GenSigTimeoutTime_HU_B" SG_ 466 PDcToneVolumeReq 0;
BA_ "GenSigTimeoutTime_HU_A" SG_ 466 PDcToneVolumeReq 0;
BA_ "GenSigTimeoutMsg_HU_Mid_X451" SG_ 466 PDcToneVolumeReq 0;
BA_ "GenSigTimeoutMsg_HU_High_X451" SG_ 466 PDcToneVolumeReq 0;
BA_ "GenSigTimeoutMsg_HU_B" SG_ 466 PDcToneVolumeReq 0;
BA_ "GenSigTimeoutMsg_HU_A" SG_ 466 PDcToneVolumeReq 0;
BA_ "GenSigStartValue" SG_ 466 PDcToneVolumeReq 1;
BA_ "GenSigSendType" SG_ 466 PDcToneVolumeReq 1;
BA_ "GenSigTimeoutMsg_HU_High_X445" SG_ 466 PDcToneVolumeReq 0;
BA_ "GenSigTimeoutMsg_HU_Mid_X445" SG_ 466 PDcToneVolumeReq 0;
BA_ "GenSigTimeoutTime_HU_High_X445" SG_ 466 PDcToneVolumeReq 0;
BA_ "GenSigTimeoutTime_HU_Mid_X445" SG_ 466 PDcToneVolumeReq 0;
BA_ "GenSigTimeoutMsg_IVI" SG_ 466 PDcToneVolumeReq 0;
BA_ "GenSigTimeoutTime_IVI" SG_ 466 PDcToneVolumeReq 0;
BA_ "GenSigTimeoutTime_HU_Mid_X451" SG_ 466 HuPDcOnDelayTimerAck 0;
BA_ "GenSigTimeoutTime_HU_High_X451" SG_ 466 HuPDcOnDelayTimerAck 0;
BA_ "GenSigTimeoutTime_HU_B" SG_ 466 HuPDcOnDelayTimerAck 0;
BA_ "GenSigTimeoutTime_HU_A" SG_ 466 HuPDcOnDelayTimerAck 0;
BA_ "GenSigTimeoutMsg_HU_Mid_X451" SG_ 466 HuPDcOnDelayTimerAck 0;
BA_ "GenSigTimeoutMsg_HU_High_X451" SG_ 466 HuPDcOnDelayTimerAck 0;
BA_ "GenSigTimeoutMsg_HU_B" SG_ 466 HuPDcOnDelayTimerAck 0;
BA_ "GenSigTimeoutMsg_HU_A" SG_ 466 HuPDcOnDelayTimerAck 0;
BA_ "GenSigStartValue" SG_ 466 HuPDcOnDelayTimerAck 1;
BA_ "GenSigSendType" SG_ 466 HuPDcOnDelayTimerAck 1;
BA_ "GenSigTimeoutMsg_HU_High_X445" SG_ 466 HuPDcOnDelayTimerAck 0;
BA_ "GenSigTimeoutMsg_HU_Mid_X445" SG_ 466 HuPDcOnDelayTimerAck 0;
BA_ "GenSigTimeoutTime_HU_High_X445" SG_ 466 HuPDcOnDelayTimerAck 0;
BA_ "GenSigTimeoutTime_HU_Mid_X445" SG_ 466 HuPDcOnDelayTimerAck 0;
BA_ "GenSigTimeoutMsg_IVI" SG_ 466 HuPDcOnDelayTimerAck 0;
BA_ "GenSigTimeoutTime_IVI" SG_ 466 HuPDcOnDelayTimerAck 0;
BA_ "GenSigTimeoutTime_HU_Mid_X451" SG_ 466 PDcFrontAudioMuteReq 0;
BA_ "GenSigTimeoutTime_HU_High_X451" SG_ 466 PDcFrontAudioMuteReq 0;
BA_ "GenSigTimeoutTime_HU_B" SG_ 466 PDcFrontAudioMuteReq 0;
BA_ "GenSigTimeoutTime_HU_A" SG_ 466 PDcFrontAudioMuteReq 0;
BA_ "GenSigTimeoutMsg_HU_Mid_X451" SG_ 466 PDcFrontAudioMuteReq 0;
BA_ "GenSigTimeoutMsg_HU_High_X451" SG_ 466 PDcFrontAudioMuteReq 0;
BA_ "GenSigTimeoutMsg_HU_B" SG_ 466 PDcFrontAudioMuteReq 0;
BA_ "GenSigTimeoutMsg_HU_A" SG_ 466 PDcFrontAudioMuteReq 0;
BA_ "GenSigSendType" SG_ 466 PDcFrontAudioMuteReq 1;
BA_ "GenSigTimeoutMsg_HU_High_X445" SG_ 466 PDcFrontAudioMuteReq 0;
BA_ "GenSigTimeoutMsg_HU_Mid_X445" SG_ 466 PDcFrontAudioMuteReq 0;
BA_ "GenSigTimeoutTime_HU_High_X445" SG_ 466 PDcFrontAudioMuteReq 0;
BA_ "GenSigTimeoutTime_HU_Mid_X445" SG_ 466 PDcFrontAudioMuteReq 0;
BA_ "GenSigTimeoutMsg_IVI" SG_ 466 PDcFrontAudioMuteReq 0;
BA_ "GenSigTimeoutTime_IVI" SG_ 466 PDcFrontAudioMuteReq 0;
BA_ "GenSigTimeoutTime_HU_Mid_X451" SG_ 466 HuPDcReqType 0;
BA_ "GenSigTimeoutTime_HU_High_X451" SG_ 466 HuPDcReqType 0;
BA_ "GenSigTimeoutTime_HU_B" SG_ 466 HuPDcReqType 0;
BA_ "GenSigTimeoutTime_HU_A" SG_ 466 HuPDcReqType 0;
BA_ "GenSigTimeoutMsg_HU_Mid_X451" SG_ 466 HuPDcReqType 0;
BA_ "GenSigTimeoutMsg_HU_High_X451" SG_ 466 HuPDcReqType 0;
BA_ "GenSigTimeoutMsg_HU_B" SG_ 466 HuPDcReqType 0;
BA_ "GenSigTimeoutMsg_HU_A" SG_ 466 HuPDcReqType 0;
BA_ "GenSigSendType" SG_ 466 HuPDcReqType 1;
BA_ "GenSigTimeoutMsg_HU_High_X445" SG_ 466 HuPDcReqType 0;
BA_ "GenSigTimeoutMsg_HU_Mid_X445" SG_ 466 HuPDcReqType 0;
BA_ "GenSigTimeoutTime_HU_High_X445" SG_ 466 HuPDcReqType 0;
BA_ "GenSigTimeoutTime_HU_Mid_X445" SG_ 466 HuPDcReqType 0;
BA_ "GenSigTimeoutMsg_IVI" SG_ 466 HuPDcReqType 0;
BA_ "GenSigTimeoutTime_IVI" SG_ 466 HuPDcReqType 0;
BA_ "GenSigTimeoutTime_HU_Mid_X451" SG_ 466 HuPDcRearToneAck 0;
BA_ "GenSigTimeoutTime_HU_High_X451" SG_ 466 HuPDcRearToneAck 0;
BA_ "GenSigTimeoutTime_HU_B" SG_ 466 HuPDcRearToneAck 0;
BA_ "GenSigTimeoutTime_HU_A" SG_ 466 HuPDcRearToneAck 0;
BA_ "GenSigTimeoutMsg_HU_Mid_X451" SG_ 466 HuPDcRearToneAck 0;
BA_ "GenSigTimeoutMsg_HU_High_X451" SG_ 466 HuPDcRearToneAck 0;
BA_ "GenSigTimeoutMsg_HU_B" SG_ 466 HuPDcRearToneAck 0;
BA_ "GenSigTimeoutMsg_HU_A" SG_ 466 HuPDcRearToneAck 0;
BA_ "GenSigSendType" SG_ 466 HuPDcRearToneAck 1;
BA_ "GenSigTimeoutMsg_HU_High_X445" SG_ 466 HuPDcRearToneAck 0;
BA_ "GenSigTimeoutMsg_HU_Mid_X445" SG_ 466 HuPDcRearToneAck 0;
BA_ "GenSigTimeoutTime_HU_High_X445" SG_ 466 HuPDcRearToneAck 0;
BA_ "GenSigTimeoutTime_HU_Mid_X445" SG_ 466 HuPDcRearToneAck 0;
BA_ "GenSigTimeoutMsg_IVI" SG_ 466 HuPDcRearToneAck 0;
BA_ "GenSigTimeoutTime_IVI" SG_ 466 HuPDcRearToneAck 0;
BA_ "GenSigTimeoutTime_HU_Mid_X451" SG_ 466 HuPDcFrontToneAck 0;
BA_ "GenSigTimeoutTime_HU_High_X451" SG_ 466 HuPDcFrontToneAck 0;
BA_ "GenSigTimeoutTime_HU_B" SG_ 466 HuPDcFrontToneAck 0;
BA_ "GenSigTimeoutTime_HU_A" SG_ 466 HuPDcFrontToneAck 0;
BA_ "GenSigTimeoutMsg_HU_Mid_X451" SG_ 466 HuPDcFrontToneAck 0;
BA_ "GenSigTimeoutMsg_HU_High_X451" SG_ 466 HuPDcFrontToneAck 0;
BA_ "GenSigTimeoutMsg_HU_B" SG_ 466 HuPDcFrontToneAck 0;
BA_ "GenSigTimeoutMsg_HU_A" SG_ 466 HuPDcFrontToneAck 0;
BA_ "GenSigSendType" SG_ 466 HuPDcFrontToneAck 1;
BA_ "GenSigTimeoutMsg_HU_High_X445" SG_ 466 HuPDcFrontToneAck 0;
BA_ "GenSigTimeoutMsg_HU_Mid_X445" SG_ 466 HuPDcFrontToneAck 0;
BA_ "GenSigTimeoutTime_HU_High_X445" SG_ 466 HuPDcFrontToneAck 0;
BA_ "GenSigTimeoutTime_HU_Mid_X445" SG_ 466 HuPDcFrontToneAck 0;
BA_ "GenSigTimeoutMsg_IVI" SG_ 466 HuPDcFrontToneAck 0;
BA_ "GenSigTimeoutTime_IVI" SG_ 466 HuPDcFrontToneAck 0;
BA_ "GenSigTimeoutTime_HU_Mid_X451" SG_ 466 HuPDcToneVolumeAck 0;
BA_ "GenSigTimeoutTime_HU_High_X451" SG_ 466 HuPDcToneVolumeAck 0;
BA_ "GenSigTimeoutTime_HU_B" SG_ 466 HuPDcToneVolumeAck 0;
BA_ "GenSigTimeoutTime_HU_A" SG_ 466 HuPDcToneVolumeAck 0;
BA_ "GenSigTimeoutMsg_HU_Mid_X451" SG_ 466 HuPDcToneVolumeAck 0;
BA_ "GenSigTimeoutMsg_HU_High_X451" SG_ 466 HuPDcToneVolumeAck 0;
BA_ "GenSigTimeoutMsg_HU_B" SG_ 466 HuPDcToneVolumeAck 0;
BA_ "GenSigTimeoutMsg_HU_A" SG_ 466 HuPDcToneVolumeAck 0;
BA_ "GenSigSendType" SG_ 466 HuPDcToneVolumeAck 1;
BA_ "GenSigTimeoutMsg_HU_High_X445" SG_ 466 HuPDcToneVolumeAck 0;
BA_ "GenSigTimeoutMsg_HU_Mid_X445" SG_ 466 HuPDcToneVolumeAck 0;
BA_ "GenSigTimeoutTime_HU_High_X445" SG_ 466 HuPDcToneVolumeAck 0;
BA_ "GenSigTimeoutTime_HU_Mid_X445" SG_ 466 HuPDcToneVolumeAck 0;
BA_ "GenSigTimeoutMsg_IVI" SG_ 466 HuPDcToneVolumeAck 0;
BA_ "GenSigTimeoutTime_IVI" SG_ 466 HuPDcToneVolumeAck 0;
BA_ "GenSigTimeoutTime_HU_Mid_X451" SG_ 466 HuPDcFrontNoOfSensAck 0;
BA_ "GenSigTimeoutTime_HU_High_X451" SG_ 466 HuPDcFrontNoOfSensAck 0;
BA_ "GenSigTimeoutTime_HU_B" SG_ 466 HuPDcFrontNoOfSensAck 0;
BA_ "GenSigTimeoutTime_HU_A" SG_ 466 HuPDcFrontNoOfSensAck 0;
BA_ "GenSigTimeoutMsg_HU_Mid_X451" SG_ 466 HuPDcFrontNoOfSensAck 0;
BA_ "GenSigTimeoutMsg_HU_High_X451" SG_ 466 HuPDcFrontNoOfSensAck 0;
BA_ "GenSigTimeoutMsg_HU_B" SG_ 466 HuPDcFrontNoOfSensAck 0;
BA_ "GenSigTimeoutMsg_HU_A" SG_ 466 HuPDcFrontNoOfSensAck 0;
BA_ "GenSigSendType" SG_ 466 HuPDcFrontNoOfSensAck 1;
BA_ "GenSigTimeoutMsg_HU_High_X445" SG_ 466 HuPDcFrontNoOfSensAck 0;
BA_ "GenSigTimeoutMsg_HU_Mid_X445" SG_ 466 HuPDcFrontNoOfSensAck 0;
BA_ "GenSigTimeoutTime_HU_High_X445" SG_ 466 HuPDcFrontNoOfSensAck 0;
BA_ "GenSigTimeoutTime_HU_Mid_X445" SG_ 466 HuPDcFrontNoOfSensAck 0;
BA_ "GenSigTimeoutMsg_IVI" SG_ 466 HuPDcFrontNoOfSensAck 0;
BA_ "GenSigTimeoutTime_IVI" SG_ 466 HuPDcFrontNoOfSensAck 0;
BA_ "GenSigTimeoutTime_HU_Mid_X451" SG_ 466 PDcFrontToneReq 0;
BA_ "GenSigTimeoutTime_HU_High_X451" SG_ 466 PDcFrontToneReq 0;
BA_ "GenSigTimeoutTime_HU_B" SG_ 466 PDcFrontToneReq 0;
BA_ "GenSigTimeoutTime_HU_A" SG_ 466 PDcFrontToneReq 0;
BA_ "GenSigTimeoutMsg_HU_Mid_X451" SG_ 466 PDcFrontToneReq 0;
BA_ "GenSigTimeoutMsg_HU_High_X451" SG_ 466 PDcFrontToneReq 0;
BA_ "GenSigTimeoutMsg_HU_B" SG_ 466 PDcFrontToneReq 0;
BA_ "GenSigTimeoutMsg_HU_A" SG_ 466 PDcFrontToneReq 0;
BA_ "GenSigSendType" SG_ 466 PDcFrontToneReq 1;
BA_ "GenSigTimeoutMsg_HU_High_X445" SG_ 466 PDcFrontToneReq 0;
BA_ "GenSigTimeoutMsg_HU_Mid_X445" SG_ 466 PDcFrontToneReq 0;
BA_ "GenSigTimeoutTime_HU_High_X445" SG_ 466 PDcFrontToneReq 0;
BA_ "GenSigTimeoutTime_HU_Mid_X445" SG_ 466 PDcFrontToneReq 0;
BA_ "GenSigTimeoutMsg_IVI" SG_ 466 PDcFrontToneReq 0;
BA_ "GenSigTimeoutTime_IVI" SG_ 466 PDcFrontToneReq 0;
BA_ "GenSigTimeoutTime_HU_Mid_X451" SG_ 466 HuPDCFrontActivationStateAck 0;
BA_ "GenSigTimeoutTime_HU_High_X451" SG_ 466 HuPDCFrontActivationStateAck 0;
BA_ "GenSigTimeoutTime_HU_B" SG_ 466 HuPDCFrontActivationStateAck 0;
BA_ "GenSigTimeoutTime_HU_A" SG_ 466 HuPDCFrontActivationStateAck 0;
BA_ "GenSigTimeoutMsg_HU_Mid_X451" SG_ 466 HuPDCFrontActivationStateAck 0;
BA_ "GenSigTimeoutMsg_HU_High_X451" SG_ 466 HuPDCFrontActivationStateAck 0;
BA_ "GenSigTimeoutMsg_HU_B" SG_ 466 HuPDCFrontActivationStateAck 0;
BA_ "GenSigTimeoutMsg_HU_A" SG_ 466 HuPDCFrontActivationStateAck 0;
BA_ "GenSigSendType" SG_ 466 HuPDCFrontActivationStateAck 1;
BA_ "GenSigTimeoutMsg_HU_High_X445" SG_ 466 HuPDCFrontActivationStateAck 0;
BA_ "GenSigTimeoutMsg_HU_Mid_X445" SG_ 466 HuPDCFrontActivationStateAck 0;
BA_ "GenSigTimeoutTime_HU_High_X445" SG_ 466 HuPDCFrontActivationStateAck 0;
BA_ "GenSigTimeoutTime_HU_Mid_X445" SG_ 466 HuPDCFrontActivationStateAck 0;
BA_ "GenSigTimeoutMsg_IVI" SG_ 466 HuPDCFrontActivationStateAck 0;
BA_ "GenSigTimeoutTime_IVI" SG_ 466 HuPDCFrontActivationStateAck 0;
BA_ "GenSigTimeoutTime_HU_Mid_X451" SG_ 466 PDcFrontActivationStateReq 0;
BA_ "GenSigTimeoutTime_HU_High_X451" SG_ 466 PDcFrontActivationStateReq 0;
BA_ "GenSigTimeoutTime_HU_B" SG_ 466 PDcFrontActivationStateReq 0;
BA_ "GenSigTimeoutTime_HU_A" SG_ 466 PDcFrontActivationStateReq 0;
BA_ "GenSigTimeoutMsg_HU_Mid_X451" SG_ 466 PDcFrontActivationStateReq 0;
BA_ "GenSigTimeoutMsg_HU_High_X451" SG_ 466 PDcFrontActivationStateReq 0;
BA_ "GenSigTimeoutMsg_HU_B" SG_ 466 PDcFrontActivationStateReq 0;
BA_ "GenSigTimeoutMsg_HU_A" SG_ 466 PDcFrontActivationStateReq 0;
BA_ "GenSigSendType" SG_ 466 PDcFrontActivationStateReq 1;
BA_ "GenSigTimeoutMsg_HU_High_X445" SG_ 466 PDcFrontActivationStateReq 0;
BA_ "GenSigTimeoutMsg_HU_Mid_X445" SG_ 466 PDcFrontActivationStateReq 0;
BA_ "GenSigTimeoutTime_HU_High_X445" SG_ 466 PDcFrontActivationStateReq 0;
BA_ "GenSigTimeoutTime_HU_Mid_X445" SG_ 466 PDcFrontActivationStateReq 0;
BA_ "GenSigTimeoutMsg_IVI" SG_ 466 PDcFrontActivationStateReq 0;
BA_ "GenSigTimeoutTime_IVI" SG_ 466 PDcFrontActivationStateReq 0;
BA_ "GenSigTimeoutTime_HU_Mid_X451" SG_ 466 HuPDCLowSpeedActivationAck 0;
BA_ "GenSigTimeoutTime_HU_High_X451" SG_ 466 HuPDCLowSpeedActivationAck 0;
BA_ "GenSigTimeoutTime_HU_B" SG_ 466 HuPDCLowSpeedActivationAck 0;
BA_ "GenSigTimeoutTime_HU_A" SG_ 466 HuPDCLowSpeedActivationAck 0;
BA_ "GenSigTimeoutMsg_HU_Mid_X451" SG_ 466 HuPDCLowSpeedActivationAck 0;
BA_ "GenSigTimeoutMsg_HU_High_X451" SG_ 466 HuPDCLowSpeedActivationAck 0;
BA_ "GenSigTimeoutMsg_HU_B" SG_ 466 HuPDCLowSpeedActivationAck 0;
BA_ "GenSigTimeoutMsg_HU_A" SG_ 466 HuPDCLowSpeedActivationAck 0;
BA_ "GenSigSendType" SG_ 466 HuPDCLowSpeedActivationAck 1;
BA_ "GenSigTimeoutMsg_HU_High_X445" SG_ 466 HuPDCLowSpeedActivationAck 0;
BA_ "GenSigTimeoutMsg_HU_Mid_X445" SG_ 466 HuPDCLowSpeedActivationAck 0;
BA_ "GenSigTimeoutTime_HU_High_X445" SG_ 466 HuPDCLowSpeedActivationAck 0;
BA_ "GenSigTimeoutTime_HU_Mid_X445" SG_ 466 HuPDCLowSpeedActivationAck 0;
BA_ "GenSigTimeoutMsg_IVI" SG_ 466 HuPDCLowSpeedActivationAck 0;
BA_ "GenSigTimeoutTime_IVI" SG_ 466 HuPDCLowSpeedActivationAck 0;
BA_ "GenSigTimeoutTime_HU_Mid_X451" SG_ 466 RVcOverlayTypeAck 0;
BA_ "GenSigTimeoutTime_HU_High_X451" SG_ 466 RVcOverlayTypeAck 0;
BA_ "GenSigTimeoutTime_HU_B" SG_ 466 RVcOverlayTypeAck 0;
BA_ "GenSigTimeoutTime_HU_A" SG_ 466 RVcOverlayTypeAck 0;
BA_ "GenSigTimeoutMsg_HU_Mid_X451" SG_ 466 RVcOverlayTypeAck 0;
BA_ "GenSigTimeoutMsg_HU_High_X451" SG_ 466 RVcOverlayTypeAck 0;
BA_ "GenSigTimeoutMsg_HU_B" SG_ 466 RVcOverlayTypeAck 0;
BA_ "GenSigTimeoutMsg_HU_A" SG_ 466 RVcOverlayTypeAck 0;
BA_ "GenSigSendType" SG_ 466 RVcOverlayTypeAck 1;
BA_ "GenSigTimeoutMsg_HU_High_X445" SG_ 466 RVcOverlayTypeAck 0;
BA_ "GenSigTimeoutMsg_HU_Mid_X445" SG_ 466 RVcOverlayTypeAck 0;
BA_ "GenSigTimeoutTime_HU_High_X445" SG_ 466 RVcOverlayTypeAck 0;
BA_ "GenSigTimeoutTime_HU_Mid_X445" SG_ 466 RVcOverlayTypeAck 0;
BA_ "GenSigTimeoutMsg_IVI" SG_ 466 RVcOverlayTypeAck 0;
BA_ "GenSigTimeoutTime_IVI" SG_ 466 RVcOverlayTypeAck 0;
BA_ "GenSigTimeoutTime_HU_Mid_X451" SG_ 466 RVcImageRotationTypeAck 0;
BA_ "GenSigTimeoutTime_HU_High_X451" SG_ 466 RVcImageRotationTypeAck 0;
BA_ "GenSigTimeoutTime_HU_B" SG_ 466 RVcImageRotationTypeAck 0;
BA_ "GenSigTimeoutTime_HU_A" SG_ 466 RVcImageRotationTypeAck 0;
BA_ "GenSigTimeoutMsg_HU_Mid_X451" SG_ 466 RVcImageRotationTypeAck 0;
BA_ "GenSigTimeoutMsg_HU_High_X451" SG_ 466 RVcImageRotationTypeAck 0;
BA_ "GenSigTimeoutMsg_HU_B" SG_ 466 RVcImageRotationTypeAck 0;
BA_ "GenSigTimeoutMsg_HU_A" SG_ 466 RVcImageRotationTypeAck 0;
BA_ "GenSigSendType" SG_ 466 RVcImageRotationTypeAck 1;
BA_ "GenSigTimeoutMsg_HU_High_X445" SG_ 466 RVcImageRotationTypeAck 0;
BA_ "GenSigTimeoutMsg_HU_Mid_X445" SG_ 466 RVcImageRotationTypeAck 0;
BA_ "GenSigTimeoutTime_HU_High_X445" SG_ 466 RVcImageRotationTypeAck 0;
BA_ "GenSigTimeoutTime_HU_Mid_X445" SG_ 466 RVcImageRotationTypeAck 0;
BA_ "GenSigTimeoutMsg_IVI" SG_ 466 RVcImageRotationTypeAck 0;
BA_ "GenSigTimeoutTime_IVI" SG_ 466 RVcImageRotationTypeAck 0;
BA_ "GenSigTimeoutTime_HU_Mid_X451" SG_ 469 HuIcTempUnitSet 0;
BA_ "GenSigTimeoutTime_HU_High_X451" SG_ 469 HuIcTempUnitSet 0;
BA_ "GenSigTimeoutTime_HU_B" SG_ 469 HuIcTempUnitSet 0;
BA_ "GenSigTimeoutTime_HU_A" SG_ 469 HuIcTempUnitSet 0;
BA_ "GenSigTimeoutMsg_HU_Mid_X451" SG_ 469 HuIcTempUnitSet 0;
BA_ "GenSigTimeoutMsg_HU_High_X451" SG_ 469 HuIcTempUnitSet 0;
BA_ "GenSigTimeoutMsg_HU_B" SG_ 469 HuIcTempUnitSet 0;
BA_ "GenSigTimeoutMsg_HU_A" SG_ 469 HuIcTempUnitSet 0;
BA_ "GenSigSendType" SG_ 469 HuIcTempUnitSet 1;
BA_ "GenSigTimeoutMsg_HU_High_X445" SG_ 469 HuIcTempUnitSet 0;
BA_ "GenSigTimeoutMsg_HU_Mid_X445" SG_ 469 HuIcTempUnitSet 0;
BA_ "GenSigTimeoutTime_HU_High_X445" SG_ 469 HuIcTempUnitSet 0;
BA_ "GenSigTimeoutTime_HU_Mid_X445" SG_ 469 HuIcTempUnitSet 0;
BA_ "GenSigTimeoutMsg_IVI" SG_ 469 HuIcTempUnitSet 0;
BA_ "GenSigTimeoutTime_IVI" SG_ 469 HuIcTempUnitSet 0;
BA_ "GenSigTimeoutTime_HU_Mid_X451" SG_ 469 HuIcDistUnitSet 0;
BA_ "GenSigTimeoutTime_HU_High_X451" SG_ 469 HuIcDistUnitSet 0;
BA_ "GenSigTimeoutTime_HU_B" SG_ 469 HuIcDistUnitSet 0;
BA_ "GenSigTimeoutTime_HU_A" SG_ 469 HuIcDistUnitSet 0;
BA_ "GenSigTimeoutMsg_HU_Mid_X451" SG_ 469 HuIcDistUnitSet 0;
BA_ "GenSigTimeoutMsg_HU_High_X451" SG_ 469 HuIcDistUnitSet 0;
BA_ "GenSigTimeoutMsg_HU_B" SG_ 469 HuIcDistUnitSet 0;
BA_ "GenSigTimeoutMsg_HU_A" SG_ 469 HuIcDistUnitSet 0;
BA_ "GenSigSendType" SG_ 469 HuIcDistUnitSet 1;
BA_ "GenSigTimeoutMsg_HU_High_X445" SG_ 469 HuIcDistUnitSet 0;
BA_ "GenSigTimeoutMsg_HU_Mid_X445" SG_ 469 HuIcDistUnitSet 0;
BA_ "GenSigTimeoutTime_HU_High_X445" SG_ 469 HuIcDistUnitSet 0;
BA_ "GenSigTimeoutTime_HU_Mid_X445" SG_ 469 HuIcDistUnitSet 0;
BA_ "GenSigTimeoutMsg_IVI" SG_ 469 HuIcDistUnitSet 0;
BA_ "GenSigTimeoutTime_IVI" SG_ 469 HuIcDistUnitSet 0;
BA_ "GenSigTimeoutTime_HU_Mid_X451" SG_ 469 HuIcSecondsInfo 0;
BA_ "GenSigTimeoutTime_HU_High_X451" SG_ 469 HuIcSecondsInfo 0;
BA_ "GenSigTimeoutTime_HU_B" SG_ 469 HuIcSecondsInfo 0;
BA_ "GenSigTimeoutTime_HU_A" SG_ 469 HuIcSecondsInfo 0;
BA_ "GenSigTimeoutMsg_HU_Mid_X451" SG_ 469 HuIcSecondsInfo 0;
BA_ "GenSigTimeoutMsg_HU_High_X451" SG_ 469 HuIcSecondsInfo 0;
BA_ "GenSigTimeoutMsg_HU_B" SG_ 469 HuIcSecondsInfo 0;
BA_ "GenSigTimeoutMsg_HU_A" SG_ 469 HuIcSecondsInfo 0;
BA_ "GenSigSendType" SG_ 469 HuIcSecondsInfo 1;
BA_ "GenSigTimeoutMsg_HU_High_X445" SG_ 469 HuIcSecondsInfo 0;
BA_ "GenSigTimeoutMsg_HU_Mid_X445" SG_ 469 HuIcSecondsInfo 0;
BA_ "GenSigTimeoutTime_HU_High_X445" SG_ 469 HuIcSecondsInfo 0;
BA_ "GenSigTimeoutTime_HU_Mid_X445" SG_ 469 HuIcSecondsInfo 0;
BA_ "GenSigTimeoutMsg_IVI" SG_ 469 HuIcSecondsInfo 0;
BA_ "GenSigTimeoutTime_IVI" SG_ 469 HuIcSecondsInfo 0;
BA_ "GenSigTimeoutTime_HU_Mid_X451" SG_ 469 HuIcFuelUnitSet 0;
BA_ "GenSigTimeoutTime_HU_High_X451" SG_ 469 HuIcFuelUnitSet 0;
BA_ "GenSigTimeoutTime_HU_B" SG_ 469 HuIcFuelUnitSet 0;
BA_ "GenSigTimeoutTime_HU_A" SG_ 469 HuIcFuelUnitSet 0;
BA_ "GenSigTimeoutMsg_HU_Mid_X451" SG_ 469 HuIcFuelUnitSet 0;
BA_ "GenSigTimeoutMsg_HU_High_X451" SG_ 469 HuIcFuelUnitSet 0;
BA_ "GenSigTimeoutMsg_HU_B" SG_ 469 HuIcFuelUnitSet 0;
BA_ "GenSigTimeoutMsg_HU_A" SG_ 469 HuIcFuelUnitSet 0;
BA_ "GenSigSendType" SG_ 469 HuIcFuelUnitSet 1;
BA_ "GenSigTimeoutMsg_HU_High_X445" SG_ 469 HuIcFuelUnitSet 0;
BA_ "GenSigTimeoutMsg_HU_Mid_X445" SG_ 469 HuIcFuelUnitSet 0;
BA_ "GenSigTimeoutTime_HU_High_X445" SG_ 469 HuIcFuelUnitSet 0;
BA_ "GenSigTimeoutTime_HU_Mid_X445" SG_ 469 HuIcFuelUnitSet 0;
BA_ "GenSigTimeoutMsg_IVI" SG_ 469 HuIcFuelUnitSet 0;
BA_ "GenSigTimeoutTime_IVI" SG_ 469 HuIcFuelUnitSet 0;
BA_ "GenSigTimeoutTime_HU_Mid_X451" SG_ 469 HuIcMinuteInfo 0;
BA_ "GenSigTimeoutTime_HU_High_X451" SG_ 469 HuIcMinuteInfo 0;
BA_ "GenSigTimeoutTime_HU_B" SG_ 469 HuIcMinuteInfo 0;
BA_ "GenSigTimeoutTime_HU_A" SG_ 469 HuIcMinuteInfo 0;
BA_ "GenSigTimeoutMsg_HU_Mid_X451" SG_ 469 HuIcMinuteInfo 0;
BA_ "GenSigTimeoutMsg_HU_High_X451" SG_ 469 HuIcMinuteInfo 0;
BA_ "GenSigTimeoutMsg_HU_B" SG_ 469 HuIcMinuteInfo 0;
BA_ "GenSigTimeoutMsg_HU_A" SG_ 469 HuIcMinuteInfo 0;
BA_ "GenSigSendType" SG_ 469 HuIcMinuteInfo 1;
BA_ "GenSigTimeoutMsg_HU_High_X445" SG_ 469 HuIcMinuteInfo 0;
BA_ "GenSigTimeoutMsg_HU_Mid_X445" SG_ 469 HuIcMinuteInfo 0;
BA_ "GenSigTimeoutTime_HU_High_X445" SG_ 469 HuIcMinuteInfo 0;
BA_ "GenSigTimeoutTime_HU_Mid_X445" SG_ 469 HuIcMinuteInfo 0;
BA_ "GenSigTimeoutMsg_IVI" SG_ 469 HuIcMinuteInfo 0;
BA_ "GenSigTimeoutTime_IVI" SG_ 469 HuIcMinuteInfo 0;
BA_ "GenSigTimeoutTime_HU_Mid_X451" SG_ 469 HuIcClockMode 0;
BA_ "GenSigTimeoutTime_HU_High_X451" SG_ 469 HuIcClockMode 0;
BA_ "GenSigTimeoutTime_HU_B" SG_ 469 HuIcClockMode 0;
BA_ "GenSigTimeoutTime_HU_A" SG_ 469 HuIcClockMode 0;
BA_ "GenSigTimeoutMsg_HU_Mid_X451" SG_ 469 HuIcClockMode 0;
BA_ "GenSigTimeoutMsg_HU_High_X451" SG_ 469 HuIcClockMode 0;
BA_ "GenSigTimeoutMsg_HU_B" SG_ 469 HuIcClockMode 0;
BA_ "GenSigTimeoutMsg_HU_A" SG_ 469 HuIcClockMode 0;
BA_ "GenSigSendType" SG_ 469 HuIcClockMode 1;
BA_ "GenSigTimeoutMsg_HU_High_X445" SG_ 469 HuIcClockMode 0;
BA_ "GenSigTimeoutMsg_HU_Mid_X445" SG_ 469 HuIcClockMode 0;
BA_ "GenSigTimeoutTime_HU_High_X445" SG_ 469 HuIcClockMode 0;
BA_ "GenSigTimeoutTime_HU_Mid_X445" SG_ 469 HuIcClockMode 0;
BA_ "GenSigTimeoutMsg_IVI" SG_ 469 HuIcClockMode 0;
BA_ "GenSigTimeoutTime_IVI" SG_ 469 HuIcClockMode 0;
BA_ "GenSigTimeoutTime_HU_Mid_X451" SG_ 469 QueryIcHuUnitSetInfo 0;
BA_ "GenSigTimeoutTime_HU_High_X451" SG_ 469 QueryIcHuUnitSetInfo 0;
BA_ "GenSigTimeoutTime_HU_B" SG_ 469 QueryIcHuUnitSetInfo 0;
BA_ "GenSigTimeoutTime_HU_A" SG_ 469 QueryIcHuUnitSetInfo 0;
BA_ "GenSigTimeoutMsg_HU_Mid_X451" SG_ 469 QueryIcHuUnitSetInfo 0;
BA_ "GenSigTimeoutMsg_HU_High_X451" SG_ 469 QueryIcHuUnitSetInfo 0;
BA_ "GenSigTimeoutMsg_HU_B" SG_ 469 QueryIcHuUnitSetInfo 0;
BA_ "GenSigTimeoutMsg_HU_A" SG_ 469 QueryIcHuUnitSetInfo 0;
BA_ "GenSigSendType" SG_ 469 QueryIcHuUnitSetInfo 1;
BA_ "GenSigTimeoutMsg_HU_High_X445" SG_ 469 QueryIcHuUnitSetInfo 0;
BA_ "GenSigTimeoutMsg_HU_Mid_X445" SG_ 469 QueryIcHuUnitSetInfo 0;
BA_ "GenSigTimeoutTime_HU_High_X445" SG_ 469 QueryIcHuUnitSetInfo 0;
BA_ "GenSigTimeoutTime_HU_Mid_X445" SG_ 469 QueryIcHuUnitSetInfo 0;
BA_ "GenSigTimeoutMsg_IVI" SG_ 469 QueryIcHuUnitSetInfo 0;
BA_ "GenSigTimeoutTime_IVI" SG_ 469 QueryIcHuUnitSetInfo 0;
BA_ "GenSigTimeoutTime_HU_Mid_X451" SG_ 469 HuIcRtcTypeNew 0;
BA_ "GenSigTimeoutTime_HU_High_X451" SG_ 469 HuIcRtcTypeNew 0;
BA_ "GenSigTimeoutTime_HU_B" SG_ 469 HuIcRtcTypeNew 0;
BA_ "GenSigTimeoutTime_HU_A" SG_ 469 HuIcRtcTypeNew 0;
BA_ "GenSigTimeoutMsg_HU_Mid_X451" SG_ 469 HuIcRtcTypeNew 0;
BA_ "GenSigTimeoutMsg_HU_High_X451" SG_ 469 HuIcRtcTypeNew 0;
BA_ "GenSigTimeoutMsg_HU_B" SG_ 469 HuIcRtcTypeNew 0;
BA_ "GenSigTimeoutMsg_HU_A" SG_ 469 HuIcRtcTypeNew 0;
BA_ "GenSigSendType" SG_ 469 HuIcRtcTypeNew 1;
BA_ "GenSigTimeoutMsg_HU_High_X445" SG_ 469 HuIcRtcTypeNew 0;
BA_ "GenSigTimeoutMsg_HU_Mid_X445" SG_ 469 HuIcRtcTypeNew 0;
BA_ "GenSigTimeoutTime_HU_High_X445" SG_ 469 HuIcRtcTypeNew 0;
BA_ "GenSigTimeoutTime_HU_Mid_X445" SG_ 469 HuIcRtcTypeNew 0;
BA_ "GenSigTimeoutMsg_IVI" SG_ 469 HuIcRtcTypeNew 0;
BA_ "GenSigTimeoutTime_IVI" SG_ 469 HuIcRtcTypeNew 0;
BA_ "GenSigTimeoutTime_HU_Mid_X451" SG_ 469 HuIcHourInfo 0;
BA_ "GenSigTimeoutTime_HU_High_X451" SG_ 469 HuIcHourInfo 0;
BA_ "GenSigTimeoutTime_HU_B" SG_ 469 HuIcHourInfo 0;
BA_ "GenSigTimeoutTime_HU_A" SG_ 469 HuIcHourInfo 0;
BA_ "GenSigTimeoutMsg_HU_Mid_X451" SG_ 469 HuIcHourInfo 0;
BA_ "GenSigTimeoutMsg_HU_High_X451" SG_ 469 HuIcHourInfo 0;
BA_ "GenSigTimeoutMsg_HU_B" SG_ 469 HuIcHourInfo 0;
BA_ "GenSigTimeoutMsg_HU_A" SG_ 469 HuIcHourInfo 0;
BA_ "GenSigSendType" SG_ 469 HuIcHourInfo 1;
BA_ "GenSigTimeoutMsg_HU_High_X445" SG_ 469 HuIcHourInfo 0;
BA_ "GenSigTimeoutMsg_HU_Mid_X445" SG_ 469 HuIcHourInfo 0;
BA_ "GenSigTimeoutTime_HU_High_X445" SG_ 469 HuIcHourInfo 0;
BA_ "GenSigTimeoutTime_HU_Mid_X445" SG_ 469 HuIcHourInfo 0;
BA_ "GenSigTimeoutMsg_IVI" SG_ 469 HuIcHourInfo 0;
BA_ "GenSigTimeoutTime_IVI" SG_ 469 HuIcHourInfo 0;
BA_ "GenSigTimeoutTime_HU_Mid_X451" SG_ 469 HuIcDateInfo 0;
BA_ "GenSigTimeoutTime_HU_High_X451" SG_ 469 HuIcDateInfo 0;
BA_ "GenSigTimeoutTime_HU_B" SG_ 469 HuIcDateInfo 0;
BA_ "GenSigTimeoutTime_HU_A" SG_ 469 HuIcDateInfo 0;
BA_ "GenSigTimeoutMsg_HU_Mid_X451" SG_ 469 HuIcDateInfo 0;
BA_ "GenSigTimeoutMsg_HU_High_X451" SG_ 469 HuIcDateInfo 0;
BA_ "GenSigTimeoutMsg_HU_B" SG_ 469 HuIcDateInfo 0;
BA_ "GenSigTimeoutMsg_HU_A" SG_ 469 HuIcDateInfo 0;
BA_ "GenSigSendType" SG_ 469 HuIcDateInfo 1;
BA_ "GenSigTimeoutMsg_HU_High_X445" SG_ 469 HuIcDateInfo 0;
BA_ "GenSigTimeoutMsg_HU_Mid_X445" SG_ 469 HuIcDateInfo 0;
BA_ "GenSigTimeoutTime_HU_High_X445" SG_ 469 HuIcDateInfo 0;
BA_ "GenSigTimeoutTime_HU_Mid_X445" SG_ 469 HuIcDateInfo 0;
BA_ "GenSigTimeoutMsg_IVI" SG_ 469 HuIcDateInfo 0;
BA_ "GenSigTimeoutTime_IVI" SG_ 469 HuIcDateInfo 0;
BA_ "GenSigTimeoutTime_HU_Mid_X451" SG_ 469 HuIcYearInfo 0;
BA_ "GenSigTimeoutTime_HU_High_X451" SG_ 469 HuIcYearInfo 0;
BA_ "GenSigTimeoutTime_HU_B" SG_ 469 HuIcYearInfo 0;
BA_ "GenSigTimeoutTime_HU_A" SG_ 469 HuIcYearInfo 0;
BA_ "GenSigTimeoutMsg_HU_Mid_X451" SG_ 469 HuIcYearInfo 0;
BA_ "GenSigTimeoutMsg_HU_High_X451" SG_ 469 HuIcYearInfo 0;
BA_ "GenSigTimeoutMsg_HU_B" SG_ 469 HuIcYearInfo 0;
BA_ "GenSigTimeoutMsg_HU_A" SG_ 469 HuIcYearInfo 0;
BA_ "GenSigSendType" SG_ 469 HuIcYearInfo 1;
BA_ "GenSigTimeoutMsg_HU_High_X445" SG_ 469 HuIcYearInfo 0;
BA_ "GenSigTimeoutMsg_HU_Mid_X445" SG_ 469 HuIcYearInfo 0;
BA_ "GenSigTimeoutTime_HU_High_X445" SG_ 469 HuIcYearInfo 0;
BA_ "GenSigTimeoutTime_HU_Mid_X445" SG_ 469 HuIcYearInfo 0;
BA_ "GenSigTimeoutMsg_IVI" SG_ 469 HuIcYearInfo 0;
BA_ "GenSigTimeoutTime_IVI" SG_ 469 HuIcYearInfo 0;
BA_ "GenSigTimeoutTime_HU_Mid_X451" SG_ 469 HuIcMonthInfo 0;
BA_ "GenSigTimeoutTime_HU_High_X451" SG_ 469 HuIcMonthInfo 0;
BA_ "GenSigTimeoutTime_HU_B" SG_ 469 HuIcMonthInfo 0;
BA_ "GenSigTimeoutTime_HU_A" SG_ 469 HuIcMonthInfo 0;
BA_ "GenSigTimeoutMsg_HU_Mid_X451" SG_ 469 HuIcMonthInfo 0;
BA_ "GenSigTimeoutMsg_HU_High_X451" SG_ 469 HuIcMonthInfo 0;
BA_ "GenSigTimeoutMsg_HU_B" SG_ 469 HuIcMonthInfo 0;
BA_ "GenSigTimeoutMsg_HU_A" SG_ 469 HuIcMonthInfo 0;
BA_ "GenSigSendType" SG_ 469 HuIcMonthInfo 1;
BA_ "GenSigTimeoutMsg_HU_High_X445" SG_ 469 HuIcMonthInfo 0;
BA_ "GenSigTimeoutMsg_HU_Mid_X445" SG_ 469 HuIcMonthInfo 0;
BA_ "GenSigTimeoutTime_HU_High_X445" SG_ 469 HuIcMonthInfo 0;
BA_ "GenSigTimeoutTime_HU_Mid_X445" SG_ 469 HuIcMonthInfo 0;
BA_ "GenSigTimeoutMsg_IVI" SG_ 469 HuIcMonthInfo 0;
BA_ "GenSigTimeoutTime_IVI" SG_ 469 HuIcMonthInfo 0;
BA_ "GenSigTimeoutTime_HU_Mid_X451" SG_ 469 HuIcMilliSecondInfo 0;
BA_ "GenSigTimeoutTime_HU_High_X451" SG_ 469 HuIcMilliSecondInfo 0;
BA_ "GenSigTimeoutTime_HU_B" SG_ 469 HuIcMilliSecondInfo 0;
BA_ "GenSigTimeoutTime_HU_A" SG_ 469 HuIcMilliSecondInfo 0;
BA_ "GenSigTimeoutMsg_HU_Mid_X451" SG_ 469 HuIcMilliSecondInfo 0;
BA_ "GenSigTimeoutMsg_HU_High_X451" SG_ 469 HuIcMilliSecondInfo 0;
BA_ "GenSigTimeoutMsg_HU_B" SG_ 469 HuIcMilliSecondInfo 0;
BA_ "GenSigTimeoutMsg_HU_A" SG_ 469 HuIcMilliSecondInfo 0;
BA_ "GenSigSendType" SG_ 469 HuIcMilliSecondInfo 1;
BA_ "GenSigTimeoutMsg_HU_High_X445" SG_ 469 HuIcMilliSecondInfo 0;
BA_ "GenSigTimeoutMsg_HU_Mid_X445" SG_ 469 HuIcMilliSecondInfo 0;
BA_ "GenSigTimeoutTime_HU_High_X445" SG_ 469 HuIcMilliSecondInfo 0;
BA_ "GenSigTimeoutTime_HU_Mid_X445" SG_ 469 HuIcMilliSecondInfo 0;
BA_ "GenSigTimeoutMsg_IVI" SG_ 469 HuIcMilliSecondInfo 0;
BA_ "GenSigTimeoutTime_IVI" SG_ 469 HuIcMilliSecondInfo 0;
BA_ "GenSigTimeoutTime_HU_Mid_X451" SG_ 469 HuLangSettings 0;
BA_ "GenSigTimeoutTime_HU_High_X451" SG_ 469 HuLangSettings 0;
BA_ "GenSigTimeoutTime_HU_B" SG_ 469 HuLangSettings 0;
BA_ "GenSigTimeoutTime_HU_A" SG_ 469 HuLangSettings 0;
BA_ "GenSigTimeoutMsg_HU_Mid_X451" SG_ 469 HuLangSettings 0;
BA_ "GenSigTimeoutMsg_HU_High_X451" SG_ 469 HuLangSettings 0;
BA_ "GenSigTimeoutMsg_HU_B" SG_ 469 HuLangSettings 0;
BA_ "GenSigTimeoutMsg_HU_A" SG_ 469 HuLangSettings 0;
BA_ "GenSigSendType" SG_ 469 HuLangSettings 1;
BA_ "GenSigTimeoutMsg_HU_High_X445" SG_ 469 HuLangSettings 0;
BA_ "GenSigTimeoutMsg_HU_Mid_X445" SG_ 469 HuLangSettings 0;
BA_ "GenSigTimeoutTime_HU_High_X445" SG_ 469 HuLangSettings 0;
BA_ "GenSigTimeoutTime_HU_Mid_X445" SG_ 469 HuLangSettings 0;
BA_ "GenSigTimeoutMsg_IVI" SG_ 469 HuLangSettings 0;
BA_ "GenSigTimeoutTime_IVI" SG_ 469 HuLangSettings 0;
BA_ "GenSigTimeoutTime_HU_Mid_X451" SG_ 469 HuIcRtcType 0;
BA_ "GenSigTimeoutTime_HU_High_X451" SG_ 469 HuIcRtcType 0;
BA_ "GenSigTimeoutTime_HU_B" SG_ 469 HuIcRtcType 0;
BA_ "GenSigTimeoutTime_HU_A" SG_ 469 HuIcRtcType 0;
BA_ "GenSigTimeoutMsg_HU_Mid_X451" SG_ 469 HuIcRtcType 0;
BA_ "GenSigTimeoutMsg_HU_High_X451" SG_ 469 HuIcRtcType 0;
BA_ "GenSigTimeoutMsg_HU_B" SG_ 469 HuIcRtcType 0;
BA_ "GenSigTimeoutMsg_HU_A" SG_ 469 HuIcRtcType 0;
BA_ "GenSigSendType" SG_ 469 HuIcRtcType 1;
BA_ "GenSigTimeoutMsg_HU_High_X445" SG_ 469 HuIcRtcType 0;
BA_ "GenSigTimeoutMsg_HU_Mid_X445" SG_ 469 HuIcRtcType 0;
BA_ "GenSigTimeoutTime_HU_High_X445" SG_ 469 HuIcRtcType 0;
BA_ "GenSigTimeoutTime_HU_Mid_X445" SG_ 469 HuIcRtcType 0;
BA_ "GenSigTimeoutMsg_IVI" SG_ 469 HuIcRtcType 0;
BA_ "GenSigTimeoutTime_IVI" SG_ 469 HuIcRtcType 0;
BA_ "GenSigTimeoutTime_HU_Mid_X451" SG_ 470 HuIcTempUnitSetAck 0;
BA_ "GenSigTimeoutTime_HU_High_X451" SG_ 470 HuIcTempUnitSetAck 0;
BA_ "GenSigTimeoutTime_HU_B" SG_ 470 HuIcTempUnitSetAck 0;
BA_ "GenSigTimeoutTime_HU_A" SG_ 470 HuIcTempUnitSetAck 0;
BA_ "GenSigTimeoutMsg_HU_Mid_X451" SG_ 470 HuIcTempUnitSetAck 0;
BA_ "GenSigTimeoutMsg_HU_High_X451" SG_ 470 HuIcTempUnitSetAck 0;
BA_ "GenSigTimeoutMsg_HU_B" SG_ 470 HuIcTempUnitSetAck 0;
BA_ "GenSigTimeoutMsg_HU_A" SG_ 470 HuIcTempUnitSetAck 0;
BA_ "GenSigSendType" SG_ 470 HuIcTempUnitSetAck 1;
BA_ "GenSigTimeoutMsg_HU_High_X445" SG_ 470 HuIcTempUnitSetAck 0;
BA_ "GenSigTimeoutMsg_HU_Mid_X445" SG_ 470 HuIcTempUnitSetAck 0;
BA_ "GenSigTimeoutTime_HU_High_X445" SG_ 470 HuIcTempUnitSetAck 0;
BA_ "GenSigTimeoutTime_HU_Mid_X445" SG_ 470 HuIcTempUnitSetAck 0;
BA_ "GenSigTimeoutMsg_IVI" SG_ 470 HuIcTempUnitSetAck 0;
BA_ "GenSigTimeoutTime_IVI" SG_ 470 HuIcTempUnitSetAck 0;
BA_ "GenSigTimeoutTime_HU_Mid_X451" SG_ 470 HuIcFuelUnitSetAck 0;
BA_ "GenSigTimeoutTime_HU_High_X451" SG_ 470 HuIcFuelUnitSetAck 0;
BA_ "GenSigTimeoutTime_HU_B" SG_ 470 HuIcFuelUnitSetAck 0;
BA_ "GenSigTimeoutTime_HU_A" SG_ 470 HuIcFuelUnitSetAck 0;
BA_ "GenSigTimeoutMsg_HU_Mid_X451" SG_ 470 HuIcFuelUnitSetAck 0;
BA_ "GenSigTimeoutMsg_HU_High_X451" SG_ 470 HuIcFuelUnitSetAck 0;
BA_ "GenSigTimeoutMsg_HU_B" SG_ 470 HuIcFuelUnitSetAck 0;
BA_ "GenSigTimeoutMsg_HU_A" SG_ 470 HuIcFuelUnitSetAck 0;
BA_ "GenSigSendType" SG_ 470 HuIcFuelUnitSetAck 1;
BA_ "GenSigTimeoutMsg_HU_High_X445" SG_ 470 HuIcFuelUnitSetAck 0;
BA_ "GenSigTimeoutMsg_HU_Mid_X445" SG_ 470 HuIcFuelUnitSetAck 0;
BA_ "GenSigTimeoutTime_HU_High_X445" SG_ 470 HuIcFuelUnitSetAck 0;
BA_ "GenSigTimeoutTime_HU_Mid_X445" SG_ 470 HuIcFuelUnitSetAck 0;
BA_ "GenSigTimeoutMsg_IVI" SG_ 470 HuIcFuelUnitSetAck 0;
BA_ "GenSigTimeoutTime_IVI" SG_ 470 HuIcFuelUnitSetAck 0;
BA_ "GenSigTimeoutTime_HU_Mid_X451" SG_ 470 HuIcDistUnitSetAck 0;
BA_ "GenSigTimeoutTime_HU_High_X451" SG_ 470 HuIcDistUnitSetAck 0;
BA_ "GenSigTimeoutTime_HU_B" SG_ 470 HuIcDistUnitSetAck 0;
BA_ "GenSigTimeoutTime_HU_A" SG_ 470 HuIcDistUnitSetAck 0;
BA_ "GenSigTimeoutMsg_HU_Mid_X451" SG_ 470 HuIcDistUnitSetAck 0;
BA_ "GenSigTimeoutMsg_HU_High_X451" SG_ 470 HuIcDistUnitSetAck 0;
BA_ "GenSigTimeoutMsg_HU_B" SG_ 470 HuIcDistUnitSetAck 0;
BA_ "GenSigTimeoutMsg_HU_A" SG_ 470 HuIcDistUnitSetAck 0;
BA_ "GenSigSendType" SG_ 470 HuIcDistUnitSetAck 1;
BA_ "GenSigTimeoutMsg_HU_High_X445" SG_ 470 HuIcDistUnitSetAck 0;
BA_ "GenSigTimeoutMsg_HU_Mid_X445" SG_ 470 HuIcDistUnitSetAck 0;
BA_ "GenSigTimeoutTime_HU_High_X445" SG_ 470 HuIcDistUnitSetAck 0;
BA_ "GenSigTimeoutTime_HU_Mid_X445" SG_ 470 HuIcDistUnitSetAck 0;
BA_ "GenSigTimeoutMsg_IVI" SG_ 470 HuIcDistUnitSetAck 0;
BA_ "GenSigTimeoutTime_IVI" SG_ 470 HuIcDistUnitSetAck 0;
BA_ "GenSigTimeoutTime_HU_Mid_X451" SG_ 472 CcmHuRearBlwrConfig 0;
BA_ "GenSigTimeoutTime_HU_High_X451" SG_ 472 CcmHuRearBlwrConfig 0;
BA_ "GenSigTimeoutTime_HU_B" SG_ 472 CcmHuRearBlwrConfig 0;
BA_ "GenSigTimeoutTime_HU_A" SG_ 472 CcmHuRearBlwrConfig 0;
BA_ "GenSigTimeoutMsg_HU_Mid_X451" SG_ 472 CcmHuRearBlwrConfig 0;
BA_ "GenSigTimeoutMsg_HU_High_X451" SG_ 472 CcmHuRearBlwrConfig 0;
BA_ "GenSigTimeoutMsg_HU_B" SG_ 472 CcmHuRearBlwrConfig 0;
BA_ "GenSigTimeoutMsg_HU_A" SG_ 472 CcmHuRearBlwrConfig 0;
BA_ "GenSigSendType" SG_ 472 CcmHuRearBlwrConfig 1;
BA_ "GenSigTimeoutMsg_HU_High_X445" SG_ 472 CcmHuRearBlwrConfig 0;
BA_ "GenSigTimeoutMsg_HU_Mid_X445" SG_ 472 CcmHuRearBlwrConfig 0;
BA_ "GenSigTimeoutTime_HU_High_X445" SG_ 472 CcmHuRearBlwrConfig 0;
BA_ "GenSigTimeoutTime_HU_Mid_X445" SG_ 472 CcmHuRearBlwrConfig 0;
BA_ "GenSigTimeoutMsg_IVI" SG_ 472 CcmHuRearBlwrConfig 0;
BA_ "GenSigTimeoutTime_IVI" SG_ 472 CcmHuRearBlwrConfig 0;
BA_ "GenSigTimeoutTime_HU_Mid_X451" SG_ 472 CCmHuEconConfig 0;
BA_ "GenSigTimeoutTime_HU_High_X451" SG_ 472 CCmHuEconConfig 0;
BA_ "GenSigTimeoutTime_HU_B" SG_ 472 CCmHuEconConfig 0;
BA_ "GenSigTimeoutTime_HU_A" SG_ 472 CCmHuEconConfig 0;
BA_ "GenSigTimeoutMsg_HU_Mid_X451" SG_ 472 CCmHuEconConfig 0;
BA_ "GenSigTimeoutMsg_HU_High_X451" SG_ 472 CCmHuEconConfig 0;
BA_ "GenSigTimeoutMsg_HU_B" SG_ 472 CCmHuEconConfig 0;
BA_ "GenSigTimeoutMsg_HU_A" SG_ 472 CCmHuEconConfig 0;
BA_ "GenSigSendType" SG_ 472 CCmHuEconConfig 1;
BA_ "GenSigTimeoutMsg_HU_High_X445" SG_ 472 CCmHuEconConfig 0;
BA_ "GenSigTimeoutMsg_HU_Mid_X445" SG_ 472 CCmHuEconConfig 0;
BA_ "GenSigTimeoutTime_HU_High_X445" SG_ 472 CCmHuEconConfig 0;
BA_ "GenSigTimeoutTime_HU_Mid_X445" SG_ 472 CCmHuEconConfig 0;
BA_ "GenSigTimeoutMsg_IVI" SG_ 472 CCmHuEconConfig 0;
BA_ "GenSigTimeoutTime_IVI" SG_ 472 CCmHuEconConfig 0;
BA_ "GenSigTimeoutTime_HU_Mid_X451" SG_ 472 CCmHuExpressCoolConfig 0;
BA_ "GenSigTimeoutTime_HU_High_X451" SG_ 472 CCmHuExpressCoolConfig 0;
BA_ "GenSigTimeoutTime_HU_B" SG_ 472 CCmHuExpressCoolConfig 0;
BA_ "GenSigTimeoutTime_HU_A" SG_ 472 CCmHuExpressCoolConfig 0;
BA_ "GenSigTimeoutMsg_HU_Mid_X451" SG_ 472 CCmHuExpressCoolConfig 0;
BA_ "GenSigTimeoutMsg_HU_High_X451" SG_ 472 CCmHuExpressCoolConfig 0;
BA_ "GenSigTimeoutMsg_HU_B" SG_ 472 CCmHuExpressCoolConfig 0;
BA_ "GenSigTimeoutMsg_HU_A" SG_ 472 CCmHuExpressCoolConfig 0;
BA_ "GenSigSendType" SG_ 472 CCmHuExpressCoolConfig 1;
BA_ "GenSigTimeoutMsg_HU_High_X445" SG_ 472 CCmHuExpressCoolConfig 0;
BA_ "GenSigTimeoutMsg_HU_Mid_X445" SG_ 472 CCmHuExpressCoolConfig 0;
BA_ "GenSigTimeoutTime_HU_High_X445" SG_ 472 CCmHuExpressCoolConfig 0;
BA_ "GenSigTimeoutTime_HU_Mid_X445" SG_ 472 CCmHuExpressCoolConfig 0;
BA_ "GenSigTimeoutMsg_IVI" SG_ 472 CCmHuExpressCoolConfig 0;
BA_ "GenSigTimeoutTime_IVI" SG_ 472 CCmHuExpressCoolConfig 0;
BA_ "GenSigTimeoutTime_HU_Mid_X451" SG_ 472 CCmHuLowFanSpdConfigValue 0;
BA_ "GenSigTimeoutTime_HU_High_X451" SG_ 472 CCmHuLowFanSpdConfigValue 0;
BA_ "GenSigTimeoutTime_HU_B" SG_ 472 CCmHuLowFanSpdConfigValue 0;
BA_ "GenSigTimeoutTime_HU_A" SG_ 472 CCmHuLowFanSpdConfigValue 0;
BA_ "GenSigTimeoutMsg_HU_Mid_X451" SG_ 472 CCmHuLowFanSpdConfigValue 0;
BA_ "GenSigTimeoutMsg_HU_High_X451" SG_ 472 CCmHuLowFanSpdConfigValue 0;
BA_ "GenSigTimeoutMsg_HU_B" SG_ 472 CCmHuLowFanSpdConfigValue 0;
BA_ "GenSigTimeoutMsg_HU_A" SG_ 472 CCmHuLowFanSpdConfigValue 0;
BA_ "GenSigSendType" SG_ 472 CCmHuLowFanSpdConfigValue 1;
BA_ "GenSigTimeoutMsg_HU_High_X445" SG_ 472 CCmHuLowFanSpdConfigValue 0;
BA_ "GenSigTimeoutMsg_HU_Mid_X445" SG_ 472 CCmHuLowFanSpdConfigValue 0;
BA_ "GenSigTimeoutTime_HU_High_X445" SG_ 472 CCmHuLowFanSpdConfigValue 0;
BA_ "GenSigTimeoutTime_HU_Mid_X445" SG_ 472 CCmHuLowFanSpdConfigValue 0;
BA_ "GenSigTimeoutMsg_IVI" SG_ 472 CCmHuLowFanSpdConfigValue 0;
BA_ "GenSigTimeoutTime_IVI" SG_ 472 CCmHuLowFanSpdConfigValue 0;
BA_ "GenSigTimeoutTime_HU_Mid_X451" SG_ 472 CCmHuHiFanSpdConfigValue 0;
BA_ "GenSigTimeoutTime_HU_High_X451" SG_ 472 CCmHuHiFanSpdConfigValue 0;
BA_ "GenSigTimeoutTime_HU_B" SG_ 472 CCmHuHiFanSpdConfigValue 0;
BA_ "GenSigTimeoutTime_HU_A" SG_ 472 CCmHuHiFanSpdConfigValue 0;
BA_ "GenSigTimeoutMsg_HU_Mid_X451" SG_ 472 CCmHuHiFanSpdConfigValue 0;
BA_ "GenSigTimeoutMsg_HU_High_X451" SG_ 472 CCmHuHiFanSpdConfigValue 0;
BA_ "GenSigTimeoutMsg_HU_B" SG_ 472 CCmHuHiFanSpdConfigValue 0;
BA_ "GenSigTimeoutMsg_HU_A" SG_ 472 CCmHuHiFanSpdConfigValue 0;
BA_ "GenSigSendType" SG_ 472 CCmHuHiFanSpdConfigValue 1;
BA_ "GenSigTimeoutMsg_HU_High_X445" SG_ 472 CCmHuHiFanSpdConfigValue 0;
BA_ "GenSigTimeoutMsg_HU_Mid_X445" SG_ 472 CCmHuHiFanSpdConfigValue 0;
BA_ "GenSigTimeoutTime_HU_High_X445" SG_ 472 CCmHuHiFanSpdConfigValue 0;
BA_ "GenSigTimeoutTime_HU_Mid_X445" SG_ 472 CCmHuHiFanSpdConfigValue 0;
BA_ "GenSigTimeoutMsg_IVI" SG_ 472 CCmHuHiFanSpdConfigValue 0;
BA_ "GenSigTimeoutTime_IVI" SG_ 472 CCmHuHiFanSpdConfigValue 0;
BA_ "GenSigTimeoutTime_HU_Mid_X451" SG_ 472 CCmHuLowTempConfigValue 0;
BA_ "GenSigTimeoutTime_HU_High_X451" SG_ 472 CCmHuLowTempConfigValue 0;
BA_ "GenSigTimeoutTime_HU_B" SG_ 472 CCmHuLowTempConfigValue 0;
BA_ "GenSigTimeoutTime_HU_A" SG_ 472 CCmHuLowTempConfigValue 0;
BA_ "GenSigTimeoutMsg_HU_Mid_X451" SG_ 472 CCmHuLowTempConfigValue 0;
BA_ "GenSigTimeoutMsg_HU_High_X451" SG_ 472 CCmHuLowTempConfigValue 0;
BA_ "GenSigTimeoutMsg_HU_B" SG_ 472 CCmHuLowTempConfigValue 0;
BA_ "GenSigTimeoutMsg_HU_A" SG_ 472 CCmHuLowTempConfigValue 0;
BA_ "GenSigSendType" SG_ 472 CCmHuLowTempConfigValue 1;
BA_ "GenSigTimeoutMsg_HU_High_X445" SG_ 472 CCmHuLowTempConfigValue 0;
BA_ "GenSigTimeoutMsg_HU_Mid_X445" SG_ 472 CCmHuLowTempConfigValue 0;
BA_ "GenSigTimeoutTime_HU_High_X445" SG_ 472 CCmHuLowTempConfigValue 0;
BA_ "GenSigTimeoutTime_HU_Mid_X445" SG_ 472 CCmHuLowTempConfigValue 0;
BA_ "GenSigTimeoutMsg_IVI" SG_ 472 CCmHuLowTempConfigValue 0;
BA_ "GenSigTimeoutTime_IVI" SG_ 472 CCmHuLowTempConfigValue 0;
BA_ "GenSigTimeoutTime_HU_Mid_X451" SG_ 472 CCmHuHiTempConfigValue 0;
BA_ "GenSigTimeoutTime_HU_High_X451" SG_ 472 CCmHuHiTempConfigValue 0;
BA_ "GenSigTimeoutTime_HU_B" SG_ 472 CCmHuHiTempConfigValue 0;
BA_ "GenSigTimeoutTime_HU_A" SG_ 472 CCmHuHiTempConfigValue 0;
BA_ "GenSigTimeoutMsg_HU_Mid_X451" SG_ 472 CCmHuHiTempConfigValue 0;
BA_ "GenSigTimeoutMsg_HU_High_X451" SG_ 472 CCmHuHiTempConfigValue 0;
BA_ "GenSigTimeoutMsg_HU_B" SG_ 472 CCmHuHiTempConfigValue 0;
BA_ "GenSigTimeoutMsg_HU_A" SG_ 472 CCmHuHiTempConfigValue 0;
BA_ "GenSigSendType" SG_ 472 CCmHuHiTempConfigValue 1;
BA_ "GenSigTimeoutMsg_HU_High_X445" SG_ 472 CCmHuHiTempConfigValue 0;
BA_ "GenSigTimeoutMsg_HU_Mid_X445" SG_ 472 CCmHuHiTempConfigValue 0;
BA_ "GenSigTimeoutTime_HU_High_X445" SG_ 472 CCmHuHiTempConfigValue 0;
BA_ "GenSigTimeoutTime_HU_Mid_X445" SG_ 472 CCmHuHiTempConfigValue 0;
BA_ "GenSigTimeoutMsg_IVI" SG_ 472 CCmHuHiTempConfigValue 0;
BA_ "GenSigTimeoutTime_IVI" SG_ 472 CCmHuHiTempConfigValue 0;
BA_ "GenSigTimeoutTime_HU_Mid_X451" SG_ 474 HuCcmRearBlwrConfigAck 0;
BA_ "GenSigTimeoutTime_HU_High_X451" SG_ 474 HuCcmRearBlwrConfigAck 0;
BA_ "GenSigTimeoutTime_HU_B" SG_ 474 HuCcmRearBlwrConfigAck 0;
BA_ "GenSigTimeoutTime_HU_A" SG_ 474 HuCcmRearBlwrConfigAck 0;
BA_ "GenSigTimeoutMsg_HU_Mid_X451" SG_ 474 HuCcmRearBlwrConfigAck 0;
BA_ "GenSigTimeoutMsg_HU_High_X451" SG_ 474 HuCcmRearBlwrConfigAck 0;
BA_ "GenSigTimeoutMsg_HU_B" SG_ 474 HuCcmRearBlwrConfigAck 0;
BA_ "GenSigTimeoutMsg_HU_A" SG_ 474 HuCcmRearBlwrConfigAck 0;
BA_ "GenSigSendType" SG_ 474 HuCcmRearBlwrConfigAck 1;
BA_ "GenSigTimeoutMsg_HU_High_X445" SG_ 474 HuCcmRearBlwrConfigAck 0;
BA_ "GenSigTimeoutMsg_HU_Mid_X445" SG_ 474 HuCcmRearBlwrConfigAck 0;
BA_ "GenSigTimeoutTime_HU_High_X445" SG_ 474 HuCcmRearBlwrConfigAck 0;
BA_ "GenSigTimeoutTime_HU_Mid_X445" SG_ 474 HuCcmRearBlwrConfigAck 0;
BA_ "GenSigTimeoutMsg_IVI" SG_ 474 HuCcmRearBlwrConfigAck 0;
BA_ "GenSigTimeoutTime_IVI" SG_ 474 HuCcmRearBlwrConfigAck 0;
BA_ "GenSigTimeoutTime_HU_Mid_X451" SG_ 474 HuCcmEconConfigAck 0;
BA_ "GenSigTimeoutTime_HU_High_X451" SG_ 474 HuCcmEconConfigAck 0;
BA_ "GenSigTimeoutTime_HU_B" SG_ 474 HuCcmEconConfigAck 0;
BA_ "GenSigTimeoutTime_HU_A" SG_ 474 HuCcmEconConfigAck 0;
BA_ "GenSigTimeoutMsg_HU_Mid_X451" SG_ 474 HuCcmEconConfigAck 0;
BA_ "GenSigTimeoutMsg_HU_High_X451" SG_ 474 HuCcmEconConfigAck 0;
BA_ "GenSigTimeoutMsg_HU_B" SG_ 474 HuCcmEconConfigAck 0;
BA_ "GenSigTimeoutMsg_HU_A" SG_ 474 HuCcmEconConfigAck 0;
BA_ "GenSigSendType" SG_ 474 HuCcmEconConfigAck 1;
BA_ "GenSigTimeoutMsg_HU_High_X445" SG_ 474 HuCcmEconConfigAck 0;
BA_ "GenSigTimeoutMsg_HU_Mid_X445" SG_ 474 HuCcmEconConfigAck 0;
BA_ "GenSigTimeoutTime_HU_High_X445" SG_ 474 HuCcmEconConfigAck 0;
BA_ "GenSigTimeoutTime_HU_Mid_X445" SG_ 474 HuCcmEconConfigAck 0;
BA_ "GenSigTimeoutMsg_IVI" SG_ 474 HuCcmEconConfigAck 0;
BA_ "GenSigTimeoutTime_IVI" SG_ 474 HuCcmEconConfigAck 0;
BA_ "GenSigTimeoutTime_HU_Mid_X451" SG_ 474 HuCcmExpressCoolConfigAck 0;
BA_ "GenSigTimeoutTime_HU_High_X451" SG_ 474 HuCcmExpressCoolConfigAck 0;
BA_ "GenSigTimeoutTime_HU_B" SG_ 474 HuCcmExpressCoolConfigAck 0;
BA_ "GenSigTimeoutTime_HU_A" SG_ 474 HuCcmExpressCoolConfigAck 0;
BA_ "GenSigTimeoutMsg_HU_Mid_X451" SG_ 474 HuCcmExpressCoolConfigAck 0;
BA_ "GenSigTimeoutMsg_HU_High_X451" SG_ 474 HuCcmExpressCoolConfigAck 0;
BA_ "GenSigTimeoutMsg_HU_B" SG_ 474 HuCcmExpressCoolConfigAck 0;
BA_ "GenSigTimeoutMsg_HU_A" SG_ 474 HuCcmExpressCoolConfigAck 0;
BA_ "GenSigSendType" SG_ 474 HuCcmExpressCoolConfigAck 1;
BA_ "GenSigTimeoutMsg_HU_High_X445" SG_ 474 HuCcmExpressCoolConfigAck 0;
BA_ "GenSigTimeoutMsg_HU_Mid_X445" SG_ 474 HuCcmExpressCoolConfigAck 0;
BA_ "GenSigTimeoutTime_HU_High_X445" SG_ 474 HuCcmExpressCoolConfigAck 0;
BA_ "GenSigTimeoutTime_HU_Mid_X445" SG_ 474 HuCcmExpressCoolConfigAck 0;
BA_ "GenSigTimeoutMsg_IVI" SG_ 474 HuCcmExpressCoolConfigAck 0;
BA_ "GenSigTimeoutTime_IVI" SG_ 474 HuCcmExpressCoolConfigAck 0;
BA_ "GenSigTimeoutTime_HU_Mid_X451" SG_ 474 HuCCmLowFanSpdConfigValueAck 0;
BA_ "GenSigTimeoutTime_HU_High_X451" SG_ 474 HuCCmLowFanSpdConfigValueAck 0;
BA_ "GenSigTimeoutTime_HU_B" SG_ 474 HuCCmLowFanSpdConfigValueAck 0;
BA_ "GenSigTimeoutTime_HU_A" SG_ 474 HuCCmLowFanSpdConfigValueAck 0;
BA_ "GenSigTimeoutMsg_HU_Mid_X451" SG_ 474 HuCCmLowFanSpdConfigValueAck 0;
BA_ "GenSigTimeoutMsg_HU_High_X451" SG_ 474 HuCCmLowFanSpdConfigValueAck 0;
BA_ "GenSigTimeoutMsg_HU_B" SG_ 474 HuCCmLowFanSpdConfigValueAck 0;
BA_ "GenSigTimeoutMsg_HU_A" SG_ 474 HuCCmLowFanSpdConfigValueAck 0;
BA_ "GenSigSendType" SG_ 474 HuCCmLowFanSpdConfigValueAck 1;
BA_ "GenSigTimeoutMsg_HU_High_X445" SG_ 474 HuCCmLowFanSpdConfigValueAck 0;
BA_ "GenSigTimeoutMsg_HU_Mid_X445" SG_ 474 HuCCmLowFanSpdConfigValueAck 0;
BA_ "GenSigTimeoutTime_HU_High_X445" SG_ 474 HuCCmLowFanSpdConfigValueAck 0;
BA_ "GenSigTimeoutTime_HU_Mid_X445" SG_ 474 HuCCmLowFanSpdConfigValueAck 0;
BA_ "GenSigTimeoutMsg_IVI" SG_ 474 HuCCmLowFanSpdConfigValueAck 0;
BA_ "GenSigTimeoutTime_IVI" SG_ 474 HuCCmLowFanSpdConfigValueAck 0;
BA_ "GenSigTimeoutTime_HU_Mid_X451" SG_ 474 HuCCmHiFanSpdConfigValueAck 0;
BA_ "GenSigTimeoutTime_HU_High_X451" SG_ 474 HuCCmHiFanSpdConfigValueAck 0;
BA_ "GenSigTimeoutTime_HU_B" SG_ 474 HuCCmHiFanSpdConfigValueAck 0;
BA_ "GenSigTimeoutTime_HU_A" SG_ 474 HuCCmHiFanSpdConfigValueAck 0;
BA_ "GenSigTimeoutMsg_HU_Mid_X451" SG_ 474 HuCCmHiFanSpdConfigValueAck 0;
BA_ "GenSigTimeoutMsg_HU_High_X451" SG_ 474 HuCCmHiFanSpdConfigValueAck 0;
BA_ "GenSigTimeoutMsg_HU_B" SG_ 474 HuCCmHiFanSpdConfigValueAck 0;
BA_ "GenSigTimeoutMsg_HU_A" SG_ 474 HuCCmHiFanSpdConfigValueAck 0;
BA_ "GenSigSendType" SG_ 474 HuCCmHiFanSpdConfigValueAck 1;
BA_ "GenSigTimeoutMsg_HU_High_X445" SG_ 474 HuCCmHiFanSpdConfigValueAck 0;
BA_ "GenSigTimeoutMsg_HU_Mid_X445" SG_ 474 HuCCmHiFanSpdConfigValueAck 0;
BA_ "GenSigTimeoutTime_HU_High_X445" SG_ 474 HuCCmHiFanSpdConfigValueAck 0;
BA_ "GenSigTimeoutTime_HU_Mid_X445" SG_ 474 HuCCmHiFanSpdConfigValueAck 0;
BA_ "GenSigTimeoutMsg_IVI" SG_ 474 HuCCmHiFanSpdConfigValueAck 0;
BA_ "GenSigTimeoutTime_IVI" SG_ 474 HuCCmHiFanSpdConfigValueAck 0;
BA_ "GenSigTimeoutTime_HU_Mid_X451" SG_ 474 HuCCmLowTempConfigValueAck 0;
BA_ "GenSigTimeoutTime_HU_High_X451" SG_ 474 HuCCmLowTempConfigValueAck 0;
BA_ "GenSigTimeoutTime_HU_B" SG_ 474 HuCCmLowTempConfigValueAck 0;
BA_ "GenSigTimeoutTime_HU_A" SG_ 474 HuCCmLowTempConfigValueAck 0;
BA_ "GenSigTimeoutMsg_HU_Mid_X451" SG_ 474 HuCCmLowTempConfigValueAck 0;
BA_ "GenSigTimeoutMsg_HU_High_X451" SG_ 474 HuCCmLowTempConfigValueAck 0;
BA_ "GenSigTimeoutMsg_HU_B" SG_ 474 HuCCmLowTempConfigValueAck 0;
BA_ "GenSigTimeoutMsg_HU_A" SG_ 474 HuCCmLowTempConfigValueAck 0;
BA_ "GenSigSendType" SG_ 474 HuCCmLowTempConfigValueAck 1;
BA_ "GenSigTimeoutMsg_HU_High_X445" SG_ 474 HuCCmLowTempConfigValueAck 0;
BA_ "GenSigTimeoutMsg_HU_Mid_X445" SG_ 474 HuCCmLowTempConfigValueAck 0;
BA_ "GenSigTimeoutTime_HU_High_X445" SG_ 474 HuCCmLowTempConfigValueAck 0;
BA_ "GenSigTimeoutTime_HU_Mid_X445" SG_ 474 HuCCmLowTempConfigValueAck 0;
BA_ "GenSigTimeoutMsg_IVI" SG_ 474 HuCCmLowTempConfigValueAck 0;
BA_ "GenSigTimeoutTime_IVI" SG_ 474 HuCCmLowTempConfigValueAck 0;
BA_ "GenSigTimeoutTime_HU_Mid_X451" SG_ 474 HuCCmFanControlDuringVRAck 0;
BA_ "GenSigTimeoutTime_HU_High_X451" SG_ 474 HuCCmFanControlDuringVRAck 0;
BA_ "GenSigTimeoutTime_HU_B" SG_ 474 HuCCmFanControlDuringVRAck 0;
BA_ "GenSigTimeoutTime_HU_A" SG_ 474 HuCCmFanControlDuringVRAck 0;
BA_ "GenSigTimeoutMsg_HU_Mid_X451" SG_ 474 HuCCmFanControlDuringVRAck 0;
BA_ "GenSigTimeoutMsg_HU_High_X451" SG_ 474 HuCCmFanControlDuringVRAck 0;
BA_ "GenSigTimeoutMsg_HU_B" SG_ 474 HuCCmFanControlDuringVRAck 0;
BA_ "GenSigTimeoutMsg_HU_A" SG_ 474 HuCCmFanControlDuringVRAck 0;
BA_ "GenSigStartValue" SG_ 474 HuCCmFanControlDuringVRAck 1;
BA_ "GenSigSendType" SG_ 474 HuCCmFanControlDuringVRAck 1;
BA_ "GenSigTimeoutMsg_HU_High_X445" SG_ 474 HuCCmFanControlDuringVRAck 0;
BA_ "GenSigTimeoutMsg_HU_Mid_X445" SG_ 474 HuCCmFanControlDuringVRAck 0;
BA_ "GenSigTimeoutTime_HU_High_X445" SG_ 474 HuCCmFanControlDuringVRAck 0;
BA_ "GenSigTimeoutTime_HU_Mid_X445" SG_ 474 HuCCmFanControlDuringVRAck 0;
BA_ "GenSigTimeoutMsg_IVI" SG_ 474 HuCCmFanControlDuringVRAck 0;
BA_ "GenSigTimeoutTime_IVI" SG_ 474 HuCCmFanControlDuringVRAck 0;
BA_ "GenSigTimeoutTime_HU_Mid_X451" SG_ 474 HuCCmHiTempConfigValueAck 0;
BA_ "GenSigTimeoutTime_HU_High_X451" SG_ 474 HuCCmHiTempConfigValueAck 0;
BA_ "GenSigTimeoutTime_HU_B" SG_ 474 HuCCmHiTempConfigValueAck 0;
BA_ "GenSigTimeoutTime_HU_A" SG_ 474 HuCCmHiTempConfigValueAck 0;
BA_ "GenSigTimeoutMsg_HU_Mid_X451" SG_ 474 HuCCmHiTempConfigValueAck 0;
BA_ "GenSigTimeoutMsg_HU_High_X451" SG_ 474 HuCCmHiTempConfigValueAck 0;
BA_ "GenSigTimeoutMsg_HU_B" SG_ 474 HuCCmHiTempConfigValueAck 0;
BA_ "GenSigTimeoutMsg_HU_A" SG_ 474 HuCCmHiTempConfigValueAck 0;
BA_ "GenSigSendType" SG_ 474 HuCCmHiTempConfigValueAck 1;
BA_ "GenSigTimeoutMsg_HU_High_X445" SG_ 474 HuCCmHiTempConfigValueAck 0;
BA_ "GenSigTimeoutMsg_HU_Mid_X445" SG_ 474 HuCCmHiTempConfigValueAck 0;
BA_ "GenSigTimeoutTime_HU_High_X445" SG_ 474 HuCCmHiTempConfigValueAck 0;
BA_ "GenSigTimeoutTime_HU_Mid_X445" SG_ 474 HuCCmHiTempConfigValueAck 0;
BA_ "GenSigTimeoutMsg_IVI" SG_ 474 HuCCmHiTempConfigValueAck 0;
BA_ "GenSigTimeoutTime_IVI" SG_ 474 HuCCmHiTempConfigValueAck 0;
VAL_ 370 AebIntervention 1 "AEB Intervention" 0 "No AEB Intervention" ;
VAL_ 370 RCrankEnableStatus 3 "Signal not available" 2 "Value implausible." 1 "Reserved" 0 "Value is correct" ;
VAL_ 370 RCrankEnable 1 "Disable" 0 "Enable" ;
VAL_ 370 BrkLightSig2Status 3 "Signal not available" 2 "Value is implausible" 1 "Reserved for future" 0 "Value is correct" ;
VAL_ 370 BrkLightSig2 2 "Panic Brake detected" 1 "Brake lamp ON request" 0 "No request" ;
VAL_ 370 ABsActive 1 "ABS intervention by ABS/ESP is active" 0 "No ABS internention by ABS/ESP" ;
VAL_ 370 TCsStatus 3 " TCS switched off due to a detected failure at TCS system" 2 "Vehicle not equipped with TCS function" 1 "TCS switched off due to a system passive request" 0 "TCS fully available @ MFL is OFF" ;
VAL_ 370 TCsActive 1 "TCs intervention by ESP system @MFL is ON" 0 "No TCs intervention by ESP system @MFL is OFF" ;
VAL_ 370 ESpStatus 3 "ESP switched off due to a detected failure at ESP system" 2 "Vehicle not equipped with ESP function" 1 "ESP switched off due to a system passive request" 0 "ESP fully available @ MFL is OFF" ;
VAL_ 370 ESpActive 1 "ESP intervention by ESP system is active @ MFL is BLINKING @ 2 Hz (conf value)" 0 "No ESP intervention by ESP system @ MFL is OFF" ;
VAL_ 370 NoGearshiftReqStatus 3 "Value is correct.ESP intervention active.Intervention requested" 2 "Value is implausible due to failure at TCS/ESP" 1 "Signal is not available" 0 "Value is correct.No TCS/ESP intervention.No interventon req" ;
VAL_ 370 NoGearshiftReq 1 "ESP inhibits automatic gear shift" 0 "Gear shift not inflluenced by ESP" ;
VAL_ 370 EBdStatus 3 "Reserved for future" 2 "EBD function is switched off due to failure @EBD Warn Lamp is ON" 1 "Reserved for future" 0 "EBD function fully available@EBD Warning Lamp is OFF" ;
VAL_ 370 EBdActive 1 "EBD intervention  by ABS/ESP is active" 0 "No EBD intervention by ABS/ESP" ;
VAL_ 370 ABsStatus 3 "Reserved for future" 2 "ABS function switched off due to failure at ABS/ESP@ABS Warn Lamp ON" 1 "Reserved for future" 0 "ABS function fully available@ABS Warning Lamp is OFF" ;
VAL_ 370 CardanTrqLimStatus 3 "Signal is not available" 2 "Signal is implausible" 1 "CardanTrqLim Signal is correct and torque intervention is required" 0 "CardanTrqLim Signal is correct and torque intervention is not required" ;
VAL_ 370 HHcStatus 3 "HHC function not available" 2 "HHC function switched off due to a detected failure at  ESP system" 1 "Reserved for future" 0 "HHC function is fully available" ;
VAL_ 370 BrkLightSigStatus 3 "Signal not available" 2 "Value is implausible" 1 "Reserved for future" 0 "Value is correct" ;
VAL_ 370 BrkLightSig 1 "Brake lamp on request" 0 "No request of brake lamp" ;
VAL_ 370 CruiseCntShutESPStatus 3 "Cruise Control shut down request not available" 2 "Value is implausible " 1 "Reserved for future use" 0 "Signal is correct" ;
VAL_ 370 CruiseCntShutESP 1 "Cruise ctrl shut off is requested by ESP" 0 "Cruise ctrl shut off is not requested by ESP" ;
VAL_ 370 HDcAvailability 1 "HDC is not available " 0 "HDC is available" ;
VAL_ 370 VehSpdSetHDCStatus 3 "Signal not available" 2 "Information given at VehSpdSetHDC is implausible" 1 "Gear shift in process" 0 "information given is correct	
" ;
VAL_ 370 HHcActive 1 "HHC Intervention by ESP system is active" 0 "No HHC intervention by ESP system" ;
VAL_ 370 HDcActive 1 "HDC intervention by ESP syst is active@HDC Lamp is Blinking" 0 "No HDC intervention by ESP system@HDC Lamp is OFF" ;
VAL_ 370 HDcStatus 3 "HDC deactivation due to vehicle speed more than 60 kmph" 2 "HDC function switched off due to a detected failure at  ESP system @ HDC failure lamp is ON" 1 "HDC switched off due to a system passive request or switch" 0 "HDC function fully available @HDC failure lamp is OFF" ;
VAL_ 371 SteerAngEPAsDirGen2 1 "Steering Wheel turned in the Counter clockwise direction" 0 "Steering Wheel turned in the Clockwise direction" ;
VAL_ 371 SteerAngEPASStatusGen2 3 "Reserved" 2 "SAS angle Value is implausible" 1 "Reserved " 0 "Information given by SAS angle is correct and according to specification" ;
VAL_ 372 WhlSpdRrStatus 3 "Reserved for future" 2 "Value is implausible due to failure at wheel speed sensor RR" 1 "Reserved for futute" 0 "Value is correct" ;
VAL_ 372 WhlSpdRlStatus 3 "Reserved for future" 2 "Value is implausible due to failure at wheel speed sensor Rl" 1 "Reserved for future" 0 "Value is correct" ;
VAL_ 372 WhlSpdFrStatus 3 "Reserved for future" 2 "Value is implausible due to failure at wheel speed sensor FR" 1 "Reserved for future" 0 "Value is correct" ;
VAL_ 372 WhlSpdFlStatus 3 "Reserved for future" 2 "Value is implausible due to failure at wheel speed sensor FL" 1 "Reserved for future" 0 "Value is correct" ;
VAL_ 374 DrvModeIndctnESP2Status 3 "Signal is not available" 2 "Signal is implausible" 1 "Reserved" 0 "Information given is correct and according to specification" ;
VAL_ 374 DrvModeIndctnESP2 7 "Reserved" 6 "Reserved" 5 "Reserved" 4 "Reserved" 3 "Reserved" 2 "Rough Road Mode" 1 "Sports Mode" 0 "Normal Mode" ;
VAL_ 374 ODoABsStatus 3 "Reserved for future use" 2 "Signal is implausible due to detected failure" 1 "Reserved for future" 0 "Signal is correct" ;
VAL_ 374 VehSpdABsStatus 3 "Reserved for future" 2 "Value is implausible" 1 "Reserved for future" 0 "Value is correct" ;
VAL_ 376 MasterCylinderPresStatus 3 "Reserved for future use" 2 "MasterCylinderPres is implausible" 1 "Reserved for future use" 0 "MasterCylinderPres is correct " ;
VAL_ 407 VehSpdICStatus 3 "Reserved" 2 "Value is implausibe" 1 "Reserved" 0 "Value is plausible" ;
VAL_ 407 VehAnglSpdIcStatus 3 "Signal not available" 2 "Value is implausibe" 1 "Reserved" 0 "Value is plausible" ;
VAL_ 432 HuFeature12SignalVal1 31 "Reserved" 30 "Reserved" 29 "Reserved" 28 "Reserved" 27 "Reserved" 26 "Reserved" 25 "Reserved" 24 "Reserved" 23 "Reserved" 22 "Reserved" 21 "Reserved" 20 "Reserved" 19 "Reserved" 18 "Reserved" 17 "Reserved" 16 "Reserved" 15 "Reserved" 14 "Reserved" 13 "Reserved" 12 "Reserved" 11 "Reserved" 10 "Reserved" 9 "Reserved" 8 "Reserved" 7 "Reserved" 6 "Reserved" 5 "Reserved" 4 "Reserved" 3 "Reserved" 2 "Reserved" 1 "Reserved" 0 "Reserved" ;
VAL_ 432 HuFeature12ActiveSignalVal 3 "Reserved" 2 "Active value is HuFeature12SignalVal3" 1 "Active value is HuFeature12SignalVal2" 0 "Active value is HuFeature12SignalVal1" ;
VAL_ 432 HuFeature11ActiveSignalVal 1 "Active value is reserved" 0 "Active value is reserved" ;
VAL_ 432 HuFeature10ActiveSignalVal 1 "Active value is reserved" 0 "Active value is reserved" ;
VAL_ 432 HuFeature9ActiveSignalVal 1 "Active value is reserved" 0 "Active value is reserved" ;
VAL_ 432 HuFeature8ActiveSignalVal 1 "Active value is reserved" 0 "Active value is reserved" ;
VAL_ 432 HuFeature12SignalVal2 31 "Reserved" 30 "Reserved" 29 "Reserved" 28 "Reserved" 27 "Reserved" 26 "Reserved" 25 "Reserved" 24 "Reserved" 23 "Reserved" 22 "Reserved" 21 "Reserved" 20 "Reserved" 19 "Reserved" 18 "Reserved" 17 "Reserved" 16 "Reserved" 15 "Reserved" 14 "Reserved" 13 "Reserved" 12 "Reserved" 11 "Reserved" 10 "Reserved" 9 "Reserved" 8 "Reserved" 7 "Reserved" 6 "Reserved" 5 "Reserved" 4 "Reserved" 3 "Reserved" 2 "Reserved" 1 "Reserved" 0 "Reserved" ;
VAL_ 432 HuFeature13SignalVal1 31 "Reserved" 30 "Reserved" 29 "Reserved" 28 "Reserved" 27 "Reserved" 26 "Reserved" 25 "Reserved" 24 "Reserved" 23 "Reserved" 22 "Reserved" 21 "Reserved" 20 "Reserved" 19 "Reserved" 18 "Reserved" 17 "Reserved" 16 "Reserved" 15 "Reserved" 14 "Reserved" 13 "Reserved" 12 "Reserved" 11 "Reserved" 10 "Reserved" 9 "Reserved" 8 "Reserved" 7 "Reserved" 6 "Reserved" 5 "Reserved" 4 "Reserved" 3 "Reserved" 2 "Reserved" 1 "Reserved" 0 "Reserved" ;
VAL_ 432 HuFeature13ActiveSignalVal 3 "Reserved" 2 "Active value is HuFeature13SignalVal3" 1 "Active value is HuFeature13SignalVal2" 0 "Active value is HuFeature13SignalVal1" ;
VAL_ 432 HuFeature12SignalVal3 31 "Reserved" 30 "Reserved" 29 "Reserved" 28 "Reserved" 27 "Reserved" 26 "Reserved" 25 "Reserved" 24 "Reserved" 23 "Reserved" 22 "Reserved" 21 "Reserved" 20 "Reserved" 19 "Reserved" 18 "Reserved" 17 "Reserved" 16 "Reserved" 15 "Reserved" 14 "Reserved" 13 "Reserved" 12 "Reserved" 11 "Reserved" 10 "Reserved" 9 "Reserved" 8 "Reserved" 7 "Reserved" 6 "Reserved" 5 "Reserved" 4 "Reserved" 3 "Reserved" 2 "Reserved" 1 "Reserved" 0 "Reserved" ;
VAL_ 432 HuFeature13SignalVal2 31 "Reserved" 30 "Reserved" 29 "Reserved" 28 "Reserved" 27 "Reserved" 26 "Reserved" 25 "Reserved" 24 "Reserved" 23 "Reserved" 22 "Reserved" 21 "Reserved" 20 "Reserved" 19 "Reserved" 18 "Reserved" 17 "Reserved" 16 "Reserved" 15 "Reserved" 14 "Reserved" 13 "Reserved" 12 "Reserved" 11 "Reserved" 10 "Reserved" 9 "Reserved" 8 "Reserved" 7 "Reserved" 6 "Reserved" 5 "Reserved" 4 "Reserved" 3 "Reserved" 2 "Reserved" 1 "Reserved" 0 "Reserved" ;
VAL_ 432 HuFeature13SignalVal3 31 "Reserved" 30 "Reserved" 29 "Reserved" 28 "Reserved" 27 "Reserved" 26 "Reserved" 25 "Reserved" 24 "Reserved" 23 "Reserved" 22 "Reserved" 21 "Reserved" 20 "Reserved" 19 "Reserved" 18 "Reserved" 17 "Reserved" 16 "Reserved" 15 "Reserved" 14 "Reserved" 13 "Reserved" 12 "Reserved" 11 "Reserved" 10 "Reserved" 9 "Reserved" 8 "Reserved" 7 "Reserved" 6 "Reserved" 5 "Reserved" 4 "Reserved" 3 "Reserved" 2 "Reserved" 1 "Reserved" 0 "Reserved" ;
VAL_ 433 HuFeature14SignalVal2 31 "Reserved" 30 "Reserved" 29 "Reserved" 28 "Reserved" 27 "Reserved" 26 "Reserved" 25 "Reserved" 24 "Reserved" 23 "Reserved" 22 "Reserved" 21 "Reserved" 20 "Reserved" 19 "Reserved" 18 "Reserved" 17 "Reserved" 16 "Reserved" 15 "Reserved" 14 "Reserved" 13 "Reserved" 12 "Reserved" 11 "Reserved" 10 "Reserved" 9 "Reserved" 8 "Reserved" 7 "Reserved" 6 "Reserved" 5 "Reserved" 4 "Reserved" 3 "Reserved" 2 "Reserved" 1 "Reserved" 0 "Reserved" ;
VAL_ 433 HuFeature14SignalVal1 31 "Reserved" 30 "Reserved" 29 "Reserved" 28 "Reserved" 27 "Reserved" 26 "Reserved" 25 "Reserved" 24 "Reserved" 23 "Reserved" 22 "Reserved" 21 "Reserved" 20 "Reserved" 19 "Reserved" 18 "Reserved" 17 "Reserved" 16 "Reserved" 15 "Reserved" 14 "Reserved" 13 "Reserved" 12 "Reserved" 11 "Reserved" 10 "Reserved" 9 "Reserved" 8 "Reserved" 7 "Reserved" 6 "Reserved" 5 "Reserved" 4 "Reserved" 3 "Reserved" 2 "Reserved" 1 "Reserved" 0 "Reserved" ;
VAL_ 433 HuFeature15SignalVal1 31 "Reserved" 30 "Reserved" 29 "Reserved" 28 "Reserved" 27 "Reserved" 26 "Reserved" 25 "Reserved" 24 "Reserved" 23 "Reserved" 22 "Reserved" 21 "Reserved" 20 "Reserved" 19 "Reserved" 18 "Reserved" 17 "Reserved" 16 "Reserved" 15 "Reserved" 14 "Reserved" 13 "Reserved" 12 "Reserved" 11 "Reserved" 10 "Reserved" 9 "Reserved" 8 "Reserved" 7 "Reserved" 6 "Reserved" 5 "Reserved" 4 "Reserved" 3 "Reserved" 2 "Reserved" 1 "Reserved" 0 "Reserved" ;
VAL_ 433 HuFeature14SignalVal3 31 "Reserved" 30 "Reserved" 29 "Reserved" 28 "Reserved" 27 "Reserved" 26 "Reserved" 25 "Reserved" 24 "Reserved" 23 "Reserved" 22 "Reserved" 21 "Reserved" 20 "Reserved" 19 "Reserved" 18 "Reserved" 17 "Reserved" 16 "Reserved" 15 "Reserved" 14 "Reserved" 13 "Reserved" 12 "Reserved" 11 "Reserved" 10 "Reserved" 9 "Reserved" 8 "Reserved" 7 "Reserved" 6 "Reserved" 5 "Reserved" 4 "Reserved" 3 "Reserved" 2 "Reserved" 1 "Reserved" 0 "Reserved" ;
VAL_ 433 HuFeature15SignalVal2 31 "Reserved" 30 "Reserved" 29 "Reserved" 28 "Reserved" 27 "Reserved" 26 "Reserved" 25 "Reserved" 24 "Reserved" 23 "Reserved" 22 "Reserved" 21 "Reserved" 20 "Reserved" 19 "Reserved" 18 "Reserved" 17 "Reserved" 16 "Reserved" 15 "Reserved" 14 "Reserved" 13 "Reserved" 12 "Reserved" 11 "Reserved" 10 "Reserved" 9 "Reserved" 8 "Reserved" 7 "Reserved" 6 "Reserved" 5 "Reserved" 4 "Reserved" 3 "Reserved" 2 "Reserved" 1 "Reserved" 0 "Reserved" ;
VAL_ 433 HuFeature14ActiveSignalVal 3 "Reserved" 2 "Active value is HuFeature13SignalVal3" 1 "Active value is HuFeature14SignalVal2" 0 "Active value is HuFeature14SignalVal1" ;
VAL_ 433 HuFeature15SignalVal3 31 "Reserved" 30 "Reserved" 29 "Reserved" 28 "Reserved" 27 "Reserved" 26 "Reserved" 25 "Reserved" 24 "Reserved" 23 "Reserved" 22 "Reserved" 21 "Reserved" 20 "Reserved" 19 "Reserved" 18 "Reserved" 17 "Reserved" 16 "Reserved" 15 "Reserved" 14 "Reserved" 13 "Reserved" 12 "Reserved" 11 "Reserved" 10 "Reserved" 9 "Reserved" 8 "Reserved" 7 "Reserved" 6 "Reserved" 5 "Reserved" 4 "Reserved" 3 "Reserved" 2 "Reserved" 1 "Reserved" 0 "Reserved" ;
VAL_ 433 HuFeature15ActiveSignalVal 3 "Reserved" 2 "Active value is HuFeature15SignalVal3" 1 "Active value is HuFeature15SignalVal2" 0 "Active value is HuFeature15SignalVal1" ;
VAL_ 434 BCmFeature11ActiveSignalVal 1 "Active value is reserved" 0 "Active value is reserved" ;
VAL_ 434 BCmFeature11State 1 "Feature 11 is enabled in BCM" 0 "Feature 11 is disabled in BCM" ;
VAL_ 434 BCmFeature10ActiveSignalVal 1 "Active value is reserved" 0 "Active value is reserved" ;
VAL_ 434 BCmFeature10State 1 "Feature 10 is enabled in BCM" 0 "Feature 10 is disabled in BCM" ;
VAL_ 434 BCmFeature9ActiveSignalVal 1 "Active value is reserved" 0 "Active value is reserved" ;
VAL_ 434 BCmFeature9State 1 "Feature 9 is enabled in BCM" 0 "Feature 9 is disabled in BCM" ;
VAL_ 434 BCmFeature8ActiveSignalVal 1 "Active value is reserved" 0 "Active value is reserved" ;
VAL_ 434 BCmFeature8State 1 "Feature 8 is enabled in BCM" 0 "Feature 8 is disabled in BCM" ;
VAL_ 434 BCmFeature12SignalVal2 31 "Reserved" 30 "Reserved" 29 "Reserved" 28 "Reserved" 27 "Reserved" 26 "Reserved" 25 "Reserved" 24 "Reserved" 23 "Reserved" 22 "Reserved" 21 "Reserved" 20 "Reserved" 19 "Reserved" 18 "Reserved" 17 "Reserved" 16 "Reserved" 15 "Reserved" 14 "Reserved" 13 "Reserved" 12 "Reserved" 11 "Reserved" 10 "Reserved" 9 "Reserved" 8 "Reserved" 7 "Reserved" 6 "Reserved" 5 "Reserved" 4 "Reserved" 3 "Reserved" 2 "Reserved" 1 "Reserved" 0 "Reserved" ;
VAL_ 434 BCmFeature12SignalVal1 31 "Reserved" 30 "Reserved" 29 "Reserved" 28 "Reserved" 27 "Reserved" 26 "Reserved" 25 "Reserved" 24 "Reserved" 23 "Reserved" 22 "Reserved" 21 "Reserved" 20 "Reserved" 19 "Reserved" 18 "Reserved" 17 "Reserved" 16 "Reserved" 15 "Reserved" 14 "Reserved" 13 "Reserved" 12 "Reserved" 11 "Reserved" 10 "Reserved" 9 "Reserved" 8 "Reserved" 7 "Reserved" 6 "Reserved" 5 "Reserved" 4 "Reserved" 3 "Reserved" 2 "Reserved" 1 "Reserved" 0 "Reserved" ;
VAL_ 434 BCmFeature12State 1 "Feature 12 is enabled in BCM" 0 "Feature 12 is disabled in BCM" ;
VAL_ 434 BCmFeature12SignalVal3 31 "Reserved" 30 "Reserved" 29 "Reserved" 28 "Reserved" 27 "Reserved" 26 "Reserved" 25 "Reserved" 24 "Reserved" 23 "Reserved" 22 "Reserved" 21 "Reserved" 20 "Reserved" 19 "Reserved" 18 "Reserved" 17 "Reserved" 16 "Reserved" 15 "Reserved" 14 "Reserved" 13 "Reserved" 12 "Reserved" 11 "Reserved" 10 "Reserved" 9 "Reserved" 8 "Reserved" 7 "Reserved" 6 "Reserved" 5 "Reserved" 4 "Reserved" 3 "Reserved" 2 "Reserved" 1 "Reserved" 0 "Reserved" ;
VAL_ 434 BCmFeature13SignalVal1 31 "Reserved" 30 "Reserved" 29 "Reserved" 28 "Reserved" 27 "Reserved" 26 "Reserved" 25 "Reserved" 24 "Reserved" 23 "Reserved" 22 "Reserved" 21 "Reserved" 20 "Reserved" 19 "Reserved" 18 "Reserved" 17 "Reserved" 16 "Reserved" 15 "Reserved" 14 "Reserved" 13 "Reserved" 12 "Reserved" 11 "Reserved" 10 "Reserved" 9 "Reserved" 8 "Reserved" 7 "Reserved" 6 "Reserved" 5 "Reserved" 4 "Reserved" 3 "Reserved" 2 "Reserved" 1 "Reserved" 0 "Reserved" ;
VAL_ 434 BCmFeature13State 1 "Feature 13 is enabled in BCM" 0 "Feature 13 is disabled in BCM" ;
VAL_ 434 BCmFeature12ActiveSignalVal 3 "Reserved" 2 "Active value is BCmFeature12SignalVal3" 1 "Active value is BCmFeature12SignalVal2" 0 "Active value is BCmFeature12SignalVal1" ;
VAL_ 434 BCmFeature13SignalVal3 31 "Reserved" 30 "Reserved" 29 "Reserved" 28 "Reserved" 27 "Reserved" 26 "Reserved" 25 "Reserved" 24 "Reserved" 23 "Reserved" 22 "Reserved" 21 "Reserved" 20 "Reserved" 19 "Reserved" 18 "Reserved" 17 "Reserved" 16 "Reserved" 15 "Reserved" 14 "Reserved" 13 "Reserved" 12 "Reserved" 11 "Reserved" 10 "Reserved" 9 "Reserved" 8 "Reserved" 7 "Reserved" 6 "Reserved" 5 "Reserved" 4 "Reserved" 3 "Reserved" 2 "Reserved" 1 "Reserved" 0 "Reserved" ;
VAL_ 434 BCmFeature13SignalVal2 31 "Reserved" 30 "Reserved" 29 "Reserved" 28 "Reserved" 27 "Reserved" 26 "Reserved" 25 "Reserved" 24 "Reserved" 23 "Reserved" 22 "Reserved" 21 "Reserved" 20 "Reserved" 19 "Reserved" 18 "Reserved" 17 "Reserved" 16 "Reserved" 15 "Reserved" 14 "Reserved" 13 "Reserved" 12 "Reserved" 11 "Reserved" 10 "Reserved" 9 "Reserved" 8 "Reserved" 7 "Reserved" 6 "Reserved" 5 "Reserved" 4 "Reserved" 3 "Reserved" 2 "Reserved" 1 "Reserved" 0 "Reserved" ;
VAL_ 434 BCmFeature13ActiveSignalVal 3 "Reserved" 2 "Active value is BCmFeature13SignalVal3" 1 "Active value is BCmFeature13SignalVal2" 0 "Active value is BCmFeature13SignalVal1" ;
VAL_ 435 BCmFeature14SignalVal2 31 "Reserved" 30 "Reserved" 29 "Reserved" 28 "Reserved" 27 "Reserved" 26 "Reserved" 25 "Reserved" 24 "Reserved" 23 "Reserved" 22 "Reserved" 21 "Reserved" 20 "Reserved" 19 "Reserved" 18 "Reserved" 17 "Reserved" 16 "Reserved" 15 "Reserved" 14 "Reserved" 13 "Reserved" 12 "Reserved" 11 "Reserved" 10 "Reserved" 9 "Reserved" 8 "Reserved" 7 "Reserved" 6 "Reserved" 5 "Reserved" 4 "Reserved" 3 "Reserved" 2 "Reserved" 1 "Reserved" 0 "Reserved" ;
VAL_ 435 BCmFeature14SignalVal1 31 "Reserved" 30 "Reserved" 29 "Reserved" 28 "Reserved" 27 "Reserved" 26 "Reserved" 25 "Reserved" 24 "Reserved" 23 "Reserved" 22 "Reserved" 21 "Reserved" 20 "Reserved" 19 "Reserved" 18 "Reserved" 17 "Reserved" 16 "Reserved" 15 "Reserved" 14 "Reserved" 13 "Reserved" 12 "Reserved" 11 "Reserved" 10 "Reserved" 9 "Reserved" 8 "Reserved" 7 "Reserved" 6 "Reserved" 5 "Reserved" 4 "Reserved" 3 "Reserved" 2 "Reserved" 1 "Reserved" 0 "Reserved" ;
VAL_ 435 BCmFeature14State 1 "Feature 14 is enabled in BCM" 0 "Feature 14 is disabled in BCM" ;
VAL_ 435 BCmFeature14SignalVal3 31 "Reserved" 30 "Reserved" 29 "Reserved" 28 "Reserved" 27 "Reserved" 26 "Reserved" 25 "Reserved" 24 "Reserved" 23 "Reserved" 22 "Reserved" 21 "Reserved" 20 "Reserved" 19 "Reserved" 18 "Reserved" 17 "Reserved" 16 "Reserved" 15 "Reserved" 14 "Reserved" 13 "Reserved" 12 "Reserved" 11 "Reserved" 10 "Reserved" 9 "Reserved" 8 "Reserved" 7 "Reserved" 6 "Reserved" 5 "Reserved" 4 "Reserved" 3 "Reserved" 2 "Reserved" 1 "Reserved" 0 "Reserved" ;
VAL_ 435 BCmFeature15SignalVal1 31 "Reserved" 30 "Reserved" 29 "Reserved" 28 "Reserved" 27 "Reserved" 26 "Reserved" 25 "Reserved" 24 "Reserved" 23 "Reserved" 22 "Reserved" 21 "Reserved" 20 "Reserved" 19 "Reserved" 18 "Reserved" 17 "Reserved" 16 "Reserved" 15 "Reserved" 14 "Reserved" 13 "Reserved" 12 "Reserved" 11 "Reserved" 10 "Reserved" 9 "Reserved" 8 "Reserved" 7 "Reserved" 6 "Reserved" 5 "Reserved" 4 "Reserved" 3 "Reserved" 2 "Reserved" 1 "Reserved" 0 "Reserved" ;
VAL_ 435 BCmFeature15State 1 "Feature 15 is enabled in BCM" 0 "Feature 15 is disabled in BCM" ;
VAL_ 435 BCmFeature14ActiveSignalVal 3 "Reserved" 2 "Active value is BCmFeature14SignalVal3" 1 "Active value is BCmFeature14SignalVal2" 0 "Active value is BCmFeature14SignalVal1" ;
VAL_ 435 BCmFeature15SignalVal3 31 "Reserved" 30 "Reserved" 29 "Reserved" 28 "Reserved" 27 "Reserved" 26 "Reserved" 25 "Reserved" 24 "Reserved" 23 "Reserved" 22 "Reserved" 21 "Reserved" 20 "Reserved" 19 "Reserved" 18 "Reserved" 17 "Reserved" 16 "Reserved" 15 "Reserved" 14 "Reserved" 13 "Reserved" 12 "Reserved" 11 "Reserved" 10 "Reserved" 9 "Reserved" 8 "Reserved" 7 "Reserved" 6 "Reserved" 5 "Reserved" 4 "Reserved" 3 "Reserved" 2 "Reserved" 1 "Reserved" 0 "Reserved" ;
VAL_ 435 BCmFeature15SignalVal2 31 "Reserved" 30 "Reserved" 29 "Reserved" 28 "Reserved" 27 "Reserved" 26 "Reserved" 25 "Reserved" 24 "Reserved" 23 "Reserved" 22 "Reserved" 21 "Reserved" 20 "Reserved" 19 "Reserved" 18 "Reserved" 17 "Reserved" 16 "Reserved" 15 "Reserved" 14 "Reserved" 13 "Reserved" 12 "Reserved" 11 "Reserved" 10 "Reserved" 9 "Reserved" 8 "Reserved" 7 "Reserved" 6 "Reserved" 5 "Reserved" 4 "Reserved" 3 "Reserved" 2 "Reserved" 1 "Reserved" 0 "Reserved" ;
VAL_ 435 BCmFeature15ActiveSignalVal 3 "Reserved" 2 "Active value is BCmFeature15SignalVal3" 1 "Active value is BCmFeature15SignalVal2" 0 "Active value is BCmFeature15SignalVal1" ;
VAL_ 448 PDcHuRearTone 15 "Reserved for future use." 14 "Reserved for future use." 13 "Reserved for future use." 12 "Reserved for future use." 11 "Reserved for future use." 10 "Reserved for future use." 9 "Reserved for future use" 8 "Reserved for future use" 7 "Reserved for future use" 6 "Reserved for future use" 5 "Reserved for future use" 4 "Reserved for future use" 3 "Reserved for future use" 2 "Tone 3" 1 "Tone 2" 0 "Tone 1" ;
VAL_ 448 PDcHuRearNoOfSen 7 "Reserved for future" 6 "Reserved for future" 5 "Reserved for future" 4 "Reserved for future" 3 "Reserved for future" 2 "4 Sensors" 1 "3 Sensors" 0 "2 Sensors" ;
VAL_ 448 PDcHuVehicleImage 7 "Vehicle Image 8" 6 "Vehicle Image 7" 5 "Vehicle Image6" 4 "Vehicle Image 5" 3 "Vehicle Image4" 2 "Vehicle Image 3" 1 "Vehicle Image 2" 0 "Vehicle Image 1" ;
VAL_ 448 PDcHuFrontActivationState 1 "Active" 0 "Inactive" ;
VAL_ 448 PDcHuLowSpeedActivation 1 "Active" 0 "InActive" ;
VAL_ 448 PDcHuFrontNoOfSen 7 "Reserved for future" 6 "Reserved for future" 5 "Reserved for future" 4 "Reserved for future" 3 "Reserved for future" 2 "4 Sensors" 1 "3 Sensors" 0 "2 Sensors" ;
VAL_ 448 PDcHuFrontTone 15 "Reserved for future use." 14 "Reserved for future use." 13 "Reserved for future use." 12 "Reserved for future use." 11 "Reserved for future use." 10 "Reserved for future use." 9 "Reserved for future use" 8 "Reserved for future use" 7 "Reserved for future use" 6 "Reserved for future use" 5 "Reserved for future use" 4 "Reserved for future use" 3 "Reserved for future use" 2 "Tone 3" 1 "Tone 2" 0 "Tone 1" ;
VAL_ 448 PDcHuFrontAudioMuteState 1 "Mute" 0 "Unmute" ;
VAL_ 448 RVcImageRotationType 1 "180 degree rotation" 0 "No rotation" ;
VAL_ 448 RVcOverlayType 1 "Dynamic Overlay" 0 "Static Overlay" ;
VAL_ 454 IcHuTempUnitSet 1 "Fahrenheit" 0 "Celcius" ;
VAL_ 454 IcHuDistUnitSet 1 "Miles" 0 "Km" ;
VAL_ 454 IcHuFuelUnitSet 3 "SNA" 2 "mpg" 1 "ltr/100km" 0 "km/ltr" ;
VAL_ 454 IcHuClockMode 1 "24 Hour Mode" 0 "12 Hour Mode" ;
VAL_ 454 IcHuMonthInfo 15 "Reserved for future use." 14 "Reserved for future use." 13 "Reserved for future use." 12 "December" 11 "November" 10 "October" 9 "September" 8 "August" 7 "July" 6 "June" 5 "May" 4 "April" 3 "March" 2 "February" 1 "January" 0 "Unused" ;
VAL_ 454 IcLangSettings 31 "Reserved for future use" 30 "Reserved for future use" 29 "Reserved for future use" 28 "Reserved for future use" 27 "Reserved for future use" 26 "Reserved for future use" 25 "Reserved for future use" 24 "Reserved for future use" 23 "Reserved for future use" 22 "Reserved for future use" 21 "Reserved for future use" 20 "Reserved for future use" 19 "Reserved for future use" 18 "Reserved for future use" 17 "Reserved for future use" 16 "Reserved for future use" 15 "Reserved for future use" 14 "Reserved for future use" 13 "Albanian" 12 "Czech" 11 "Russian" 10 "Ukranian" 9 "Arabic" 8 "Turkish" 7 "Portugese" 6 "German" 5 "French" 4 "Polish" 3 "Italian" 2 "Spanish" 1 "UK English" 0 "Indian English" ;
VAL_ 457 OdoICSigAckFrm 1 "Odo Write Failure" 0 "Odo Write Successful" ;
VAL_ 459 BCmAntitheftFeatureState 1 "BCM Antitheft feature Activated" 0 "BCM Antitheft feature Deactivated" ;
VAL_ 459 BCmAntitheftKeyConfirmation 3 "Pairing not required" 2 "Pairing initiated" 1 "Pairing Successful" 0 "Pairing Unsuccessful" ;
VAL_ 459 BcmHuCkdState 1 "CKD vehicle" 0 "Non-CKD vehicle" ;
VAL_ 460 HuAntitheftFeatureState 1 "HU Antitheft feature activated" 0 "HU Antitheft feature Deactivated" ;
VAL_ 460 HuBcmQueryInfo 3 "Reserved for future use" 2 "Reserved for future use" 1 "HU request the BCM to resend values" 0 "No Query requested from HU to BCM" ;
VAL_ 464 HuIcDriveproConfig 3 "Reserved" 2 "Reserved" 1 "DrivePro Present" 0 "DrivePro Not Present" ;
VAL_ 464 HuIcDriveProConfigEventStatus 1 "Config Event" 0 "No Event" ;
VAL_ 464 HuIcTripAReset 1 "Yes" 0 "No" ;
VAL_ 464 HuIcTripAResetAck 1 "Yes" 0 "No" ;
VAL_ 464 HuIcTripBReset 1 "Yes" 0 "No" ;
VAL_ 464 HuIcTripBResetAck 1 "Yes" 0 "No" ;
VAL_ 464 HuIcResetAll 1 "Yes" 0 "No" ;
VAL_ 464 HuIcTripResetAckEventStatus 1 "ResetAck Event" 0 "No Event" ;
VAL_ 464 HuIcTripResetEventStatus 1 "Reset Event" 0 "No Event" ;
VAL_ 464 HuIcOverallTripReset 1 "Yes" 0 "No" ;
VAL_ 464 HuIcOverallTripResetAck 1 "Yes" 0 "No" ;
VAL_ 464 HuIcResetAllAck 1 "Yes" 0 "No" ;
VAL_ 466 HuPDcVehicleImageAck 7 "Vehicle Image 8" 6 "Vehicle Image 7" 5 "Vehicle Image6" 4 "Vehicle Image 5" 3 "Vehicle Image4" 2 "Vehicle Image 3" 1 "Vehicle Image 2" 0 "Vehicle Image 1" ;
VAL_ 466 PDcLowSpeedActivationReq 1 "active" 0 "Inactive" ;
VAL_ 466 PDcRearToneReq 15 "Reserved for future use." 14 "Reserved for future use." 13 "Reserved for future use." 12 "Reserved for future use." 11 "Reserved for future use." 10 "Reserved for future use." 9 "Reserved for future use." 8 "Reserved for future use." 7 "Reserved for future use." 6 "Reserved for future use." 5 "Reserved for future use." 4 "Reserved for future use." 3 "Reserved for future use." 2 "Tone 3" 1 "Tone 2" 0 "Tone 1" ;
VAL_ 466 HuPDcFrontAudioMuteStateAck 1 "Mute" 0 "Unmute" ;
VAL_ 466 HuPDcRearNoOfSensAck 7 "Reserved for future" 6 "Reserved for future" 5 "Reserved for future" 4 "Reserved for future" 3 "Reserved for future" 2 "4 Sensors" 1 "3 Sensors" 0 "2 Sensors" ;
VAL_ 466 PDcFrontAudioMuteReq 1 "Mute" 0 "Unmute" ;
VAL_ 466 HuPDcReqType 7 "reserved" 6 "reserved" 5 "HUPDCconfig Ack" 4 "setting update" 3 "config query" 2 "factory setting Req" 1 "HU_PDC Deactivate Req" 0 "HU_PDC Activate Req" ;
VAL_ 466 HuPDcRearToneAck 15 "Reserved for future use." 14 "Reserved for future use." 13 "Reserved for future use." 12 "Reserved for future use." 11 "Reserved for future use." 10 "Reserved for future use." 9 "Reserved for future use." 8 "Reserved for future use." 7 "Reserved for future use." 6 "Reserved for future use." 5 "Reserved for future use." 4 "Reserved for future use." 3 "Reserved for future use." 2 "Tone 3" 1 "Tone 2" 0 "Tone 1" ;
VAL_ 466 HuPDcFrontToneAck 15 "Reserved for future use." 14 "Reserved for future use." 13 "Reserved for future use." 12 "Reserved for future use." 11 "Reserved for future use." 10 "Reserved for future use." 9 "Reserved for future use." 8 "Reserved for future use." 7 "Reserved for future use." 6 "Reserved for future use." 5 "Reserved for future use." 4 "Reserved for future use." 3 "Reserved for future use." 2 "Tone 3" 1 "Tone 2" 0 "Tone 1		" ;
VAL_ 466 HuPDcFrontNoOfSensAck 7 "Reserved for future use." 6 "Reserved for future use." 5 "Reserved for future use." 4 "Reserved for future use." 3 "Reserved for future use." 2 "4 Sensors" 1 "3 Sensors" 0 "2 Sensors" ;
VAL_ 466 PDcFrontToneReq 15 "Reserved for future use." 14 "Reserved for future use." 13 "Reserved for future use." 12 "Reserved for future use." 11 "Reserved for future use." 10 "Reserved for future use." 9 "Reserved for future use" 8 "Reserved for future use" 7 "Reserved for future use" 6 "Reserved for future use" 5 "Reserved for future use" 4 "Reserved for future use" 3 "Reserved for future use" 2 "Tone 3" 1 "Tone 2" 0 "Tone 1" ;
VAL_ 466 HuPDCFrontActivationStateAck 1 "Active" 0 "Inactive" ;
VAL_ 466 PDcFrontActivationStateReq 1 "Active" 0 "Inactive" ;
VAL_ 466 HuPDCLowSpeedActivationAck 1 "Active" 0 "Inactive" ;
VAL_ 466 RVcOverlayTypeAck 1 "Dynamic Overlay" 0 "Static Overlay" ;
VAL_ 466 RVcImageRotationTypeAck 1 "180 degree rotation" 0 "No rotation" ;
VAL_ 469 HuIcTempUnitSet 1 "Fahrenheit" 0 "Celcius" ;
VAL_ 469 HuIcDistUnitSet 1 "Miles" 0 "Km" ;
VAL_ 469 HuIcFuelUnitSet 3 "SNA" 2 "mpg" 1 "ltr/100km" 0 "Km/hr" ;
VAL_ 469 HuIcClockMode 1 "24 Hour Mode" 0 "12 Hour Mode" ;
VAL_ 469 QueryIcHuUnitSetInfo 1 " Query" 0 "No Query" ;
VAL_ 469 HuIcRtcTypeNew 1 "No RTC" 0 "RTC" ;
VAL_ 469 HuIcMonthInfo 15 "Reserved for future use." 14 "Reserved for future use." 13 "Reserved for future use." 12 "December" 11 "November" 10 "October" 9 "September" 8 "August" 7 "July" 6 "June" 5 "May" 4 "April" 3 "March" 2 "February" 1 "January" 0 "Unused" ;
VAL_ 469 HuLangSettings 31 "Reserved for future use" 30 "Reserved for future use" 29 "Reserved for future use" 28 "Reserved for future use" 27 "Reserved for future use" 26 "Reserved for future use" 25 "Reserved for future use" 24 "Reserved for future use" 23 "Reserved for future use" 22 "Reserved for future use" 21 "Reserved for future use" 20 "Reserved for future use" 19 "Reserved for future use" 18 "Reserved for future use" 17 "Reserved for future use" 16 "Reserved for future use" 15 "Reserved for future use" 14 "Reserved for future use" 13 "Albanian" 12 "Czech" 11 "Russian" 10 "Ukranian" 9 "Arabic" 8 "Turkish" 7 "Portugese" 6 "German" 5 "French" 4 "Polish" 3 "Italian" 2 "Spanish" 1 "UK English" 0 "Indian English" ;
VAL_ 469 HuIcRtcType 1 "RTC" 0 "No RTC" ;
VAL_ 470 HuIcTempUnitSetAck 1 "Fahrenheit" 0 "Celcius" ;
VAL_ 470 HuIcFuelUnitSetAck 3 "SNA" 2 "mpg" 1 "ltr/100km" 0 "Km/hr" ;
VAL_ 470 HuIcDistUnitSetAck 1 "Miles" 0 "Km" ;
VAL_ 472 CcmHuRearBlwrConfig 1 "Rear Blower feature Available" 0 "Rear Blower feature Not Available" ;
VAL_ 472 CCmHuEconConfig 1 "ECON Cooling feature Not Available" 0 "ECON Cooling feature Available" ;
VAL_ 472 CCmHuExpressCoolConfig 1 "Express Cooling feature Available" 0 "Express Cooling feature Not Available" ;
VAL_ 472 CCmHuLowFanSpdConfigValue 15 "Reserved" 14 "Reserved" 13 "Reserved" 12 "Reserved" 11 "Reserved" 10 "Reserved" 9 "Reserved" 8 "Speed 8" 7 "Speed 7" 6 "Speed 6" 5 "Speed 5" 4 "Speed 4" 3 "Speed 3" 2 "Speed 2" 1 "Speed 1" 0 "Speed 0" ;
VAL_ 472 CCmHuHiFanSpdConfigValue 15 "Reserved" 14 "Reserved" 13 "Reserved" 12 "Reserved" 11 "Reserved" 10 "Reserved" 9 "Reserved" 8 "Speed 8" 7 "Speed 7" 6 "Speed 6" 5 "Speed 5" 4 "Speed 4" 3 "Speed 3" 2 "Speed 2" 1 "Speed 1" 0 "Speed 0" ;
VAL_ 472 CCmHuLowTempConfigValue 31 "HI" 30 "Reserved" 29 "30 Deg C" 28 "29.5 Deg C" 27 "29 Deg C" 26 "28.5 Deg C" 25 "28 Deg C" 24 "27.5 Deg C" 23 "27 Deg C" 22 "26.5 Deg C" 21 "26 Deg C" 20 "25.5 Deg C" 19 "25 Deg C" 18 "24.5 Deg C" 17 "24 Deg C" 16 "23.5 Deg C" 15 "23 Deg C" 14 "22.5 Deg C" 13 "22 Deg C" 12 "21.5 Deg C" 11 "21 Deg C" 10 "20.5 Deg C" 9 "20 Deg C" 8 "19.5 Deg C" 7 "19 Deg C" 6 "18.5 Deg C" 5 "18 Deg C" 4 "17.5 Deg C" 3 "17 Deg C" 2 "16.5 Deg C" 1 "16 Deg C" 0 "LO" ;
VAL_ 472 CCmHuHiTempConfigValue 31 "HI" 30 "Reserved" 29 "30 Deg C" 28 "29.5 Deg C" 27 "29 Deg C" 26 "28.5 Deg C" 25 "28 Deg C" 24 "27.5 Deg C" 23 "27 Deg C" 22 "26.5 Deg C" 21 "26 Deg C" 20 "25.5 Deg C" 19 "25 Deg C" 18 "24.5 Deg C" 17 "24 Deg C" 16 "23.5 Deg C" 15 "23 Deg C" 14 "22.5 Deg C" 13 "22 Deg C" 12 "21.5 Deg C" 11 "21 Deg C" 10 "20.5 Deg C" 9 "20 Deg C" 8 "19.5 Deg C" 7 "19 Deg C" 6 "18.5 Deg C" 5 "18 Deg C" 4 "17.5 Deg C" 3 "17 Deg C" 2 "16.5 Deg C" 1 "16 Deg C" 0 "LO" ;
VAL_ 474 HuCcmRearBlwrConfigAck 1 "Rear Blower feature  available configuration acknowledgement" 0 "Rear Blower feature Not available configuration acknowledgement" ;
VAL_ 474 HuCcmEconConfigAck 1 "ECON feature Not available configuration acknowledgement" 0 "ECON feature available configuration acknowledgement" ;
VAL_ 474 HuCcmExpressCoolConfigAck 1 "Express Cooling feature Available configuration acknowledgement" 0 "Express Cooling feature Not Available configuration acknowledgement" ;
VAL_ 474 HuCCmLowFanSpdConfigValueAck 15 "Reserved" 14 "Reserved" 13 "Reserved" 12 "Reserved" 11 "Reserved" 10 "Reserved" 9 "Reserved" 8 "Speed 8" 7 "Speed 7" 6 "Speed 6" 5 "Speed 5" 4 "Speed 4" 3 "Speed 3" 2 "Speed 2" 1 "Speed 1" 0 "Speed 0" ;
VAL_ 474 HuCCmHiFanSpdConfigValueAck 15 "Reserved" 14 "Reserved" 13 "Reserved" 12 "Reserved" 11 "Reserved" 10 "Reserved" 9 "Reserved" 8 "Speed 8" 7 "Speed 7" 6 "Speed 6" 5 "Speed 5" 4 "Speed 4" 3 "Speed 3" 2 "Speed 2" 1 "Speed 1" 0 "Speed 0" ;
VAL_ 474 HuCCmLowTempConfigValueAck 31 "HI" 30 "Reserved" 29 "30 Deg C" 28 "29.5 Deg C" 27 "29 Deg C" 26 "28.5 Deg C" 25 "28 Deg C" 24 "27.5 Deg C" 23 "27 Deg C" 22 "26.5 Deg C" 21 "26 Deg C" 20 "25.5 Deg C" 19 "25 Deg C" 18 "24.5 Deg C" 17 "24 Deg C" 16 "23.5 Deg C" 15 "23 Deg C" 14 "22.5 Deg C" 13 "22 Deg C" 12 "21.5 Deg C" 11 "21 Deg C" 10 "20.5 Deg C" 9 "20 Deg C" 8 "19.5 Deg C" 7 "19 Deg C" 6 "18.5 Deg C" 5 "18 Deg C" 4 "17.5 Deg C" 3 "17 Deg C" 2 "16.5 Deg C" 1 "16 Deg C" 0 "LO" ;
VAL_ 474 HuCCmFanControlDuringVRAck 3 "Reserved" 2 "Available" 1 "Not Available" 0 "Reserved" ;
VAL_ 474 HuCCmHiTempConfigValueAck 31 "HI" 30 "Reserved" 29 "30 Deg C" 28 "29.5 Deg C" 27 "29 Deg C" 26 "28.5 Deg C" 25 "28 Deg C" 24 "27.5 Deg C" 23 "27 Deg C" 22 "26.5 Deg C" 21 "26 Deg C" 20 "25.5 Deg C" 19 "25 Deg C" 18 "24.5 Deg C" 17 "24 Deg C" 16 "23.5 Deg C" 15 "23 Deg C" 14 "22.5 Deg C" 13 "22 Deg C" 12 "21.5 Deg C" 11 "21 Deg C" 10 "20.5 Deg C" 9 "20 Deg C" 8 "19.5 Deg C" 7 "19 Deg C" 6 "18.5 Deg C" 5 "18 Deg C" 4 "17.5 Deg C" 3 "17 Deg C" 2 "16.5 Deg C" 1 "16 Deg C" 0 "LO" ;
